VERSION ""

NS_ :

BS_:

BU_: VMCU TECU TACHO RECU_Virt IC3 HPCU EMS EBS DACU CIOM BBM ACM

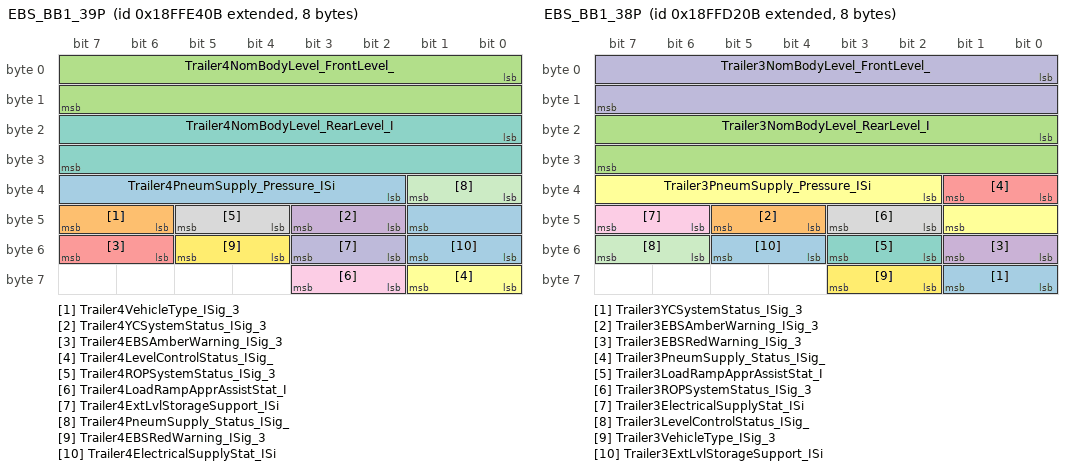
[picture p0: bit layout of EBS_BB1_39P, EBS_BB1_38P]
BO_ 2566906891 EBS_BB1_39P: 8 EBS
 SG_ Trailer4PneumSupply_Pressure_ISi : 34|8@1+ (5,0) [0|1275] "kPa"  IC3
 SG_ Trailer4VehicleType_ISig_3 : 46|2@1+ (1,0) [0|0] ""  IC3
 SG_ Trailer4NomBodyLevel_FrontLevel_ : 0|16@1+ (1,0) [0|65535] "mm"  IC3
 SG_ Trailer4YCSystemStatus_ISig_3 : 42|2@1+ (1,0) [0|0] ""  IC3
 SG_ Trailer4EBSAmberWarning_ISig_3 : 54|2@1+ (1,0) [0|0] ""  IC3
 SG_ Trailer4LevelControlStatus_ISig_ : 56|2@1+ (1,0) [0|0] ""  IC3
 SG_ Trailer4NomBodyLevel_RearLevel_I : 16|16@1+ (1,0) [0|65535] "mm"  IC3
 SG_ Trailer4ROPSystemStatus_ISig_3 : 44|2@1+ (1,0) [0|0] ""  IC3
 SG_ Trailer4LoadRampApprAssistStat_I : 58|2@1+ (1,0) [0|0] ""  IC3
 SG_ Trailer4ExtLvlStorageSupport_ISi : 50|2@1+ (1,0) [0|0] ""  IC3
 SG_ Trailer4PneumSupply_Status_ISig_ : 32|2@1+ (1,0) [0|0] ""  IC3
 SG_ Trailer4EBSRedWarning_ISig_3 : 52|2@1+ (1,0) [0|0] ""  IC3
 SG_ Trailer4ElectricalSupplyStat_ISi : 48|2@1+ (1,0) [0|0] ""  IC3

BO_ 2566902283 EBS_BB1_38P: 8 EBS
 SG_ Trailer3YCSystemStatus_ISig_3 : 56|2@1+ (1,0) [0|0] ""  IC3
 SG_ Trailer3EBSAmberWarning_ISig_3 : 44|2@1+ (1,0) [0|0] ""  IC3
 SG_ Trailer3NomBodyLevel_RearLevel_I : 16|16@1+ (1,0) [0|65535] "mm"  IC3
 SG_ Trailer3EBSRedWarning_ISig_3 : 48|2@1+ (1,0) [0|0] ""  IC3
 SG_ Trailer3PneumSupply_Status_ISig_ : 32|2@1+ (1,0) [0|0] ""  IC3
 SG_ Trailer3PneumSupply_Pressure_ISi : 34|8@1+ (5,0) [0|1275] "kPa"  IC3
 SG_ Trailer3LoadRampApprAssistStat_I : 50|2@1+ (1,0) [0|0] ""  IC3
 SG_ Trailer3ROPSystemStatus_ISig_3 : 42|2@1+ (1,0) [0|0] ""  IC3
 SG_ Trailer3ElectricalSupplyStat_ISi : 46|2@1+ (1,0) [0|0] ""  IC3
 SG_ Trailer3NomBodyLevel_FrontLevel_ : 0|16@1+ (1,0) [0|65535] "mm"  IC3
 SG_ Trailer3LevelControlStatus_ISig_ : 54|2@1+ (1,0) [0|0] ""  IC3
 SG_ Trailer3VehicleType_ISig_3 : 58|2@1+ (1,0) [0|0] ""  IC3
 SG_ Trailer3ExtLvlStorageSupport_ISi : 52|2@1+ (1,0) [0|0] ""  IC3

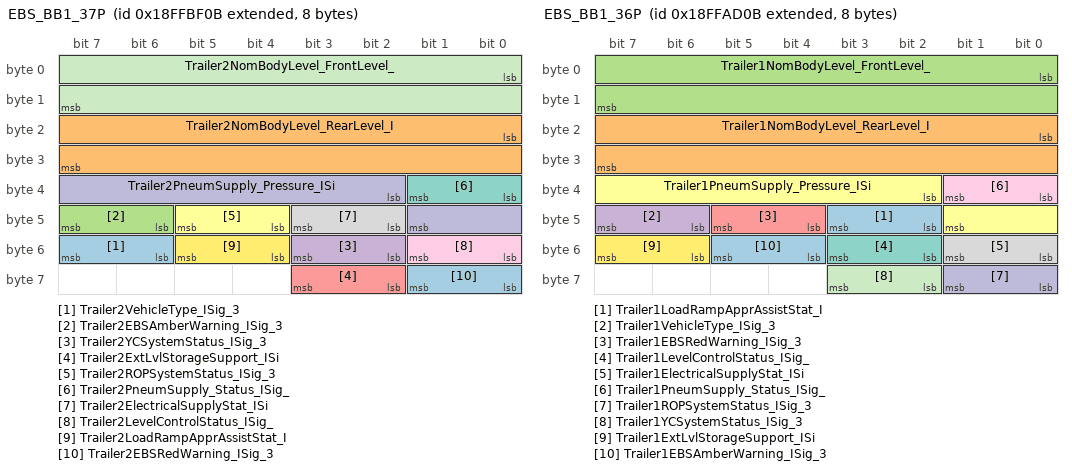
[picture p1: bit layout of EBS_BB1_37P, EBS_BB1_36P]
BO_ 2566897419 EBS_BB1_37P: 8 EBS
 SG_ Trailer2VehicleType_ISig_3 : 54|2@1+ (1,0) [0|0] ""  IC3
 SG_ Trailer2NomBodyLevel_RearLevel_I : 16|16@1+ (1,0) [0|65535] "mm"  IC3
 SG_ Trailer2EBSAmberWarning_ISig_3 : 46|2@1+ (1,0) [0|0] ""  IC3
 SG_ Trailer2YCSystemStatus_ISig_3 : 50|2@1+ (1,0) [0|0] ""  IC3
 SG_ Trailer2ExtLvlStorageSupport_ISi : 58|2@1+ (1,0) [0|0] ""  IC3
 SG_ Trailer2ROPSystemStatus_ISig_3 : 44|2@1+ (1,0) [0|0] ""  IC3
 SG_ Trailer2PneumSupply_Status_ISig_ : 32|2@1+ (1,0) [0|0] ""  IC3
 SG_ Trailer2ElectricalSupplyStat_ISi : 42|2@1+ (1,0) [0|0] ""  IC3
 SG_ Trailer2LevelControlStatus_ISig_ : 48|2@1+ (1,0) [0|0] ""  IC3
 SG_ Trailer2PneumSupply_Pressure_ISi : 34|8@1+ (5,0) [0|1275] "kPa"  IC3
 SG_ Trailer2NomBodyLevel_FrontLevel_ : 0|16@1+ (1,0) [0|65535] "mm"  IC3
 SG_ Trailer2LoadRampApprAssistStat_I : 52|2@1+ (1,0) [0|0] ""  IC3
 SG_ Trailer2EBSRedWarning_ISig_3 : 56|2@1+ (1,0) [0|0] ""  IC3

BO_ 2566892811 EBS_BB1_36P: 8 EBS
 SG_ Trailer1LoadRampApprAssistStat_I : 42|2@1+ (1,0) [0|0] ""  IC3
 SG_ Trailer1NomBodyLevel_RearLevel_I : 16|16@1+ (1,0) [0|65535] "mm"  IC3
 SG_ Trailer1NomBodyLevel_FrontLevel_ : 0|16@1+ (1,0) [0|65535] "mm"  IC3
 SG_ Trailer1VehicleType_ISig_3 : 46|2@1+ (1,0) [0|0] ""  IC3
 SG_ Trailer1EBSRedWarning_ISig_3 : 44|2@1+ (1,0) [0|0] ""  IC3
 SG_ Trailer1PneumSupply_Pressure_ISi : 34|8@1+ (5,0) [0|1275] "kPa"  IC3
 SG_ Trailer1LevelControlStatus_ISig_ : 50|2@1+ (1,0) [0|0] ""  IC3
 SG_ Trailer1ElectricalSupplyStat_ISi : 48|2@1+ (1,0) [0|0] ""  IC3
 SG_ Trailer1PneumSupply_Status_ISig_ : 32|2@1+ (1,0) [0|0] ""  IC3
 SG_ Trailer1ROPSystemStatus_ISig_3 : 56|2@1+ (1,0) [0|0] ""  IC3
 SG_ Trailer1YCSystemStatus_ISig_3 : 58|2@1+ (1,0) [0|0] ""  IC3
 SG_ Trailer1ExtLvlStorageSupport_ISi : 54|2@1+ (1,0) [0|0] ""  IC3
 SG_ Trailer1EBSAmberWarning_ISig_3 : 52|2@1+ (1,0) [0|0] ""  IC3

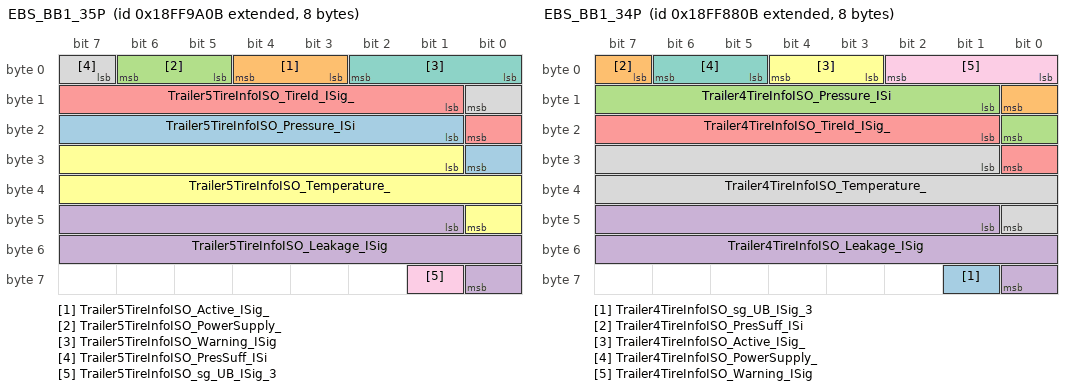
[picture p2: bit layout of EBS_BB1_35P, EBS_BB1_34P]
BO_ 2566887947 EBS_BB1_35P: 8 EBS
 SG_ Trailer5TireInfoISO_Pressure_ISi : 17|8@1+ (10,0) [0|2550] "kPa"  IC3
 SG_ Trailer5TireInfoISO_Active_ISig_ : 3|2@1+ (1,0) [0|0] ""  IC3
 SG_ Trailer5TireInfoISO_PowerSupply_ : 5|2@1+ (1,0) [0|0] ""  IC3
 SG_ Trailer5TireInfoISO_Leakage_ISig : 41|16@1+ (0.1,0) [0|6553.5] "Pa_per_s"  IC3
 SG_ Trailer5TireInfoISO_TireId_ISig_ : 9|8@1+ (1,0) [0|255] "NotApplicable"  IC3
 SG_ Trailer5TireInfoISO_Temperature_ : 25|16@1+ (0.03125,-273) [-273|1774.96875] "DegreeC"  IC3
 SG_ Trailer5TireInfoISO_Warning_ISig : 0|3@1+ (1,0) [0|0] ""  IC3
 SG_ Trailer5TireInfoISO_PresSuff_ISi : 7|2@1+ (1,0) [0|0] ""  IC3
 SG_ Trailer5TireInfoISO_sg_UB_ISig_3 : 57|1@1+ (1,0) [0|0] ""  IC3

BO_ 2566883339 EBS_BB1_34P: 8 EBS
 SG_ Trailer4TireInfoISO_sg_UB_ISig_3 : 57|1@1+ (1,0) [0|0] ""  IC3
 SG_ Trailer4TireInfoISO_PresSuff_ISi : 7|2@1+ (1,0) [0|0] ""  IC3
 SG_ Trailer4TireInfoISO_Pressure_ISi : 9|8@1+ (10,0) [0|2550] "kPa"  IC3
 SG_ Trailer4TireInfoISO_Leakage_ISig : 41|16@1+ (0.1,0) [0|6553.5] "Pa_per_s"  IC3
 SG_ Trailer4TireInfoISO_TireId_ISig_ : 17|8@1+ (1,0) [0|255] "NotApplicable"  IC3
 SG_ Trailer4TireInfoISO_Active_ISig_ : 3|2@1+ (1,0) [0|0] ""  IC3
 SG_ Trailer4TireInfoISO_PowerSupply_ : 5|2@1+ (1,0) [0|0] ""  IC3
 SG_ Trailer4TireInfoISO_Temperature_ : 25|16@1+ (0.03125,-273) [-273|1774.96875] "DegreeC"  IC3
 SG_ Trailer4TireInfoISO_Warning_ISig : 0|3@1+ (1,0) [0|0] ""  IC3

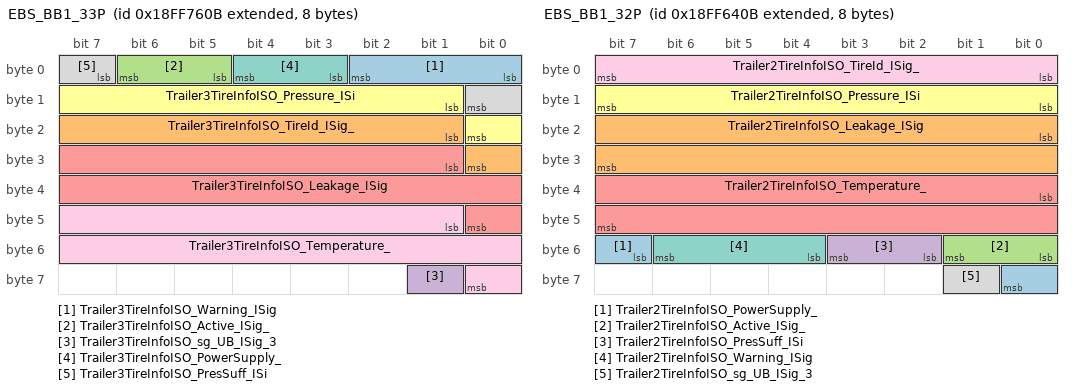
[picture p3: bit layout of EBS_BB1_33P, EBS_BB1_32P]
BO_ 2566878731 EBS_BB1_33P: 8 EBS
 SG_ Trailer3TireInfoISO_Warning_ISig : 0|3@1+ (1,0) [0|0] ""  IC3
 SG_ Trailer3TireInfoISO_TireId_ISig_ : 17|8@1+ (1,0) [0|255] "NotApplicable"  IC3
 SG_ Trailer3TireInfoISO_Active_ISig_ : 5|2@1+ (1,0) [0|0] ""  IC3
 SG_ Trailer3TireInfoISO_sg_UB_ISig_3 : 57|1@1+ (1,0) [0|0] ""  IC3
 SG_ Trailer3TireInfoISO_Leakage_ISig : 25|16@1+ (0.1,0) [0|6553.5] "Pa_per_s"  IC3
 SG_ Trailer3TireInfoISO_Pressure_ISi : 9|8@1+ (10,0) [0|2550] "kPa"  IC3
 SG_ Trailer3TireInfoISO_PowerSupply_ : 3|2@1+ (1,0) [0|0] ""  IC3
 SG_ Trailer3TireInfoISO_PresSuff_ISi : 7|2@1+ (1,0) [0|0] ""  IC3
 SG_ Trailer3TireInfoISO_Temperature_ : 41|16@1+ (0.03125,-273) [-273|1774.96875] "DegreeC"  IC3

BO_ 2566874123 EBS_BB1_32P: 8 EBS
 SG_ Trailer2TireInfoISO_PowerSupply_ : 55|2@1+ (1,0) [0|0] ""  IC3
 SG_ Trailer2TireInfoISO_Leakage_ISig : 16|16@1+ (0.1,0) [0|6553.5] "Pa_per_s"  IC3
 SG_ Trailer2TireInfoISO_Active_ISig_ : 48|2@1+ (1,0) [0|0] ""  IC3
 SG_ Trailer2TireInfoISO_PresSuff_ISi : 50|2@1+ (1,0) [0|0] ""  IC3
 SG_ Trailer2TireInfoISO_Temperature_ : 32|16@1+ (0.03125,-273) [-273|1774.96875] "DegreeC"  IC3
 SG_ Trailer2TireInfoISO_Pressure_ISi : 8|8@1+ (10,0) [0|2550] "kPa"  IC3
 SG_ Trailer2TireInfoISO_Warning_ISig : 52|3@1+ (1,0) [0|0] ""  IC3
 SG_ Trailer2TireInfoISO_sg_UB_ISig_3 : 57|1@1+ (1,0) [0|0] ""  IC3
 SG_ Trailer2TireInfoISO_TireId_ISig_ : 0|8@1+ (1,0) [0|255] "NotApplicable"  IC3

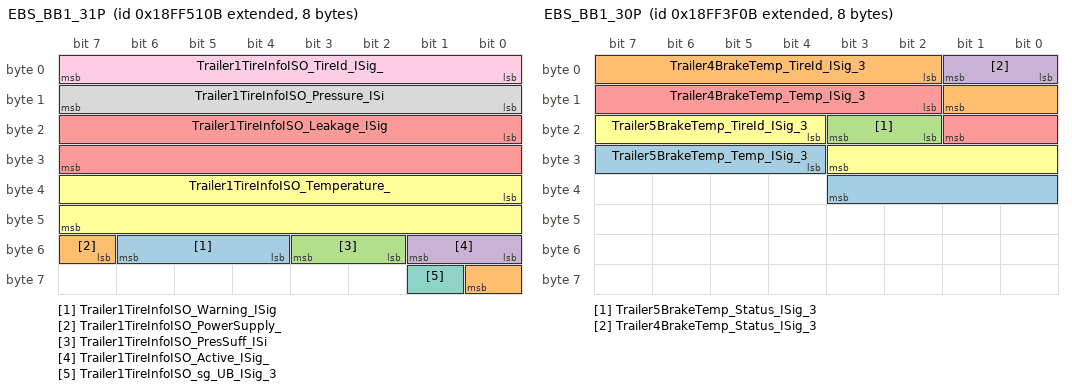
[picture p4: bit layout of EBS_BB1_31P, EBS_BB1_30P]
BO_ 2566869259 EBS_BB1_31P: 8 EBS
 SG_ Trailer1TireInfoISO_Warning_ISig : 52|3@1+ (1,0) [0|0] ""  IC3
 SG_ Trailer1TireInfoISO_PowerSupply_ : 55|2@1+ (1,0) [0|0] ""  IC3
 SG_ Trailer1TireInfoISO_PresSuff_ISi : 50|2@1+ (1,0) [0|0] ""  IC3
 SG_ Trailer1TireInfoISO_Active_ISig_ : 48|2@1+ (1,0) [0|0] ""  IC3
 SG_ Trailer1TireInfoISO_Leakage_ISig : 16|16@1+ (0.1,0) [0|6553.5] "Pa_per_s"  IC3
 SG_ Trailer1TireInfoISO_Temperature_ : 32|16@1+ (0.03125,-273) [-273|1774.96875] "DegreeC"  IC3
 SG_ Trailer1TireInfoISO_sg_UB_ISig_3 : 57|1@1+ (1,0) [0|0] ""  IC3
 SG_ Trailer1TireInfoISO_Pressure_ISi : 8|8@1+ (10,0) [0|2550] "kPa"  IC3
 SG_ Trailer1TireInfoISO_TireId_ISig_ : 0|8@1+ (1,0) [0|255] "NotApplicable"  IC3

BO_ 2566864651 EBS_BB1_30P: 8 EBS
 SG_ Trailer5BrakeTemp_Temp_ISig_3 : 28|8@1+ (10,0) [0|2550] "DegreeC"  IC3
 SG_ Trailer4BrakeTemp_TireId_ISig_3 : 2|8@1+ (1,0) [0|255] "NotApplicable"  IC3
 SG_ Trailer5BrakeTemp_Status_ISig_3 : 18|2@1+ (1,0) [0|0] ""  IC3
 SG_ Trailer4BrakeTemp_Status_ISig_3 : 0|2@1+ (1,0) [0|0] ""  IC3
 SG_ Trailer4BrakeTemp_Temp_ISig_3 : 10|8@1+ (10,0) [0|2550] "DegreeC"  IC3
 SG_ Trailer5BrakeTemp_TireId_ISig_3 : 20|8@1+ (1,0) [0|255] "NotApplicable"  IC3

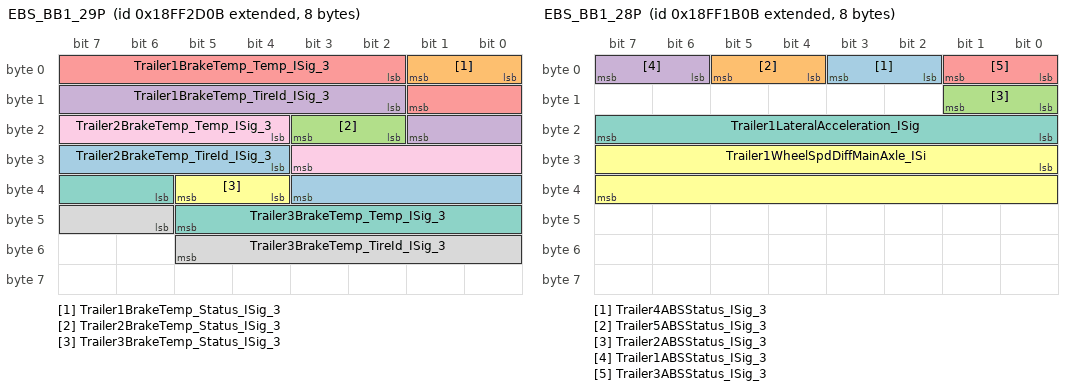
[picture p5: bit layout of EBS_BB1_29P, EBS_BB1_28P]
BO_ 2566860043 EBS_BB1_29P: 8 EBS
 SG_ Trailer2BrakeTemp_TireId_ISig_3 : 28|8@1+ (1,0) [0|255] "NotApplicable"  IC3
 SG_ Trailer1BrakeTemp_Status_ISig_3 : 0|2@1+ (1,0) [0|0] ""  IC3
 SG_ Trailer2BrakeTemp_Status_ISig_3 : 18|2@1+ (1,0) [0|0] ""  IC3
 SG_ Trailer1BrakeTemp_TireId_ISig_3 : 10|8@1+ (1,0) [0|255] "NotApplicable"  IC3
 SG_ Trailer1BrakeTemp_Temp_ISig_3 : 2|8@1+ (10,0) [0|2550] "DegreeC"  IC3
 SG_ Trailer3BrakeTemp_Status_ISig_3 : 36|2@1+ (1,0) [0|0] ""  IC3
 SG_ Trailer3BrakeTemp_Temp_ISig_3 : 38|8@1+ (10,0) [0|2550] "DegreeC"  IC3
 SG_ Trailer3BrakeTemp_TireId_ISig_3 : 46|8@1+ (1,0) [0|255] "NotApplicable"  IC3
 SG_ Trailer2BrakeTemp_Temp_ISig_3 : 20|8@1+ (10,0) [0|2550] "DegreeC"  IC3

BO_ 2566855435 EBS_BB1_28P: 8 EBS
 SG_ Trailer4ABSStatus_ISig_3 : 2|2@1+ (1,0) [0|0] ""  IC3
 SG_ Trailer5ABSStatus_ISig_3 : 4|2@1+ (1,0) [0|0] ""  IC3
 SG_ Trailer2ABSStatus_ISig_3 : 8|2@1+ (1,0) [0|0] ""  IC3
 SG_ Trailer1ABSStatus_ISig_3 : 6|2@1+ (1,0) [0|0] ""  IC3
 SG_ Trailer3ABSStatus_ISig_3 : 0|2@1+ (1,0) [0|0] ""  IC3
 SG_ Trailer1WheelSpdDiffMainAxle_ISi : 24|16@1+ (0.00390625,-125) [-125|130.99609375] "Km_per_h"  IC3
 SG_ Trailer1LateralAcceleration_ISig : 16|8@1+ (0.1,-12.5) [-12.5|13] "m_per_s_squared"  IC3

BO_ 2566850827 EBS_BB1_27P: 8 EBS
 SG_ Trailer5NormalLevelStorStat_ISig : 6|2@1+ (1,0) [0|0] ""  IC3
 SG_ Trailer4TractionHelp_ISig_3 : 42|2@1+ (1,0) [0|0] ""  IC3
 SG_ Trailer2TractionHelp_ISig_3 : 4|2@1+ (1,0) [0|0] ""  IC3
 SG_ Trailer3StopLevelChangeAck_ISig_ : 44|2@1+ (1,0) [0|0] ""  IC3
 SG_ Trailer4LevelChangeFrontAxle_ISi : 40|2@1+ (1,0) [0|0] ""  IC3
 SG_ Trailer1NormalLevelStorStat_ISig : 10|2@1+ (1,0) [0|0] ""  IC3
 SG_ Trailer1StopLevelChangeAck_ISig_ : 50|2@1+ (1,0) [0|0] ""  IC3
 SG_ Trailer3LevelChangeFrontAxle_ISi : 38|2@1+ (1,0) [0|0] ""  IC3
 SG_ Trailer5RampLevelStorStat_ISig_3 : 8|2@1+ (1,0) [0|0] ""  IC3
 SG_ Trailer4LevelChangeRearAxle_ISig : 36|2@1+ (1,0) [0|0] ""  IC3
 SG_ Trailer2LevelChangeFrontAxle_ISi : 34|2@1+ (1,0) [0|0] ""  IC3
 SG_ Trailer2RampLevelStorStat_ISig_3 : 14|2@1+ (1,0) [0|0] ""  IC3
 SG_ Trailer4StopLevelChangeAck_ISig_ : 18|2@1+ (1,0) [0|0] ""  IC3
 SG_ Trailer3NormalLevelStorStat_ISig : 56|2@1+ (1,0) [0|0] ""  IC3
 SG_ Trailer1TractionHelp_ISig_3 : 20|2@1+ (1,0) [0|0] ""  IC3
 SG_ Trailer1LevelChangeRearAxle_ISig : 54|2@1+ (1,0) [0|0] ""  IC3
 SG_ Trailer5LevelChangeFrontAxle_ISi : 26|2@1+ (1,0) [0|0] ""  IC3
 SG_ Trailer5StopLevelChangeAck_ISig_ : 24|2@1+ (1,0) [0|0] ""  IC3
 SG_ Trailer5TractionHelp_ISig_3 : 58|2@1+ (1,0) [0|0] ""  IC3
 SG_ Trailer3RampLevelStorStat_ISig_3 : 12|2@1+ (1,0) [0|0] ""  IC3
 SG_ Trailer2LevelChangeRearAxle_ISig : 30|2@1+ (1,0) [0|0] ""  IC3
 SG_ Trailer2StopLevelChangeAck_ISig_ : 22|2@1+ (1,0) [0|0] ""  IC3
 SG_ Trailer3TractionHelp_ISig_3 : 32|2@1+ (1,0) [0|0] ""  IC3
 SG_ Trailer4RampLevelStorStat_ISig_3 : 28|2@1+ (1,0) [0|0] ""  IC3
 SG_ Trailer1RampLevelStorStat_ISig_3 : 52|2@1+ (1,0) [0|0] ""  IC3
 SG_ Trailer1LevelChangeFrontAxle_ISi : 16|2@1+ (1,0) [0|0] ""  IC3
 SG_ Trailer3LevelChangeRearAxle_ISig : 0|2@1+ (1,0) [0|0] ""  IC3
 SG_ Trailer5LevelChangeRearAxle_ISig : 48|2@1+ (1,0) [0|0] ""  IC3
 SG_ Trailer2NormalLevelStorStat_ISig : 46|2@1+ (1,0) [0|0] ""  IC3
 SG_ Trailer4NormalLevelStorStat_ISig : 2|2@1+ (1,0) [0|0] ""  IC3

BO_ 2566899211 EBS_BB1_26P: 8 EBS
 SG_ Trailer4TowedVehStat_DetectStat : 24|2@1+ (1,0) [0|0] ""  VMCU
 SG_ Trailer5TowedVehStat_BrakeSystem : 36|2@1+ (1,0) [0|0] ""  VMCU
 SG_ Trailer2TowedVehStat_DetectSupp : 14|2@1+ (1,0) [0|0] ""  VMCU
 SG_ Trailer1TowedVehStat_CANAvail : 2|2@1+ (1,0) [0|0] ""  VMCU
 SG_ Trailer2TowedVehStat_DetectStat : 8|2@1+ (1,0) [0|0] ""  VMCU
 SG_ Trailer2TowedVehStat_BrakeSystem : 12|2@1+ (1,0) [0|0] ""  VMCU
 SG_ Trailer2TowedVehStat_CANAvail : 10|2@1+ (1,0) [0|0] ""  VMCU
 SG_ Trailer3TowedVehStat_BrakeSystem : 20|2@1+ (1,0) [0|0] ""  VMCU
 SG_ Trailer3TowedVehStat_DetectStat : 16|2@1+ (1,0) [0|0] ""  VMCU
 SG_ Trailer5TowedVehStat_DetectSupp : 38|2@1+ (1,0) [0|0] ""  VMCU
 SG_ Trailer4TowedVehStat_DetectSupp : 30|2@1+ (1,0) [0|0] ""  VMCU
 SG_ Trailer5TowedVehStat_DetectStat : 32|2@1+ (1,0) [0|0] ""  VMCU
 SG_ Trailer3TowedVehStat_DetectSupp : 22|2@1+ (1,0) [0|0] ""  VMCU
 SG_ Trailer1TowedVehStat_DetectSupp : 6|2@1+ (1,0) [0|0] ""  VMCU
 SG_ Trailer4TowedVehStat_CANAvail : 26|2@1+ (1,0) [0|0] ""  VMCU
 SG_ Trailer1TowedVehStat_BrakeSystem : 4|2@1+ (1,0) [0|0] ""  VMCU
 SG_ Trailer5TowedVehStat_CANAvail : 34|2@1+ (1,0) [0|0] ""  VMCU
 SG_ Trailer4TowedVehStat_BrakeSystem : 28|2@1+ (1,0) [0|0] ""  VMCU
 SG_ Trailer1TowedVehStat_DetectStat : 0|2@1+ (1,0) [0|0] ""  VMCU
 SG_ Trailer3TowedVehStat_CANAvail : 18|2@1+ (1,0) [0|0] ""  VMCU

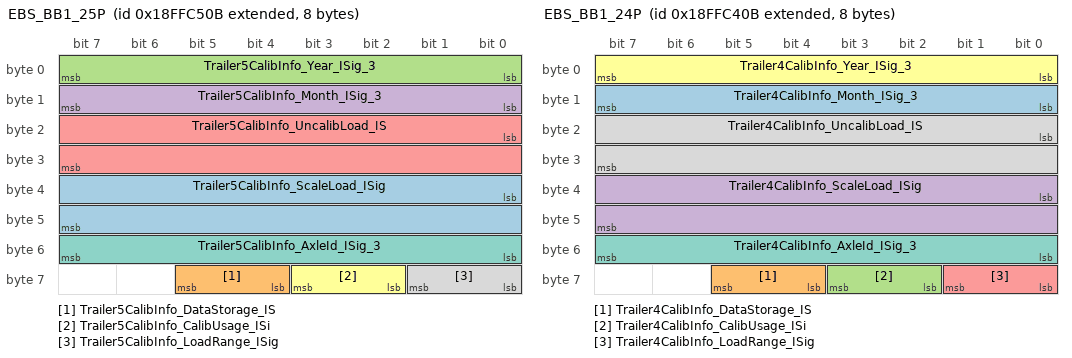
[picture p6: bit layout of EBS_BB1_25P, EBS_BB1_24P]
BO_ 2566898955 EBS_BB1_25P: 8 EBS
 SG_ Trailer5CalibInfo_ScaleLoad_ISig : 32|16@1+ (1,0) [0|65535] "kg"  IC3,VMCU
 SG_ Trailer5CalibInfo_DataStorage_IS : 60|2@1+ (1,0) [0|0] ""  VMCU,IC3
 SG_ Trailer5CalibInfo_Year_ISig_3 : 0|8@1+ (1,1985) [1985|2240] "Years"  IC3,VMCU
 SG_ Trailer5CalibInfo_Month_ISig_3 : 8|8@1+ (1,0) [0|255] "Months"  VMCU,IC3
 SG_ Trailer5CalibInfo_UncalibLoad_IS : 16|16@1+ (1,0) [0|65535] "kg"  IC3,VMCU
 SG_ Trailer5CalibInfo_CalibUsage_ISi : 58|2@1+ (1,0) [0|0] ""  VMCU,IC3
 SG_ Trailer5CalibInfo_AxleId_ISig_3 : 48|8@1+ (1,0) [0|255] "NotApplicable"  VMCU,IC3
 SG_ Trailer5CalibInfo_LoadRange_ISig : 56|2@1+ (1,0) [0|0] ""  IC3,VMCU

BO_ 2566898699 EBS_BB1_24P: 8 EBS
 SG_ Trailer4CalibInfo_Month_ISig_3 : 8|8@1+ (1,0) [0|255] "Months"  IC3,VMCU
 SG_ Trailer4CalibInfo_DataStorage_IS : 60|2@1+ (1,0) [0|0] ""  IC3,VMCU
 SG_ Trailer4CalibInfo_CalibUsage_ISi : 58|2@1+ (1,0) [0|0] ""  IC3,VMCU
 SG_ Trailer4CalibInfo_ScaleLoad_ISig : 32|16@1+ (1,0) [0|65535] "kg"  VMCU,IC3
 SG_ Trailer4CalibInfo_LoadRange_ISig : 56|2@1+ (1,0) [0|0] ""  VMCU,IC3
 SG_ Trailer4CalibInfo_Year_ISig_3 : 0|8@1+ (1,1985) [1985|2240] "Years"  IC3,VMCU
 SG_ Trailer4CalibInfo_AxleId_ISig_3 : 48|8@1+ (1,0) [0|255] "NotApplicable"  VMCU,IC3
 SG_ Trailer4CalibInfo_UncalibLoad_IS : 16|16@1+ (1,0) [0|65535] "kg"  IC3,VMCU

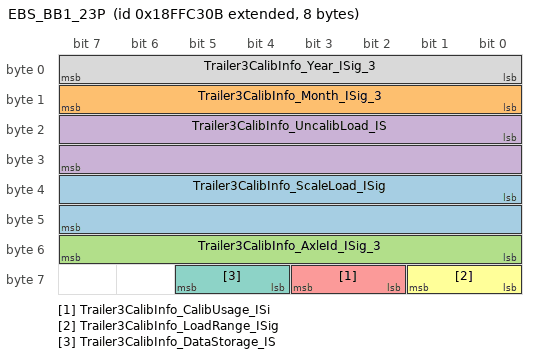
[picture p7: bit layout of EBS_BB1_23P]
BO_ 2566898443 EBS_BB1_23P: 8 EBS
 SG_ Trailer3CalibInfo_ScaleLoad_ISig : 32|16@1+ (1,0) [0|65535] "kg"  IC3,VMCU
 SG_ Trailer3CalibInfo_Month_ISig_3 : 8|8@1+ (1,0) [0|255] "Months"  VMCU,IC3
 SG_ Trailer3CalibInfo_AxleId_ISig_3 : 48|8@1+ (1,0) [0|255] "NotApplicable"  VMCU,IC3
 SG_ Trailer3CalibInfo_UncalibLoad_IS : 16|16@1+ (1,0) [0|65535] "kg"  IC3,VMCU
 SG_ Trailer3CalibInfo_CalibUsage_ISi : 58|2@1+ (1,0) [0|0] ""  IC3,VMCU
 SG_ Trailer3CalibInfo_LoadRange_ISig : 56|2@1+ (1,0) [0|0] ""  IC3,VMCU
 SG_ Trailer3CalibInfo_DataStorage_IS : 60|2@1+ (1,0) [0|0] ""  IC3,VMCU
 SG_ Trailer3CalibInfo_Year_ISig_3 : 0|8@1+ (1,1985) [1985|2240] "Years"  VMCU,IC3

CM_ SG_ 2566906891 Trailer4PneumSupply_Pressure_ISi "254 Error ; 255 Not available";
CM_ SG_ 2566902283 Trailer3PneumSupply_Pressure_ISi "254 Error ; 255 Not available";
CM_ SG_ 2566897419 Trailer2PneumSupply_Pressure_ISi "254 Error ; 255 Not available";
CM_ SG_ 2566892811 Trailer1PneumSupply_Pressure_ISi "254 Error ; 255 Not available";
CM_ SG_ 2566887947 Trailer5TireInfoISO_Pressure_ISi "251-253 Spare; 254 Error; 255 NotAvailable;";
CM_ SG_ 2566887947 Trailer5TireInfoISO_Leakage_ISig "64256-65023 Spare; 65024-65279 Error; 65280-65535 NotAvailable;";
CM_ SG_ 2566887947 Trailer5TireInfoISO_Temperature_ "64256-65023 Spare; 65024-65279 Error; 65280-65535 NotAvailable;";
CM_ SG_ 2566883339 Trailer4TireInfoISO_Pressure_ISi "251-253 Spare; 254 Error; 255 NotAvailable;";
CM_ SG_ 2566883339 Trailer4TireInfoISO_Leakage_ISig "64256-65023 Spare; 65024-65279 Error; 65280-65535 NotAvailable;";
CM_ SG_ 2566883339 Trailer4TireInfoISO_Temperature_ "64256-65023 Spare; 65024-65279 Error; 65280-65535 NotAvailable;";
CM_ SG_ 2566878731 Trailer3TireInfoISO_Leakage_ISig "64256-65023 Spare; 65024-65279 Error; 65280-65535 NotAvailable;";
CM_ SG_ 2566878731 Trailer3TireInfoISO_Pressure_ISi "251-253 Spare; 254 Error; 255 NotAvailable;";
CM_ SG_ 2566878731 Trailer3TireInfoISO_Temperature_ "64256-65023 Spare; 65024-65279 Error; 65280-65535 NotAvailable;";
CM_ SG_ 2566874123 Trailer2TireInfoISO_Leakage_ISig "64256-65023 Spare; 65024-65279 Error; 65280-65535 NotAvailable;";
CM_ SG_ 2566874123 Trailer2TireInfoISO_Temperature_ "64256-65023 Spare; 65024-65279 Error; 65280-65535 NotAvailable;";
CM_ SG_ 2566874123 Trailer2TireInfoISO_Pressure_ISi "251-253 Spare; 254 Error; 255 NotAvailable;";
CM_ SG_ 2566869259 Trailer1TireInfoISO_Leakage_ISig "64256-65023 Spare; 65024-65279 Error; 65280-65535 NotAvailable;";
CM_ SG_ 2566869259 Trailer1TireInfoISO_Temperature_ "64256-65023 Spare; 65024-65279 Error; 65280-65535 NotAvailable;";
CM_ SG_ 2566869259 Trailer1TireInfoISO_Pressure_ISi "251-253 Spare; 254 Error; 255 NotAvailable;";
CM_ SG_ 2566864651 Trailer5BrakeTemp_Temp_ISig_3 "254 Error; 255 Not Available";
CM_ SG_ 2566864651 Trailer4BrakeTemp_Temp_ISig_3 "254 Error; 255 Not Available";
CM_ SG_ 2566860043 Trailer1BrakeTemp_Temp_ISig_3 "254 Error; 255 Not Available";
CM_ SG_ 2566860043 Trailer3BrakeTemp_Temp_ISig_3 "254 Error; 255 Not Available";
CM_ SG_ 2566860043 Trailer2BrakeTemp_Temp_ISig_3 "254 Error; 255 Not Available";
CM_ SG_ 2566855435 Trailer1LateralAcceleration_ISig "254 Error; 255 Not available";
CM_ SG_ 2566898955 Trailer5CalibInfo_ScaleLoad_ISig "10000-65023: Spare, 65024-65279: Error, 65280-65535: NotAvailable";
CM_ SG_ 2566898955 Trailer5CalibInfo_Year_ISig_3 "254 Error ; 255 Not available";
CM_ SG_ 2566898955 Trailer5CalibInfo_Month_ISig_3 "254 Error ; 255 Not available";
CM_ SG_ 2566898955 Trailer5CalibInfo_UncalibLoad_IS "10000-65023: Spare, 65024-65279: Error, 65280-65535: NotAvailable";
CM_ SG_ 2566898699 Trailer4CalibInfo_Month_ISig_3 "254 Error ; 255 Not available";
CM_ SG_ 2566898699 Trailer4CalibInfo_ScaleLoad_ISig "10000-65023: Spare, 65024-65279: Error, 65280-65535: NotAvailable";
CM_ SG_ 2566898699 Trailer4CalibInfo_Year_ISig_3 "254 Error ; 255 Not available";
CM_ SG_ 2566898699 Trailer4CalibInfo_UncalibLoad_IS "10000-65023: Spare, 65024-65279: Error, 65280-65535: NotAvailable";
CM_ SG_ 2566898443 Trailer3CalibInfo_ScaleLoad_ISig "10000-65023: Spare, 65024-65279: Error, 65280-65535: NotAvailable";
CM_ SG_ 2566898443 Trailer3CalibInfo_Month_ISig_3 "254 Error ; 255 Not available";
CM_ SG_ 2566898443 Trailer3CalibInfo_UncalibLoad_IS "10000-65023: Spare, 65024-65279: Error, 65280-65535: NotAvailable";
CM_ SG_ 2566898443 Trailer3CalibInfo_Year_ISig_3 "254 Error ; 255 Not available";
BA_DEF_ BO_  "GenMsgStartDelayTime" INT 0 0;
BA_DEF_ BO_  "GenMsgDelayTime" INT 0 0;
BA_DEF_ BO_  "GenMsgNrOfRepetition" INT 0 0;
BA_DEF_ BO_  "GenMsgCycleTimeFast" INT 0 0;
BA_DEF_ BO_  "GenMsgCycleTime" INT 0 0;
BA_DEF_ BO_  "GenMsgSendType" ENUM  "Cyclic","NotUsed","NotUsed","NotUsed","NotUsed","NotUsed","NotUsed","IfActive","NoMsgSendType","NotUsed";
BA_DEF_ SG_  "GenSigStartValue" INT 0 0;
BA_DEF_ SG_  "GenSigCycleTimeActive" INT 0 0;
BA_DEF_ SG_  "GenSigCycleTime" INT 0 0;
BA_DEF_ SG_  "GenSigSendType" ENUM  "Cyclic","OnWrite","OnWriteWithRepetition","OnChange","OnChangeWithRepetition","IfActive","IfActiveWithRepetition","NoSigSendType","NotUsed","NotUsed","NotUsed","NotUsed","NotUsed";
BA_DEF_ BO_  "VFrameFormat" ENUM  "StandardCAN","ExtendedCAN","reserved","J1939PG","reserved","reserved","reserved","reserved","reserved","reserved","reserved","reserved","reserved","reserved","StandardCAN_FD","ExtendedCAN_FD";
BA_DEF_ BO_  "TpJ1939VarDlc" ENUM  "No","Yes";
BA_DEF_ SG_  "SigType" ENUM  "Default","Range","RangeSigned","ASCII","Discrete","Control","ReferencePGN","DTC","StringDelimiter","StringLength","StringLengthControl";
BA_DEF_ SG_  "SeToolVersion_SIGNAL" STRING ;
BA_DEF_ SG_  "SeToolUniqueID_SIGNAL" STRING ;
BA_DEF_ SG_  "SeToolOwnerSigGroup_SIGNAL" STRING ;
BA_DEF_ SG_  "SeToolOwnerSigGroupID_SIGNAL" STRING ;
BA_DEF_ SG_  "SeToolName_SIGNAL" STRING ;
BA_DEF_ SG_  "SeToolItemID_SIGNAL" STRING ;
BA_DEF_ SG_  "SeToolAncestorID_SIGNAL" STRING ;
BA_DEF_ SG_  "SPN" INT 0 524287;
BA_DEF_ SG_  "Platform_VMCU1_Sig" ENUM  "No","Yes";
BA_DEF_ SG_  "Platform_FactoryIf_Sig" ENUM  "No","Yes";
BA_DEF_ SG_  "NeedsUpdateBit" ENUM  "No","Yes";
BA_DEF_ SG_  "GenSigMaxLatency" INT 0 65535;
BA_DEF_ SG_  "GenSigILSupport" ENUM  "Yes","No";
BA_DEF_ BO_  "GenMsgILSupport" ENUM  "No","Yes";
BA_DEF_ BO_  "DiagUUDTResponse" ENUM  "No","Yes";
BA_DEF_ BO_  "DiagState" ENUM  "No","Yes";
BA_DEF_ BO_  "DiagResponse" ENUM  "No","Yes";
BA_DEF_ BO_  "DiagRequest" ENUM  "No","Yes";
BA_DEF_ BO_  "DiagConnection" HEX 0 65535;
BA_DEF_ BO_  "CanTpFcFrameId" HEX 0 2147483647;
BA_DEF_ BO_  "CanTpBs" INT 0 255;
BA_DEF_ SG_  "SystemSignalLongSymbol" STRING ;
BA_DEF_REL_ BU_SG_REL_  "GenSigTimeoutTime" INT 0 65535;
BA_DEF_REL_ BU_SG_REL_  "GenSigFirstTimeoutTime" INT 0 65535;
BA_DEF_DEF_  "GenMsgStartDelayTime" 0;
BA_DEF_DEF_  "GenMsgDelayTime" 0;
BA_DEF_DEF_  "GenMsgNrOfRepetition" 0;
BA_DEF_DEF_  "GenMsgCycleTimeFast" 0;
BA_DEF_DEF_  "GenMsgCycleTime" 0;
BA_DEF_DEF_  "GenMsgSendType" "Cyclic";
BA_DEF_DEF_  "GenSigStartValue" 0;
BA_DEF_DEF_  "GenSigCycleTimeActive" 0;
BA_DEF_DEF_  "GenSigCycleTime" 0;
BA_DEF_DEF_  "GenSigSendType" "Cyclic";
BA_DEF_DEF_  "VFrameFormat" "ExtendedCAN";
BA_DEF_DEF_  "TpJ1939VarDlc" "No";
BA_DEF_DEF_  "SigType" "Default";
BA_DEF_DEF_  "SeToolVersion_SIGNAL" "";
BA_DEF_DEF_  "SeToolUniqueID_SIGNAL" "";
BA_DEF_DEF_  "SeToolOwnerSigGroup_SIGNAL" "";
BA_DEF_DEF_  "SeToolOwnerSigGroupID_SIGNAL" "";
BA_DEF_DEF_  "SeToolName_SIGNAL" "";
BA_DEF_DEF_  "SeToolItemID_SIGNAL" "";
BA_DEF_DEF_  "SeToolAncestorID_SIGNAL" "";
BA_DEF_DEF_  "SPN" 0;
BA_DEF_DEF_  "Platform_VMCU1_Sig" "No";
BA_DEF_DEF_  "Platform_FactoryIf_Sig" "No";
BA_DEF_DEF_  "NeedsUpdateBit" "No";
BA_DEF_DEF_  "GenSigMaxLatency" 0;
BA_DEF_DEF_  "GenSigILSupport" "Yes";
BA_DEF_DEF_  "GenMsgILSupport" "Yes";
BA_DEF_DEF_  "DiagUUDTResponse" "No";
BA_DEF_DEF_  "DiagState" "No";
BA_DEF_DEF_  "DiagResponse" "No";
BA_DEF_DEF_  "DiagRequest" "No";
BA_DEF_DEF_  "DiagConnection" 0;
BA_DEF_DEF_  "CanTpFcFrameId" 2147483647;
BA_DEF_DEF_  "CanTpBs" 255;
BA_DEF_DEF_REL_ "GenSigTimeoutTime" 0;
BA_DEF_DEF_REL_ "GenSigFirstTimeoutTime" 0;
BA_DEF_DEF_  "SystemSignalLongSymbol" "";
BA_ "GenMsgCycleTime" BO_ 2566906891 1000;
BA_ "GenMsgStartDelayTime" BO_ 2566906891 390;
BA_ "VFrameFormat" BO_ 2566906891 3;
BA_ "GenMsgCycleTime" BO_ 2566902283 1000;
BA_ "GenMsgStartDelayTime" BO_ 2566902283 380;
BA_ "VFrameFormat" BO_ 2566902283 3;
BA_ "GenMsgCycleTime" BO_ 2566897419 1000;
BA_ "GenMsgStartDelayTime" BO_ 2566897419 340;
BA_ "VFrameFormat" BO_ 2566897419 3;
BA_ "GenMsgCycleTime" BO_ 2566892811 1000;
BA_ "GenMsgStartDelayTime" BO_ 2566892811 270;
BA_ "VFrameFormat" BO_ 2566892811 3;
BA_ "GenMsgCycleTime" BO_ 2566887947 1000;
BA_ "GenMsgStartDelayTime" BO_ 2566887947 220;
BA_ "VFrameFormat" BO_ 2566887947 3;
BA_ "GenMsgCycleTime" BO_ 2566883339 1000;
BA_ "GenMsgStartDelayTime" BO_ 2566883339 180;
BA_ "VFrameFormat" BO_ 2566883339 3;
BA_ "GenMsgCycleTime" BO_ 2566878731 1000;
BA_ "GenMsgStartDelayTime" BO_ 2566878731 120;
BA_ "VFrameFormat" BO_ 2566878731 3;
BA_ "GenMsgCycleTime" BO_ 2566874123 1000;
BA_ "GenMsgStartDelayTime" BO_ 2566874123 70;
BA_ "VFrameFormat" BO_ 2566874123 3;
BA_ "GenMsgCycleTime" BO_ 2566869259 1000;
BA_ "GenMsgStartDelayTime" BO_ 2566869259 30;
BA_ "VFrameFormat" BO_ 2566869259 3;
BA_ "GenMsgCycleTime" BO_ 2566864651 100;
BA_ "GenMsgStartDelayTime" BO_ 2566864651 60;
BA_ "VFrameFormat" BO_ 2566864651 3;
BA_ "GenMsgCycleTime" BO_ 2566860043 100;
BA_ "GenMsgStartDelayTime" BO_ 2566860043 40;
BA_ "VFrameFormat" BO_ 2566860043 3;
BA_ "GenMsgCycleTime" BO_ 2566855435 100;
BA_ "GenMsgStartDelayTime" BO_ 2566855435 20;
BA_ "VFrameFormat" BO_ 2566855435 3;
BA_ "GenMsgCycleTime" BO_ 2566850827 100;
BA_ "GenMsgStartDelayTime" BO_ 2566850827 10;
BA_ "VFrameFormat" BO_ 2566850827 3;
BA_ "GenMsgCycleTime" BO_ 2566899211 1000;
BA_ "GenMsgStartDelayTime" BO_ 2566899211 530;
BA_ "VFrameFormat" BO_ 2566899211 3;
BA_ "GenMsgCycleTime" BO_ 2566898955 1000;
BA_ "GenMsgStartDelayTime" BO_ 2566898955 485;
BA_ "VFrameFormat" BO_ 2566898955 3;
BA_ "GenMsgCycleTime" BO_ 2566898699 1000;
BA_ "GenMsgStartDelayTime" BO_ 2566898699 380;
BA_ "VFrameFormat" BO_ 2566898699 3;
BA_ "GenMsgCycleTime" BO_ 2566898443 1000;
BA_ "GenMsgStartDelayTime" BO_ 2566898443 275;
BA_ "VFrameFormat" BO_ 2566898443 3;
BA_ "GenSigCycleTime" SG_ 2566906891 Trailer4PneumSupply_Pressure_ISi 100;
BA_ "GenSigCycleTimeActive" SG_ 2566906891 Trailer4PneumSupply_Pressure_ISi 100;
BA_ "GenSigStartValue" SG_ 2566906891 Trailer4PneumSupply_Pressure_ISi 255;
BA_ "GenSigMaxLatency" SG_ 2566906891 Trailer4PneumSupply_Pressure_ISi 1140;
BA_ "SystemSignalLongSymbol" SG_ 2566906891 Trailer4PneumSupply_Pressure_ISi "Trailer4PneumSupply_Pressure_ISig_3";
BA_ "GenSigCycleTime" SG_ 2566906891 Trailer4VehicleType_ISig_3 100;
BA_ "GenSigCycleTimeActive" SG_ 2566906891 Trailer4VehicleType_ISig_3 100;
BA_ "GenSigStartValue" SG_ 2566906891 Trailer4VehicleType_ISig_3 3;
BA_ "GenSigMaxLatency" SG_ 2566906891 Trailer4VehicleType_ISig_3 1140;
BA_ "GenSigCycleTime" SG_ 2566906891 Trailer4NomBodyLevel_FrontLevel_ 100;
BA_ "GenSigCycleTimeActive" SG_ 2566906891 Trailer4NomBodyLevel_FrontLevel_ 100;
BA_ "GenSigStartValue" SG_ 2566906891 Trailer4NomBodyLevel_FrontLevel_ 65535;
BA_ "GenSigMaxLatency" SG_ 2566906891 Trailer4NomBodyLevel_FrontLevel_ 1140;
BA_ "SystemSignalLongSymbol" SG_ 2566906891 Trailer4NomBodyLevel_FrontLevel_ "Trailer4NomBodyLevel_FrontLevel_ISig_3";
BA_ "GenSigCycleTime" SG_ 2566906891 Trailer4YCSystemStatus_ISig_3 100;
BA_ "GenSigCycleTimeActive" SG_ 2566906891 Trailer4YCSystemStatus_ISig_3 100;
BA_ "GenSigStartValue" SG_ 2566906891 Trailer4YCSystemStatus_ISig_3 3;
BA_ "GenSigMaxLatency" SG_ 2566906891 Trailer4YCSystemStatus_ISig_3 1140;
BA_ "GenSigCycleTime" SG_ 2566906891 Trailer4EBSAmberWarning_ISig_3 100;
BA_ "GenSigCycleTimeActive" SG_ 2566906891 Trailer4EBSAmberWarning_ISig_3 100;
BA_ "GenSigStartValue" SG_ 2566906891 Trailer4EBSAmberWarning_ISig_3 3;
BA_ "GenSigMaxLatency" SG_ 2566906891 Trailer4EBSAmberWarning_ISig_3 1140;
BA_ "GenSigCycleTime" SG_ 2566906891 Trailer4LevelControlStatus_ISig_ 100;
BA_ "GenSigCycleTimeActive" SG_ 2566906891 Trailer4LevelControlStatus_ISig_ 100;
BA_ "GenSigStartValue" SG_ 2566906891 Trailer4LevelControlStatus_ISig_ 3;
BA_ "GenSigMaxLatency" SG_ 2566906891 Trailer4LevelControlStatus_ISig_ 1140;
BA_ "SystemSignalLongSymbol" SG_ 2566906891 Trailer4LevelControlStatus_ISig_ "Trailer4LevelControlStatus_ISig_3";
BA_ "GenSigCycleTime" SG_ 2566906891 Trailer4NomBodyLevel_RearLevel_I 100;
BA_ "GenSigCycleTimeActive" SG_ 2566906891 Trailer4NomBodyLevel_RearLevel_I 100;
BA_ "GenSigStartValue" SG_ 2566906891 Trailer4NomBodyLevel_RearLevel_I 65535;
BA_ "GenSigMaxLatency" SG_ 2566906891 Trailer4NomBodyLevel_RearLevel_I 1140;
BA_ "SystemSignalLongSymbol" SG_ 2566906891 Trailer4NomBodyLevel_RearLevel_I "Trailer4NomBodyLevel_RearLevel_ISig_3";
BA_ "GenSigCycleTime" SG_ 2566906891 Trailer4ROPSystemStatus_ISig_3 100;
BA_ "GenSigCycleTimeActive" SG_ 2566906891 Trailer4ROPSystemStatus_ISig_3 100;
BA_ "GenSigStartValue" SG_ 2566906891 Trailer4ROPSystemStatus_ISig_3 3;
BA_ "GenSigMaxLatency" SG_ 2566906891 Trailer4ROPSystemStatus_ISig_3 1140;
BA_ "GenSigCycleTime" SG_ 2566906891 Trailer4LoadRampApprAssistStat_I 100;
BA_ "GenSigCycleTimeActive" SG_ 2566906891 Trailer4LoadRampApprAssistStat_I 100;
BA_ "GenSigStartValue" SG_ 2566906891 Trailer4LoadRampApprAssistStat_I 3;
BA_ "GenSigMaxLatency" SG_ 2566906891 Trailer4LoadRampApprAssistStat_I 1140;
BA_ "SystemSignalLongSymbol" SG_ 2566906891 Trailer4LoadRampApprAssistStat_I "Trailer4LoadRampApprAssistStat_ISig_3";
BA_ "GenSigCycleTime" SG_ 2566906891 Trailer4ExtLvlStorageSupport_ISi 100;
BA_ "GenSigCycleTimeActive" SG_ 2566906891 Trailer4ExtLvlStorageSupport_ISi 100;
BA_ "GenSigStartValue" SG_ 2566906891 Trailer4ExtLvlStorageSupport_ISi 3;
BA_ "GenSigMaxLatency" SG_ 2566906891 Trailer4ExtLvlStorageSupport_ISi 1140;
BA_ "SystemSignalLongSymbol" SG_ 2566906891 Trailer4ExtLvlStorageSupport_ISi "Trailer4ExtLvlStorageSupport_ISig_3";
BA_ "GenSigCycleTime" SG_ 2566906891 Trailer4PneumSupply_Status_ISig_ 100;
BA_ "GenSigCycleTimeActive" SG_ 2566906891 Trailer4PneumSupply_Status_ISig_ 100;
BA_ "GenSigStartValue" SG_ 2566906891 Trailer4PneumSupply_Status_ISig_ 3;
BA_ "GenSigMaxLatency" SG_ 2566906891 Trailer4PneumSupply_Status_ISig_ 1140;
BA_ "SystemSignalLongSymbol" SG_ 2566906891 Trailer4PneumSupply_Status_ISig_ "Trailer4PneumSupply_Status_ISig_3";
BA_ "GenSigCycleTime" SG_ 2566906891 Trailer4EBSRedWarning_ISig_3 100;
BA_ "GenSigCycleTimeActive" SG_ 2566906891 Trailer4EBSRedWarning_ISig_3 100;
BA_ "GenSigMaxLatency" SG_ 2566906891 Trailer4EBSRedWarning_ISig_3 1140;
BA_ "GenSigCycleTime" SG_ 2566906891 Trailer4ElectricalSupplyStat_ISi 100;
BA_ "GenSigCycleTimeActive" SG_ 2566906891 Trailer4ElectricalSupplyStat_ISi 100;
BA_ "GenSigStartValue" SG_ 2566906891 Trailer4ElectricalSupplyStat_ISi 3;
BA_ "GenSigMaxLatency" SG_ 2566906891 Trailer4ElectricalSupplyStat_ISi 1140;
BA_ "SystemSignalLongSymbol" SG_ 2566906891 Trailer4ElectricalSupplyStat_ISi "Trailer4ElectricalSupplyStat_ISig_3";
BA_ "GenSigCycleTime" SG_ 2566902283 Trailer3YCSystemStatus_ISig_3 100;
BA_ "GenSigCycleTimeActive" SG_ 2566902283 Trailer3YCSystemStatus_ISig_3 100;
BA_ "GenSigStartValue" SG_ 2566902283 Trailer3YCSystemStatus_ISig_3 3;
BA_ "GenSigMaxLatency" SG_ 2566902283 Trailer3YCSystemStatus_ISig_3 1130;
BA_ "GenSigCycleTime" SG_ 2566902283 Trailer3EBSAmberWarning_ISig_3 100;
BA_ "GenSigCycleTimeActive" SG_ 2566902283 Trailer3EBSAmberWarning_ISig_3 100;
BA_ "GenSigStartValue" SG_ 2566902283 Trailer3EBSAmberWarning_ISig_3 3;
BA_ "GenSigMaxLatency" SG_ 2566902283 Trailer3EBSAmberWarning_ISig_3 1130;
BA_ "GenSigCycleTime" SG_ 2566902283 Trailer3NomBodyLevel_RearLevel_I 100;
BA_ "GenSigCycleTimeActive" SG_ 2566902283 Trailer3NomBodyLevel_RearLevel_I 100;
BA_ "GenSigStartValue" SG_ 2566902283 Trailer3NomBodyLevel_RearLevel_I 65535;
BA_ "GenSigMaxLatency" SG_ 2566902283 Trailer3NomBodyLevel_RearLevel_I 1130;
BA_ "SystemSignalLongSymbol" SG_ 2566902283 Trailer3NomBodyLevel_RearLevel_I "Trailer3NomBodyLevel_RearLevel_ISig_3";
BA_ "GenSigCycleTime" SG_ 2566902283 Trailer3EBSRedWarning_ISig_3 100;
BA_ "GenSigCycleTimeActive" SG_ 2566902283 Trailer3EBSRedWarning_ISig_3 100;
BA_ "GenSigStartValue" SG_ 2566902283 Trailer3EBSRedWarning_ISig_3 3;
BA_ "GenSigMaxLatency" SG_ 2566902283 Trailer3EBSRedWarning_ISig_3 1130;
BA_ "GenSigCycleTime" SG_ 2566902283 Trailer3PneumSupply_Status_ISig_ 100;
BA_ "GenSigCycleTimeActive" SG_ 2566902283 Trailer3PneumSupply_Status_ISig_ 100;
BA_ "GenSigStartValue" SG_ 2566902283 Trailer3PneumSupply_Status_ISig_ 3;
BA_ "GenSigMaxLatency" SG_ 2566902283 Trailer3PneumSupply_Status_ISig_ 1130;
BA_ "SystemSignalLongSymbol" SG_ 2566902283 Trailer3PneumSupply_Status_ISig_ "Trailer3PneumSupply_Status_ISig_3";
BA_ "GenSigCycleTime" SG_ 2566902283 Trailer3PneumSupply_Pressure_ISi 100;
BA_ "GenSigCycleTimeActive" SG_ 2566902283 Trailer3PneumSupply_Pressure_ISi 100;
BA_ "GenSigStartValue" SG_ 2566902283 Trailer3PneumSupply_Pressure_ISi 255;
BA_ "GenSigMaxLatency" SG_ 2566902283 Trailer3PneumSupply_Pressure_ISi 1130;
BA_ "SystemSignalLongSymbol" SG_ 2566902283 Trailer3PneumSupply_Pressure_ISi "Trailer3PneumSupply_Pressure_ISig_3";
BA_ "GenSigCycleTime" SG_ 2566902283 Trailer3LoadRampApprAssistStat_I 100;
BA_ "GenSigCycleTimeActive" SG_ 2566902283 Trailer3LoadRampApprAssistStat_I 100;
BA_ "GenSigStartValue" SG_ 2566902283 Trailer3LoadRampApprAssistStat_I 3;
BA_ "GenSigMaxLatency" SG_ 2566902283 Trailer3LoadRampApprAssistStat_I 1130;
BA_ "SystemSignalLongSymbol" SG_ 2566902283 Trailer3LoadRampApprAssistStat_I "Trailer3LoadRampApprAssistStat_ISig_3";
BA_ "GenSigCycleTime" SG_ 2566902283 Trailer3ROPSystemStatus_ISig_3 100;
BA_ "GenSigCycleTimeActive" SG_ 2566902283 Trailer3ROPSystemStatus_ISig_3 100;
BA_ "GenSigStartValue" SG_ 2566902283 Trailer3ROPSystemStatus_ISig_3 3;
BA_ "GenSigMaxLatency" SG_ 2566902283 Trailer3ROPSystemStatus_ISig_3 1130;
BA_ "GenSigCycleTime" SG_ 2566902283 Trailer3ElectricalSupplyStat_ISi 100;
BA_ "GenSigCycleTimeActive" SG_ 2566902283 Trailer3ElectricalSupplyStat_ISi 100;
BA_ "GenSigStartValue" SG_ 2566902283 Trailer3ElectricalSupplyStat_ISi 3;
BA_ "GenSigMaxLatency" SG_ 2566902283 Trailer3ElectricalSupplyStat_ISi 1130;
BA_ "SystemSignalLongSymbol" SG_ 2566902283 Trailer3ElectricalSupplyStat_ISi "Trailer3ElectricalSupplyStat_ISig_3";
BA_ "GenSigCycleTime" SG_ 2566902283 Trailer3NomBodyLevel_FrontLevel_ 100;
BA_ "GenSigCycleTimeActive" SG_ 2566902283 Trailer3NomBodyLevel_FrontLevel_ 100;
BA_ "GenSigStartValue" SG_ 2566902283 Trailer3NomBodyLevel_FrontLevel_ 65535;
BA_ "GenSigMaxLatency" SG_ 2566902283 Trailer3NomBodyLevel_FrontLevel_ 1130;
BA_ "SystemSignalLongSymbol" SG_ 2566902283 Trailer3NomBodyLevel_FrontLevel_ "Trailer3NomBodyLevel_FrontLevel_ISig_3";
BA_ "GenSigCycleTime" SG_ 2566902283 Trailer3LevelControlStatus_ISig_ 100;
BA_ "GenSigCycleTimeActive" SG_ 2566902283 Trailer3LevelControlStatus_ISig_ 100;
BA_ "GenSigStartValue" SG_ 2566902283 Trailer3LevelControlStatus_ISig_ 3;
BA_ "GenSigMaxLatency" SG_ 2566902283 Trailer3LevelControlStatus_ISig_ 1130;
BA_ "SystemSignalLongSymbol" SG_ 2566902283 Trailer3LevelControlStatus_ISig_ "Trailer3LevelControlStatus_ISig_3";
BA_ "GenSigCycleTime" SG_ 2566902283 Trailer3VehicleType_ISig_3 100;
BA_ "GenSigCycleTimeActive" SG_ 2566902283 Trailer3VehicleType_ISig_3 100;
BA_ "GenSigStartValue" SG_ 2566902283 Trailer3VehicleType_ISig_3 3;
BA_ "GenSigMaxLatency" SG_ 2566902283 Trailer3VehicleType_ISig_3 1130;
BA_ "GenSigCycleTime" SG_ 2566902283 Trailer3ExtLvlStorageSupport_ISi 100;
BA_ "GenSigCycleTimeActive" SG_ 2566902283 Trailer3ExtLvlStorageSupport_ISi 100;
BA_ "GenSigStartValue" SG_ 2566902283 Trailer3ExtLvlStorageSupport_ISi 3;
BA_ "GenSigMaxLatency" SG_ 2566902283 Trailer3ExtLvlStorageSupport_ISi 1130;
BA_ "SystemSignalLongSymbol" SG_ 2566902283 Trailer3ExtLvlStorageSupport_ISi "Trailer3ExtLvlStorageSupport_ISig_3";
BA_ "GenSigCycleTime" SG_ 2566897419 Trailer2VehicleType_ISig_3 100;
BA_ "GenSigCycleTimeActive" SG_ 2566897419 Trailer2VehicleType_ISig_3 100;
BA_ "GenSigStartValue" SG_ 2566897419 Trailer2VehicleType_ISig_3 3;
BA_ "GenSigMaxLatency" SG_ 2566897419 Trailer2VehicleType_ISig_3 1120;
BA_ "GenSigCycleTime" SG_ 2566897419 Trailer2NomBodyLevel_RearLevel_I 100;
BA_ "GenSigCycleTimeActive" SG_ 2566897419 Trailer2NomBodyLevel_RearLevel_I 100;
BA_ "GenSigStartValue" SG_ 2566897419 Trailer2NomBodyLevel_RearLevel_I 65535;
BA_ "GenSigMaxLatency" SG_ 2566897419 Trailer2NomBodyLevel_RearLevel_I 1120;
BA_ "SystemSignalLongSymbol" SG_ 2566897419 Trailer2NomBodyLevel_RearLevel_I "Trailer2NomBodyLevel_RearLevel_ISig_3";
BA_ "GenSigCycleTime" SG_ 2566897419 Trailer2EBSAmberWarning_ISig_3 100;
BA_ "GenSigCycleTimeActive" SG_ 2566897419 Trailer2EBSAmberWarning_ISig_3 100;
BA_ "GenSigStartValue" SG_ 2566897419 Trailer2EBSAmberWarning_ISig_3 3;
BA_ "GenSigMaxLatency" SG_ 2566897419 Trailer2EBSAmberWarning_ISig_3 1120;
BA_ "GenSigCycleTime" SG_ 2566897419 Trailer2YCSystemStatus_ISig_3 100;
BA_ "GenSigCycleTimeActive" SG_ 2566897419 Trailer2YCSystemStatus_ISig_3 100;
BA_ "GenSigStartValue" SG_ 2566897419 Trailer2YCSystemStatus_ISig_3 3;
BA_ "GenSigMaxLatency" SG_ 2566897419 Trailer2YCSystemStatus_ISig_3 1120;
BA_ "GenSigCycleTime" SG_ 2566897419 Trailer2ExtLvlStorageSupport_ISi 100;
BA_ "GenSigCycleTimeActive" SG_ 2566897419 Trailer2ExtLvlStorageSupport_ISi 100;
BA_ "GenSigStartValue" SG_ 2566897419 Trailer2ExtLvlStorageSupport_ISi 3;
BA_ "GenSigMaxLatency" SG_ 2566897419 Trailer2ExtLvlStorageSupport_ISi 1120;
BA_ "SystemSignalLongSymbol" SG_ 2566897419 Trailer2ExtLvlStorageSupport_ISi "Trailer2ExtLvlStorageSupport_ISig_3";
BA_ "GenSigCycleTime" SG_ 2566897419 Trailer2ROPSystemStatus_ISig_3 100;
BA_ "GenSigCycleTimeActive" SG_ 2566897419 Trailer2ROPSystemStatus_ISig_3 100;
BA_ "GenSigStartValue" SG_ 2566897419 Trailer2ROPSystemStatus_ISig_3 3;
BA_ "GenSigMaxLatency" SG_ 2566897419 Trailer2ROPSystemStatus_ISig_3 1120;
BA_ "GenSigCycleTime" SG_ 2566897419 Trailer2PneumSupply_Status_ISig_ 100;
BA_ "GenSigCycleTimeActive" SG_ 2566897419 Trailer2PneumSupply_Status_ISig_ 100;
BA_ "GenSigStartValue" SG_ 2566897419 Trailer2PneumSupply_Status_ISig_ 3;
BA_ "GenSigMaxLatency" SG_ 2566897419 Trailer2PneumSupply_Status_ISig_ 1120;
BA_ "SystemSignalLongSymbol" SG_ 2566897419 Trailer2PneumSupply_Status_ISig_ "Trailer2PneumSupply_Status_ISig_3";
BA_ "GenSigCycleTime" SG_ 2566897419 Trailer2ElectricalSupplyStat_ISi 100;
BA_ "GenSigCycleTimeActive" SG_ 2566897419 Trailer2ElectricalSupplyStat_ISi 100;
BA_ "GenSigStartValue" SG_ 2566897419 Trailer2ElectricalSupplyStat_ISi 3;
BA_ "GenSigMaxLatency" SG_ 2566897419 Trailer2ElectricalSupplyStat_ISi 1120;
BA_ "SystemSignalLongSymbol" SG_ 2566897419 Trailer2ElectricalSupplyStat_ISi "Trailer2ElectricalSupplyStat_ISig_3";
BA_ "GenSigCycleTime" SG_ 2566897419 Trailer2LevelControlStatus_ISig_ 100;
BA_ "GenSigCycleTimeActive" SG_ 2566897419 Trailer2LevelControlStatus_ISig_ 100;
BA_ "GenSigStartValue" SG_ 2566897419 Trailer2LevelControlStatus_ISig_ 3;
BA_ "GenSigMaxLatency" SG_ 2566897419 Trailer2LevelControlStatus_ISig_ 1120;
BA_ "SystemSignalLongSymbol" SG_ 2566897419 Trailer2LevelControlStatus_ISig_ "Trailer2LevelControlStatus_ISig_3";
BA_ "GenSigCycleTime" SG_ 2566897419 Trailer2PneumSupply_Pressure_ISi 100;
BA_ "GenSigCycleTimeActive" SG_ 2566897419 Trailer2PneumSupply_Pressure_ISi 100;
BA_ "GenSigStartValue" SG_ 2566897419 Trailer2PneumSupply_Pressure_ISi 255;
BA_ "GenSigMaxLatency" SG_ 2566897419 Trailer2PneumSupply_Pressure_ISi 1120;
BA_ "SystemSignalLongSymbol" SG_ 2566897419 Trailer2PneumSupply_Pressure_ISi "Trailer2PneumSupply_Pressure_ISig_3";
BA_ "GenSigCycleTime" SG_ 2566897419 Trailer2NomBodyLevel_FrontLevel_ 100;
BA_ "GenSigCycleTimeActive" SG_ 2566897419 Trailer2NomBodyLevel_FrontLevel_ 100;
BA_ "GenSigStartValue" SG_ 2566897419 Trailer2NomBodyLevel_FrontLevel_ 65535;
BA_ "GenSigMaxLatency" SG_ 2566897419 Trailer2NomBodyLevel_FrontLevel_ 1120;
BA_ "SystemSignalLongSymbol" SG_ 2566897419 Trailer2NomBodyLevel_FrontLevel_ "Trailer2NomBodyLevel_FrontLevel_ISig_3";
BA_ "GenSigCycleTime" SG_ 2566897419 Trailer2LoadRampApprAssistStat_I 100;
BA_ "GenSigCycleTimeActive" SG_ 2566897419 Trailer2LoadRampApprAssistStat_I 100;
BA_ "GenSigStartValue" SG_ 2566897419 Trailer2LoadRampApprAssistStat_I 3;
BA_ "GenSigMaxLatency" SG_ 2566897419 Trailer2LoadRampApprAssistStat_I 1120;
BA_ "SystemSignalLongSymbol" SG_ 2566897419 Trailer2LoadRampApprAssistStat_I "Trailer2LoadRampApprAssistStat_ISig_3";
BA_ "GenSigCycleTime" SG_ 2566897419 Trailer2EBSRedWarning_ISig_3 100;
BA_ "GenSigCycleTimeActive" SG_ 2566897419 Trailer2EBSRedWarning_ISig_3 100;
BA_ "GenSigStartValue" SG_ 2566897419 Trailer2EBSRedWarning_ISig_3 3;
BA_ "GenSigMaxLatency" SG_ 2566897419 Trailer2EBSRedWarning_ISig_3 1120;
BA_ "GenSigCycleTime" SG_ 2566892811 Trailer1LoadRampApprAssistStat_I 100;
BA_ "GenSigCycleTimeActive" SG_ 2566892811 Trailer1LoadRampApprAssistStat_I 100;
BA_ "GenSigStartValue" SG_ 2566892811 Trailer1LoadRampApprAssistStat_I 3;
BA_ "GenSigMaxLatency" SG_ 2566892811 Trailer1LoadRampApprAssistStat_I 1110;
BA_ "SystemSignalLongSymbol" SG_ 2566892811 Trailer1LoadRampApprAssistStat_I "Trailer1LoadRampApprAssistStat_ISig_3";
BA_ "GenSigCycleTime" SG_ 2566892811 Trailer1NomBodyLevel_RearLevel_I 100;
BA_ "GenSigCycleTimeActive" SG_ 2566892811 Trailer1NomBodyLevel_RearLevel_I 100;
BA_ "GenSigStartValue" SG_ 2566892811 Trailer1NomBodyLevel_RearLevel_I 65535;
BA_ "GenSigMaxLatency" SG_ 2566892811 Trailer1NomBodyLevel_RearLevel_I 1110;
BA_ "SystemSignalLongSymbol" SG_ 2566892811 Trailer1NomBodyLevel_RearLevel_I "Trailer1NomBodyLevel_RearLevel_ISig_3";
BA_ "GenSigCycleTime" SG_ 2566892811 Trailer1NomBodyLevel_FrontLevel_ 100;
BA_ "GenSigCycleTimeActive" SG_ 2566892811 Trailer1NomBodyLevel_FrontLevel_ 100;
BA_ "GenSigStartValue" SG_ 2566892811 Trailer1NomBodyLevel_FrontLevel_ 65535;
BA_ "GenSigMaxLatency" SG_ 2566892811 Trailer1NomBodyLevel_FrontLevel_ 1110;
BA_ "SystemSignalLongSymbol" SG_ 2566892811 Trailer1NomBodyLevel_FrontLevel_ "Trailer1NomBodyLevel_FrontLevel_ISig_3";
BA_ "GenSigCycleTime" SG_ 2566892811 Trailer1VehicleType_ISig_3 100;
BA_ "GenSigCycleTimeActive" SG_ 2566892811 Trailer1VehicleType_ISig_3 100;
BA_ "GenSigStartValue" SG_ 2566892811 Trailer1VehicleType_ISig_3 3;
BA_ "GenSigMaxLatency" SG_ 2566892811 Trailer1VehicleType_ISig_3 1110;
BA_ "GenSigCycleTime" SG_ 2566892811 Trailer1EBSRedWarning_ISig_3 100;
BA_ "GenSigCycleTimeActive" SG_ 2566892811 Trailer1EBSRedWarning_ISig_3 100;
BA_ "GenSigStartValue" SG_ 2566892811 Trailer1EBSRedWarning_ISig_3 3;
BA_ "GenSigMaxLatency" SG_ 2566892811 Trailer1EBSRedWarning_ISig_3 1110;
BA_ "GenSigCycleTime" SG_ 2566892811 Trailer1PneumSupply_Pressure_ISi 100;
BA_ "GenSigCycleTimeActive" SG_ 2566892811 Trailer1PneumSupply_Pressure_ISi 100;
BA_ "GenSigStartValue" SG_ 2566892811 Trailer1PneumSupply_Pressure_ISi 255;
BA_ "GenSigMaxLatency" SG_ 2566892811 Trailer1PneumSupply_Pressure_ISi 1110;
BA_ "SystemSignalLongSymbol" SG_ 2566892811 Trailer1PneumSupply_Pressure_ISi "Trailer1PneumSupply_Pressure_ISig_3";
BA_ "GenSigCycleTime" SG_ 2566892811 Trailer1LevelControlStatus_ISig_ 100;
BA_ "GenSigCycleTimeActive" SG_ 2566892811 Trailer1LevelControlStatus_ISig_ 100;
BA_ "GenSigStartValue" SG_ 2566892811 Trailer1LevelControlStatus_ISig_ 3;
BA_ "GenSigMaxLatency" SG_ 2566892811 Trailer1LevelControlStatus_ISig_ 1110;
BA_ "SystemSignalLongSymbol" SG_ 2566892811 Trailer1LevelControlStatus_ISig_ "Trailer1LevelControlStatus_ISig_3";
BA_ "GenSigCycleTime" SG_ 2566892811 Trailer1ElectricalSupplyStat_ISi 100;
BA_ "GenSigCycleTimeActive" SG_ 2566892811 Trailer1ElectricalSupplyStat_ISi 100;
BA_ "GenSigStartValue" SG_ 2566892811 Trailer1ElectricalSupplyStat_ISi 3;
BA_ "GenSigMaxLatency" SG_ 2566892811 Trailer1ElectricalSupplyStat_ISi 1110;
BA_ "SystemSignalLongSymbol" SG_ 2566892811 Trailer1ElectricalSupplyStat_ISi "Trailer1ElectricalSupplyStat_ISig_3";
BA_ "GenSigCycleTime" SG_ 2566892811 Trailer1PneumSupply_Status_ISig_ 100;
BA_ "GenSigCycleTimeActive" SG_ 2566892811 Trailer1PneumSupply_Status_ISig_ 100;
BA_ "GenSigStartValue" SG_ 2566892811 Trailer1PneumSupply_Status_ISig_ 3;
BA_ "GenSigMaxLatency" SG_ 2566892811 Trailer1PneumSupply_Status_ISig_ 1110;
BA_ "SystemSignalLongSymbol" SG_ 2566892811 Trailer1PneumSupply_Status_ISig_ "Trailer1PneumSupply_Status_ISig_3";
BA_ "GenSigCycleTime" SG_ 2566892811 Trailer1ROPSystemStatus_ISig_3 100;
BA_ "GenSigCycleTimeActive" SG_ 2566892811 Trailer1ROPSystemStatus_ISig_3 100;
BA_ "GenSigStartValue" SG_ 2566892811 Trailer1ROPSystemStatus_ISig_3 3;
BA_ "GenSigMaxLatency" SG_ 2566892811 Trailer1ROPSystemStatus_ISig_3 1110;
BA_ "GenSigCycleTime" SG_ 2566892811 Trailer1YCSystemStatus_ISig_3 100;
BA_ "GenSigCycleTimeActive" SG_ 2566892811 Trailer1YCSystemStatus_ISig_3 100;
BA_ "GenSigStartValue" SG_ 2566892811 Trailer1YCSystemStatus_ISig_3 3;
BA_ "GenSigMaxLatency" SG_ 2566892811 Trailer1YCSystemStatus_ISig_3 1110;
BA_ "GenSigCycleTime" SG_ 2566892811 Trailer1ExtLvlStorageSupport_ISi 100;
BA_ "GenSigCycleTimeActive" SG_ 2566892811 Trailer1ExtLvlStorageSupport_ISi 100;
BA_ "GenSigStartValue" SG_ 2566892811 Trailer1ExtLvlStorageSupport_ISi 3;
BA_ "GenSigMaxLatency" SG_ 2566892811 Trailer1ExtLvlStorageSupport_ISi 1110;
BA_ "SystemSignalLongSymbol" SG_ 2566892811 Trailer1ExtLvlStorageSupport_ISi "Trailer1ExtLvlStorageSupport_ISig_3";
BA_ "GenSigCycleTime" SG_ 2566892811 Trailer1EBSAmberWarning_ISig_3 100;
BA_ "GenSigCycleTimeActive" SG_ 2566892811 Trailer1EBSAmberWarning_ISig_3 100;
BA_ "GenSigStartValue" SG_ 2566892811 Trailer1EBSAmberWarning_ISig_3 3;
BA_ "GenSigMaxLatency" SG_ 2566892811 Trailer1EBSAmberWarning_ISig_3 1110;
BA_ "GenSigCycleTime" SG_ 2566887947 Trailer5TireInfoISO_Pressure_ISi 100;
BA_ "GenSigCycleTimeActive" SG_ 2566887947 Trailer5TireInfoISO_Pressure_ISi 100;
BA_ "GenSigStartValue" SG_ 2566887947 Trailer5TireInfoISO_Pressure_ISi 255;
BA_ "GenSigMaxLatency" SG_ 2566887947 Trailer5TireInfoISO_Pressure_ISi 1050;
BA_ "NeedsUpdateBit" SG_ 2566887947 Trailer5TireInfoISO_Pressure_ISi 1;
BA_ "SystemSignalLongSymbol" SG_ 2566887947 Trailer5TireInfoISO_Pressure_ISi "Trailer5TireInfoISO_Pressure_ISig_3";
BA_ "GenSigCycleTime" SG_ 2566887947 Trailer5TireInfoISO_Active_ISig_ 100;
BA_ "GenSigCycleTimeActive" SG_ 2566887947 Trailer5TireInfoISO_Active_ISig_ 100;
BA_ "GenSigStartValue" SG_ 2566887947 Trailer5TireInfoISO_Active_ISig_ 3;
BA_ "GenSigMaxLatency" SG_ 2566887947 Trailer5TireInfoISO_Active_ISig_ 1050;
BA_ "NeedsUpdateBit" SG_ 2566887947 Trailer5TireInfoISO_Active_ISig_ 1;
BA_ "SystemSignalLongSymbol" SG_ 2566887947 Trailer5TireInfoISO_Active_ISig_ "Trailer5TireInfoISO_Active_ISig_3";
BA_ "GenSigCycleTime" SG_ 2566887947 Trailer5TireInfoISO_PowerSupply_ 100;
BA_ "GenSigCycleTimeActive" SG_ 2566887947 Trailer5TireInfoISO_PowerSupply_ 100;
BA_ "GenSigStartValue" SG_ 2566887947 Trailer5TireInfoISO_PowerSupply_ 3;
BA_ "GenSigMaxLatency" SG_ 2566887947 Trailer5TireInfoISO_PowerSupply_ 1050;
BA_ "NeedsUpdateBit" SG_ 2566887947 Trailer5TireInfoISO_PowerSupply_ 1;
BA_ "SystemSignalLongSymbol" SG_ 2566887947 Trailer5TireInfoISO_PowerSupply_ "Trailer5TireInfoISO_PowerSupply_ISig_3";
BA_ "GenSigCycleTime" SG_ 2566887947 Trailer5TireInfoISO_Leakage_ISig 100;
BA_ "GenSigCycleTimeActive" SG_ 2566887947 Trailer5TireInfoISO_Leakage_ISig 100;
BA_ "GenSigStartValue" SG_ 2566887947 Trailer5TireInfoISO_Leakage_ISig 65535;
BA_ "GenSigMaxLatency" SG_ 2566887947 Trailer5TireInfoISO_Leakage_ISig 1050;
BA_ "NeedsUpdateBit" SG_ 2566887947 Trailer5TireInfoISO_Leakage_ISig 1;
BA_ "SystemSignalLongSymbol" SG_ 2566887947 Trailer5TireInfoISO_Leakage_ISig "Trailer5TireInfoISO_Leakage_ISig_3";
BA_ "GenSigCycleTime" SG_ 2566887947 Trailer5TireInfoISO_TireId_ISig_ 100;
BA_ "GenSigCycleTimeActive" SG_ 2566887947 Trailer5TireInfoISO_TireId_ISig_ 100;
BA_ "GenSigMaxLatency" SG_ 2566887947 Trailer5TireInfoISO_TireId_ISig_ 1050;
BA_ "NeedsUpdateBit" SG_ 2566887947 Trailer5TireInfoISO_TireId_ISig_ 1;
BA_ "SystemSignalLongSymbol" SG_ 2566887947 Trailer5TireInfoISO_TireId_ISig_ "Trailer5TireInfoISO_TireId_ISig_3";
BA_ "GenSigCycleTime" SG_ 2566887947 Trailer5TireInfoISO_Temperature_ 100;
BA_ "GenSigCycleTimeActive" SG_ 2566887947 Trailer5TireInfoISO_Temperature_ 100;
BA_ "GenSigStartValue" SG_ 2566887947 Trailer5TireInfoISO_Temperature_ 65535;
BA_ "GenSigMaxLatency" SG_ 2566887947 Trailer5TireInfoISO_Temperature_ 1050;
BA_ "NeedsUpdateBit" SG_ 2566887947 Trailer5TireInfoISO_Temperature_ 1;
BA_ "SystemSignalLongSymbol" SG_ 2566887947 Trailer5TireInfoISO_Temperature_ "Trailer5TireInfoISO_Temperature_ISig_3";
BA_ "GenSigCycleTime" SG_ 2566887947 Trailer5TireInfoISO_Warning_ISig 100;
BA_ "GenSigCycleTimeActive" SG_ 2566887947 Trailer5TireInfoISO_Warning_ISig 100;
BA_ "GenSigStartValue" SG_ 2566887947 Trailer5TireInfoISO_Warning_ISig 7;
BA_ "GenSigMaxLatency" SG_ 2566887947 Trailer5TireInfoISO_Warning_ISig 1050;
BA_ "NeedsUpdateBit" SG_ 2566887947 Trailer5TireInfoISO_Warning_ISig 1;
BA_ "SystemSignalLongSymbol" SG_ 2566887947 Trailer5TireInfoISO_Warning_ISig "Trailer5TireInfoISO_Warning_ISig_3";
BA_ "GenSigCycleTime" SG_ 2566887947 Trailer5TireInfoISO_PresSuff_ISi 100;
BA_ "GenSigCycleTimeActive" SG_ 2566887947 Trailer5TireInfoISO_PresSuff_ISi 100;
BA_ "GenSigStartValue" SG_ 2566887947 Trailer5TireInfoISO_PresSuff_ISi 3;
BA_ "GenSigMaxLatency" SG_ 2566887947 Trailer5TireInfoISO_PresSuff_ISi 1050;
BA_ "NeedsUpdateBit" SG_ 2566887947 Trailer5TireInfoISO_PresSuff_ISi 1;
BA_ "SystemSignalLongSymbol" SG_ 2566887947 Trailer5TireInfoISO_PresSuff_ISi "Trailer5TireInfoISO_PresSuff_ISig_3";
BA_ "GenSigSendType" SG_ 2566887947 Trailer5TireInfoISO_sg_UB_ISig_3 7;
BA_ "GenSigCycleTime" SG_ 2566883339 Trailer4TireInfoISO_sg_UB_ISig_3 100;
BA_ "GenSigCycleTimeActive" SG_ 2566883339 Trailer4TireInfoISO_sg_UB_ISig_3 100;
BA_ "GenSigCycleTime" SG_ 2566883339 Trailer4TireInfoISO_PresSuff_ISi 100;
BA_ "GenSigCycleTimeActive" SG_ 2566883339 Trailer4TireInfoISO_PresSuff_ISi 100;
BA_ "GenSigStartValue" SG_ 2566883339 Trailer4TireInfoISO_PresSuff_ISi 3;
BA_ "GenSigMaxLatency" SG_ 2566883339 Trailer4TireInfoISO_PresSuff_ISi 1040;
BA_ "NeedsUpdateBit" SG_ 2566883339 Trailer4TireInfoISO_PresSuff_ISi 1;
BA_ "SystemSignalLongSymbol" SG_ 2566883339 Trailer4TireInfoISO_PresSuff_ISi "Trailer4TireInfoISO_PresSuff_ISig_3";
BA_ "GenSigCycleTime" SG_ 2566883339 Trailer4TireInfoISO_Pressure_ISi 100;
BA_ "GenSigCycleTimeActive" SG_ 2566883339 Trailer4TireInfoISO_Pressure_ISi 100;
BA_ "GenSigStartValue" SG_ 2566883339 Trailer4TireInfoISO_Pressure_ISi 255;
BA_ "GenSigMaxLatency" SG_ 2566883339 Trailer4TireInfoISO_Pressure_ISi 1040;
BA_ "NeedsUpdateBit" SG_ 2566883339 Trailer4TireInfoISO_Pressure_ISi 1;
BA_ "SystemSignalLongSymbol" SG_ 2566883339 Trailer4TireInfoISO_Pressure_ISi "Trailer4TireInfoISO_Pressure_ISig_3";
BA_ "GenSigCycleTime" SG_ 2566883339 Trailer4TireInfoISO_Leakage_ISig 100;
BA_ "GenSigCycleTimeActive" SG_ 2566883339 Trailer4TireInfoISO_Leakage_ISig 100;
BA_ "GenSigStartValue" SG_ 2566883339 Trailer4TireInfoISO_Leakage_ISig 65535;
BA_ "GenSigMaxLatency" SG_ 2566883339 Trailer4TireInfoISO_Leakage_ISig 1040;
BA_ "NeedsUpdateBit" SG_ 2566883339 Trailer4TireInfoISO_Leakage_ISig 1;
BA_ "SystemSignalLongSymbol" SG_ 2566883339 Trailer4TireInfoISO_Leakage_ISig "Trailer4TireInfoISO_Leakage_ISig_3";
BA_ "GenSigCycleTime" SG_ 2566883339 Trailer4TireInfoISO_TireId_ISig_ 100;
BA_ "GenSigCycleTimeActive" SG_ 2566883339 Trailer4TireInfoISO_TireId_ISig_ 100;
BA_ "GenSigMaxLatency" SG_ 2566883339 Trailer4TireInfoISO_TireId_ISig_ 1040;
BA_ "NeedsUpdateBit" SG_ 2566883339 Trailer4TireInfoISO_TireId_ISig_ 1;
BA_ "SystemSignalLongSymbol" SG_ 2566883339 Trailer4TireInfoISO_TireId_ISig_ "Trailer4TireInfoISO_TireId_ISig_3";
BA_ "GenSigCycleTime" SG_ 2566883339 Trailer4TireInfoISO_Active_ISig_ 100;
BA_ "GenSigCycleTimeActive" SG_ 2566883339 Trailer4TireInfoISO_Active_ISig_ 100;
BA_ "GenSigStartValue" SG_ 2566883339 Trailer4TireInfoISO_Active_ISig_ 3;
BA_ "GenSigMaxLatency" SG_ 2566883339 Trailer4TireInfoISO_Active_ISig_ 1040;
BA_ "NeedsUpdateBit" SG_ 2566883339 Trailer4TireInfoISO_Active_ISig_ 1;
BA_ "SystemSignalLongSymbol" SG_ 2566883339 Trailer4TireInfoISO_Active_ISig_ "Trailer4TireInfoISO_Active_ISig_3";
BA_ "GenSigCycleTime" SG_ 2566883339 Trailer4TireInfoISO_PowerSupply_ 100;
BA_ "GenSigCycleTimeActive" SG_ 2566883339 Trailer4TireInfoISO_PowerSupply_ 100;
BA_ "GenSigStartValue" SG_ 2566883339 Trailer4TireInfoISO_PowerSupply_ 3;
BA_ "GenSigMaxLatency" SG_ 2566883339 Trailer4TireInfoISO_PowerSupply_ 1040;
BA_ "NeedsUpdateBit" SG_ 2566883339 Trailer4TireInfoISO_PowerSupply_ 1;
BA_ "SystemSignalLongSymbol" SG_ 2566883339 Trailer4TireInfoISO_PowerSupply_ "Trailer4TireInfoISO_PowerSupply_ISig_3";
BA_ "GenSigCycleTime" SG_ 2566883339 Trailer4TireInfoISO_Temperature_ 100;
BA_ "GenSigCycleTimeActive" SG_ 2566883339 Trailer4TireInfoISO_Temperature_ 100;
BA_ "GenSigStartValue" SG_ 2566883339 Trailer4TireInfoISO_Temperature_ 65535;
BA_ "GenSigMaxLatency" SG_ 2566883339 Trailer4TireInfoISO_Temperature_ 1040;
BA_ "NeedsUpdateBit" SG_ 2566883339 Trailer4TireInfoISO_Temperature_ 1;
BA_ "SystemSignalLongSymbol" SG_ 2566883339 Trailer4TireInfoISO_Temperature_ "Trailer4TireInfoISO_Temperature_ISig_3";
BA_ "GenSigCycleTime" SG_ 2566883339 Trailer4TireInfoISO_Warning_ISig 100;
BA_ "GenSigCycleTimeActive" SG_ 2566883339 Trailer4TireInfoISO_Warning_ISig 100;
BA_ "GenSigStartValue" SG_ 2566883339 Trailer4TireInfoISO_Warning_ISig 7;
BA_ "GenSigMaxLatency" SG_ 2566883339 Trailer4TireInfoISO_Warning_ISig 1040;
BA_ "NeedsUpdateBit" SG_ 2566883339 Trailer4TireInfoISO_Warning_ISig 1;
BA_ "SystemSignalLongSymbol" SG_ 2566883339 Trailer4TireInfoISO_Warning_ISig "Trailer4TireInfoISO_Warning_ISig_3";
BA_ "GenSigCycleTime" SG_ 2566878731 Trailer3TireInfoISO_Warning_ISig 100;
BA_ "GenSigCycleTimeActive" SG_ 2566878731 Trailer3TireInfoISO_Warning_ISig 100;
BA_ "GenSigStartValue" SG_ 2566878731 Trailer3TireInfoISO_Warning_ISig 7;
BA_ "GenSigMaxLatency" SG_ 2566878731 Trailer3TireInfoISO_Warning_ISig 1030;
BA_ "NeedsUpdateBit" SG_ 2566878731 Trailer3TireInfoISO_Warning_ISig 1;
BA_ "SystemSignalLongSymbol" SG_ 2566878731 Trailer3TireInfoISO_Warning_ISig "Trailer3TireInfoISO_Warning_ISig_3";
BA_ "GenSigCycleTime" SG_ 2566878731 Trailer3TireInfoISO_TireId_ISig_ 100;
BA_ "GenSigCycleTimeActive" SG_ 2566878731 Trailer3TireInfoISO_TireId_ISig_ 100;
BA_ "GenSigMaxLatency" SG_ 2566878731 Trailer3TireInfoISO_TireId_ISig_ 1030;
BA_ "NeedsUpdateBit" SG_ 2566878731 Trailer3TireInfoISO_TireId_ISig_ 1;
BA_ "SystemSignalLongSymbol" SG_ 2566878731 Trailer3TireInfoISO_TireId_ISig_ "Trailer3TireInfoISO_TireId_ISig_3";
BA_ "GenSigCycleTime" SG_ 2566878731 Trailer3TireInfoISO_Active_ISig_ 100;
BA_ "GenSigCycleTimeActive" SG_ 2566878731 Trailer3TireInfoISO_Active_ISig_ 100;
BA_ "GenSigStartValue" SG_ 2566878731 Trailer3TireInfoISO_Active_ISig_ 3;
BA_ "GenSigMaxLatency" SG_ 2566878731 Trailer3TireInfoISO_Active_ISig_ 1030;
BA_ "NeedsUpdateBit" SG_ 2566878731 Trailer3TireInfoISO_Active_ISig_ 1;
BA_ "SystemSignalLongSymbol" SG_ 2566878731 Trailer3TireInfoISO_Active_ISig_ "Trailer3TireInfoISO_Active_ISig_3";
BA_ "GenSigSendType" SG_ 2566878731 Trailer3TireInfoISO_sg_UB_ISig_3 7;
BA_ "GenSigCycleTime" SG_ 2566878731 Trailer3TireInfoISO_Leakage_ISig 100;
BA_ "GenSigCycleTimeActive" SG_ 2566878731 Trailer3TireInfoISO_Leakage_ISig 100;
BA_ "GenSigStartValue" SG_ 2566878731 Trailer3TireInfoISO_Leakage_ISig 65535;
BA_ "GenSigMaxLatency" SG_ 2566878731 Trailer3TireInfoISO_Leakage_ISig 1030;
BA_ "NeedsUpdateBit" SG_ 2566878731 Trailer3TireInfoISO_Leakage_ISig 1;
BA_ "SystemSignalLongSymbol" SG_ 2566878731 Trailer3TireInfoISO_Leakage_ISig "Trailer3TireInfoISO_Leakage_ISig_3";
BA_ "GenSigCycleTime" SG_ 2566878731 Trailer3TireInfoISO_Pressure_ISi 100;
BA_ "GenSigCycleTimeActive" SG_ 2566878731 Trailer3TireInfoISO_Pressure_ISi 100;
BA_ "GenSigStartValue" SG_ 2566878731 Trailer3TireInfoISO_Pressure_ISi 255;
BA_ "GenSigMaxLatency" SG_ 2566878731 Trailer3TireInfoISO_Pressure_ISi 1030;
BA_ "NeedsUpdateBit" SG_ 2566878731 Trailer3TireInfoISO_Pressure_ISi 1;
BA_ "SystemSignalLongSymbol" SG_ 2566878731 Trailer3TireInfoISO_Pressure_ISi "Trailer3TireInfoISO_Pressure_ISig_3";
BA_ "GenSigCycleTime" SG_ 2566878731 Trailer3TireInfoISO_PowerSupply_ 100;
BA_ "GenSigCycleTimeActive" SG_ 2566878731 Trailer3TireInfoISO_PowerSupply_ 100;
BA_ "GenSigStartValue" SG_ 2566878731 Trailer3TireInfoISO_PowerSupply_ 3;
BA_ "GenSigMaxLatency" SG_ 2566878731 Trailer3TireInfoISO_PowerSupply_ 1030;
BA_ "NeedsUpdateBit" SG_ 2566878731 Trailer3TireInfoISO_PowerSupply_ 1;
BA_ "SystemSignalLongSymbol" SG_ 2566878731 Trailer3TireInfoISO_PowerSupply_ "Trailer3TireInfoISO_PowerSupply_ISig_3";
BA_ "GenSigCycleTime" SG_ 2566878731 Trailer3TireInfoISO_PresSuff_ISi 100;
BA_ "GenSigCycleTimeActive" SG_ 2566878731 Trailer3TireInfoISO_PresSuff_ISi 100;
BA_ "GenSigStartValue" SG_ 2566878731 Trailer3TireInfoISO_PresSuff_ISi 3;
BA_ "GenSigMaxLatency" SG_ 2566878731 Trailer3TireInfoISO_PresSuff_ISi 1030;
BA_ "NeedsUpdateBit" SG_ 2566878731 Trailer3TireInfoISO_PresSuff_ISi 1;
BA_ "SystemSignalLongSymbol" SG_ 2566878731 Trailer3TireInfoISO_PresSuff_ISi "Trailer3TireInfoISO_PresSuff_ISig_3";
BA_ "GenSigCycleTime" SG_ 2566878731 Trailer3TireInfoISO_Temperature_ 100;
BA_ "GenSigCycleTimeActive" SG_ 2566878731 Trailer3TireInfoISO_Temperature_ 100;
BA_ "GenSigStartValue" SG_ 2566878731 Trailer3TireInfoISO_Temperature_ 65535;
BA_ "GenSigMaxLatency" SG_ 2566878731 Trailer3TireInfoISO_Temperature_ 1030;
BA_ "NeedsUpdateBit" SG_ 2566878731 Trailer3TireInfoISO_Temperature_ 1;
BA_ "SystemSignalLongSymbol" SG_ 2566878731 Trailer3TireInfoISO_Temperature_ "Trailer3TireInfoISO_Temperature_ISig_3";
BA_ "GenSigCycleTime" SG_ 2566874123 Trailer2TireInfoISO_PowerSupply_ 100;
BA_ "GenSigCycleTimeActive" SG_ 2566874123 Trailer2TireInfoISO_PowerSupply_ 100;
BA_ "GenSigStartValue" SG_ 2566874123 Trailer2TireInfoISO_PowerSupply_ 3;
BA_ "GenSigMaxLatency" SG_ 2566874123 Trailer2TireInfoISO_PowerSupply_ 1020;
BA_ "NeedsUpdateBit" SG_ 2566874123 Trailer2TireInfoISO_PowerSupply_ 1;
BA_ "SystemSignalLongSymbol" SG_ 2566874123 Trailer2TireInfoISO_PowerSupply_ "Trailer2TireInfoISO_PowerSupply_ISig_3";
BA_ "GenSigCycleTime" SG_ 2566874123 Trailer2TireInfoISO_Leakage_ISig 100;
BA_ "GenSigCycleTimeActive" SG_ 2566874123 Trailer2TireInfoISO_Leakage_ISig 100;
BA_ "GenSigStartValue" SG_ 2566874123 Trailer2TireInfoISO_Leakage_ISig 65535;
BA_ "GenSigMaxLatency" SG_ 2566874123 Trailer2TireInfoISO_Leakage_ISig 1020;
BA_ "NeedsUpdateBit" SG_ 2566874123 Trailer2TireInfoISO_Leakage_ISig 1;
BA_ "SystemSignalLongSymbol" SG_ 2566874123 Trailer2TireInfoISO_Leakage_ISig "Trailer2TireInfoISO_Leakage_ISig_3";
BA_ "GenSigCycleTime" SG_ 2566874123 Trailer2TireInfoISO_Active_ISig_ 100;
BA_ "GenSigCycleTimeActive" SG_ 2566874123 Trailer2TireInfoISO_Active_ISig_ 100;
BA_ "GenSigStartValue" SG_ 2566874123 Trailer2TireInfoISO_Active_ISig_ 3;
BA_ "GenSigMaxLatency" SG_ 2566874123 Trailer2TireInfoISO_Active_ISig_ 1020;
BA_ "NeedsUpdateBit" SG_ 2566874123 Trailer2TireInfoISO_Active_ISig_ 1;
BA_ "SystemSignalLongSymbol" SG_ 2566874123 Trailer2TireInfoISO_Active_ISig_ "Trailer2TireInfoISO_Active_ISig_3";
BA_ "GenSigCycleTime" SG_ 2566874123 Trailer2TireInfoISO_PresSuff_ISi 100;
BA_ "GenSigCycleTimeActive" SG_ 2566874123 Trailer2TireInfoISO_PresSuff_ISi 100;
BA_ "GenSigStartValue" SG_ 2566874123 Trailer2TireInfoISO_PresSuff_ISi 3;
BA_ "GenSigMaxLatency" SG_ 2566874123 Trailer2TireInfoISO_PresSuff_ISi 1020;
BA_ "NeedsUpdateBit" SG_ 2566874123 Trailer2TireInfoISO_PresSuff_ISi 1;
BA_ "SystemSignalLongSymbol" SG_ 2566874123 Trailer2TireInfoISO_PresSuff_ISi "Trailer2TireInfoISO_PresSuff_ISig_3";
BA_ "GenSigCycleTime" SG_ 2566874123 Trailer2TireInfoISO_Temperature_ 100;
BA_ "GenSigCycleTimeActive" SG_ 2566874123 Trailer2TireInfoISO_Temperature_ 100;
BA_ "GenSigStartValue" SG_ 2566874123 Trailer2TireInfoISO_Temperature_ 65535;
BA_ "GenSigMaxLatency" SG_ 2566874123 Trailer2TireInfoISO_Temperature_ 1020;
BA_ "NeedsUpdateBit" SG_ 2566874123 Trailer2TireInfoISO_Temperature_ 1;
BA_ "SystemSignalLongSymbol" SG_ 2566874123 Trailer2TireInfoISO_Temperature_ "Trailer2TireInfoISO_Temperature_ISig_3";
BA_ "GenSigCycleTime" SG_ 2566874123 Trailer2TireInfoISO_Pressure_ISi 100;
BA_ "GenSigCycleTimeActive" SG_ 2566874123 Trailer2TireInfoISO_Pressure_ISi 100;
BA_ "GenSigStartValue" SG_ 2566874123 Trailer2TireInfoISO_Pressure_ISi 255;
BA_ "GenSigMaxLatency" SG_ 2566874123 Trailer2TireInfoISO_Pressure_ISi 1020;
BA_ "NeedsUpdateBit" SG_ 2566874123 Trailer2TireInfoISO_Pressure_ISi 1;
BA_ "SystemSignalLongSymbol" SG_ 2566874123 Trailer2TireInfoISO_Pressure_ISi "Trailer2TireInfoISO_Pressure_ISig_3";
BA_ "GenSigCycleTime" SG_ 2566874123 Trailer2TireInfoISO_Warning_ISig 100;
BA_ "GenSigCycleTimeActive" SG_ 2566874123 Trailer2TireInfoISO_Warning_ISig 100;
BA_ "GenSigStartValue" SG_ 2566874123 Trailer2TireInfoISO_Warning_ISig 7;
BA_ "GenSigMaxLatency" SG_ 2566874123 Trailer2TireInfoISO_Warning_ISig 1020;
BA_ "NeedsUpdateBit" SG_ 2566874123 Trailer2TireInfoISO_Warning_ISig 1;
BA_ "SystemSignalLongSymbol" SG_ 2566874123 Trailer2TireInfoISO_Warning_ISig "Trailer2TireInfoISO_Warning_ISig_3";
BA_ "GenSigSendType" SG_ 2566874123 Trailer2TireInfoISO_sg_UB_ISig_3 7;
BA_ "GenSigCycleTime" SG_ 2566874123 Trailer2TireInfoISO_TireId_ISig_ 100;
BA_ "GenSigCycleTimeActive" SG_ 2566874123 Trailer2TireInfoISO_TireId_ISig_ 100;
BA_ "GenSigMaxLatency" SG_ 2566874123 Trailer2TireInfoISO_TireId_ISig_ 1020;
BA_ "NeedsUpdateBit" SG_ 2566874123 Trailer2TireInfoISO_TireId_ISig_ 1;
BA_ "SystemSignalLongSymbol" SG_ 2566874123 Trailer2TireInfoISO_TireId_ISig_ "Trailer2TireInfoISO_TireId_ISig_3";
BA_ "GenSigCycleTime" SG_ 2566869259 Trailer1TireInfoISO_Warning_ISig 100;
BA_ "GenSigCycleTimeActive" SG_ 2566869259 Trailer1TireInfoISO_Warning_ISig 100;
BA_ "GenSigStartValue" SG_ 2566869259 Trailer1TireInfoISO_Warning_ISig 7;
BA_ "GenSigMaxLatency" SG_ 2566869259 Trailer1TireInfoISO_Warning_ISig 1010;
BA_ "NeedsUpdateBit" SG_ 2566869259 Trailer1TireInfoISO_Warning_ISig 1;
BA_ "SystemSignalLongSymbol" SG_ 2566869259 Trailer1TireInfoISO_Warning_ISig "Trailer1TireInfoISO_Warning_ISig_3";
BA_ "GenSigCycleTime" SG_ 2566869259 Trailer1TireInfoISO_PowerSupply_ 100;
BA_ "GenSigCycleTimeActive" SG_ 2566869259 Trailer1TireInfoISO_PowerSupply_ 100;
BA_ "GenSigStartValue" SG_ 2566869259 Trailer1TireInfoISO_PowerSupply_ 3;
BA_ "GenSigMaxLatency" SG_ 2566869259 Trailer1TireInfoISO_PowerSupply_ 1010;
BA_ "NeedsUpdateBit" SG_ 2566869259 Trailer1TireInfoISO_PowerSupply_ 1;
BA_ "SystemSignalLongSymbol" SG_ 2566869259 Trailer1TireInfoISO_PowerSupply_ "Trailer1TireInfoISO_PowerSupply_ISig_3";
BA_ "GenSigCycleTime" SG_ 2566869259 Trailer1TireInfoISO_PresSuff_ISi 100;
BA_ "GenSigCycleTimeActive" SG_ 2566869259 Trailer1TireInfoISO_PresSuff_ISi 100;
BA_ "GenSigStartValue" SG_ 2566869259 Trailer1TireInfoISO_PresSuff_ISi 3;
BA_ "GenSigMaxLatency" SG_ 2566869259 Trailer1TireInfoISO_PresSuff_ISi 1010;
BA_ "NeedsUpdateBit" SG_ 2566869259 Trailer1TireInfoISO_PresSuff_ISi 1;
BA_ "SystemSignalLongSymbol" SG_ 2566869259 Trailer1TireInfoISO_PresSuff_ISi "Trailer1TireInfoISO_PresSuff_ISig_3";
BA_ "GenSigCycleTime" SG_ 2566869259 Trailer1TireInfoISO_Active_ISig_ 100;
BA_ "GenSigCycleTimeActive" SG_ 2566869259 Trailer1TireInfoISO_Active_ISig_ 100;
BA_ "GenSigStartValue" SG_ 2566869259 Trailer1TireInfoISO_Active_ISig_ 3;
BA_ "GenSigMaxLatency" SG_ 2566869259 Trailer1TireInfoISO_Active_ISig_ 1010;
BA_ "NeedsUpdateBit" SG_ 2566869259 Trailer1TireInfoISO_Active_ISig_ 1;
BA_ "SystemSignalLongSymbol" SG_ 2566869259 Trailer1TireInfoISO_Active_ISig_ "Trailer1TireInfoISO_Active_ISig_3";
BA_ "GenSigCycleTime" SG_ 2566869259 Trailer1TireInfoISO_Leakage_ISig 100;
BA_ "GenSigCycleTimeActive" SG_ 2566869259 Trailer1TireInfoISO_Leakage_ISig 100;
BA_ "GenSigStartValue" SG_ 2566869259 Trailer1TireInfoISO_Leakage_ISig 65535;
BA_ "GenSigMaxLatency" SG_ 2566869259 Trailer1TireInfoISO_Leakage_ISig 1010;
BA_ "NeedsUpdateBit" SG_ 2566869259 Trailer1TireInfoISO_Leakage_ISig 1;
BA_ "SystemSignalLongSymbol" SG_ 2566869259 Trailer1TireInfoISO_Leakage_ISig "Trailer1TireInfoISO_Leakage_ISig_3";
BA_ "GenSigCycleTime" SG_ 2566869259 Trailer1TireInfoISO_Temperature_ 100;
BA_ "GenSigCycleTimeActive" SG_ 2566869259 Trailer1TireInfoISO_Temperature_ 100;
BA_ "GenSigStartValue" SG_ 2566869259 Trailer1TireInfoISO_Temperature_ 65535;
BA_ "GenSigMaxLatency" SG_ 2566869259 Trailer1TireInfoISO_Temperature_ 1010;
BA_ "NeedsUpdateBit" SG_ 2566869259 Trailer1TireInfoISO_Temperature_ 1;
BA_ "SystemSignalLongSymbol" SG_ 2566869259 Trailer1TireInfoISO_Temperature_ "Trailer1TireInfoISO_Temperature_ISig_3";
BA_ "GenSigSendType" SG_ 2566869259 Trailer1TireInfoISO_sg_UB_ISig_3 7;
BA_ "GenSigCycleTime" SG_ 2566869259 Trailer1TireInfoISO_Pressure_ISi 100;
BA_ "GenSigCycleTimeActive" SG_ 2566869259 Trailer1TireInfoISO_Pressure_ISi 100;
BA_ "GenSigStartValue" SG_ 2566869259 Trailer1TireInfoISO_Pressure_ISi 255;
BA_ "GenSigMaxLatency" SG_ 2566869259 Trailer1TireInfoISO_Pressure_ISi 1010;
BA_ "NeedsUpdateBit" SG_ 2566869259 Trailer1TireInfoISO_Pressure_ISi 1;
BA_ "SystemSignalLongSymbol" SG_ 2566869259 Trailer1TireInfoISO_Pressure_ISi "Trailer1TireInfoISO_Pressure_ISig_3";
BA_ "GenSigCycleTime" SG_ 2566869259 Trailer1TireInfoISO_TireId_ISig_ 100;
BA_ "GenSigCycleTimeActive" SG_ 2566869259 Trailer1TireInfoISO_TireId_ISig_ 100;
BA_ "GenSigMaxLatency" SG_ 2566869259 Trailer1TireInfoISO_TireId_ISig_ 1010;
BA_ "NeedsUpdateBit" SG_ 2566869259 Trailer1TireInfoISO_TireId_ISig_ 1;
BA_ "SystemSignalLongSymbol" SG_ 2566869259 Trailer1TireInfoISO_TireId_ISig_ "Trailer1TireInfoISO_TireId_ISig_3";
BA_ "GenSigCycleTime" SG_ 2566864651 Trailer5BrakeTemp_Temp_ISig_3 100;
BA_ "GenSigCycleTimeActive" SG_ 2566864651 Trailer5BrakeTemp_Temp_ISig_3 100;
BA_ "GenSigStartValue" SG_ 2566864651 Trailer5BrakeTemp_Temp_ISig_3 255;
BA_ "GenSigMaxLatency" SG_ 2566864651 Trailer5BrakeTemp_Temp_ISig_3 125;
BA_ "GenSigCycleTime" SG_ 2566864651 Trailer4BrakeTemp_TireId_ISig_3 100;
BA_ "GenSigCycleTimeActive" SG_ 2566864651 Trailer4BrakeTemp_TireId_ISig_3 100;
BA_ "GenSigStartValue" SG_ 2566864651 Trailer4BrakeTemp_TireId_ISig_3 255;
BA_ "GenSigMaxLatency" SG_ 2566864651 Trailer4BrakeTemp_TireId_ISig_3 125;
BA_ "GenSigCycleTime" SG_ 2566864651 Trailer5BrakeTemp_Status_ISig_3 100;
BA_ "GenSigCycleTimeActive" SG_ 2566864651 Trailer5BrakeTemp_Status_ISig_3 100;
BA_ "GenSigStartValue" SG_ 2566864651 Trailer5BrakeTemp_Status_ISig_3 3;
BA_ "GenSigMaxLatency" SG_ 2566864651 Trailer5BrakeTemp_Status_ISig_3 125;
BA_ "GenSigCycleTime" SG_ 2566864651 Trailer4BrakeTemp_Status_ISig_3 100;
BA_ "GenSigCycleTimeActive" SG_ 2566864651 Trailer4BrakeTemp_Status_ISig_3 100;
BA_ "GenSigStartValue" SG_ 2566864651 Trailer4BrakeTemp_Status_ISig_3 3;
BA_ "GenSigMaxLatency" SG_ 2566864651 Trailer4BrakeTemp_Status_ISig_3 125;
BA_ "GenSigCycleTime" SG_ 2566864651 Trailer4BrakeTemp_Temp_ISig_3 100;
BA_ "GenSigCycleTimeActive" SG_ 2566864651 Trailer4BrakeTemp_Temp_ISig_3 100;
BA_ "GenSigStartValue" SG_ 2566864651 Trailer4BrakeTemp_Temp_ISig_3 255;
BA_ "GenSigMaxLatency" SG_ 2566864651 Trailer4BrakeTemp_Temp_ISig_3 125;
BA_ "GenSigCycleTime" SG_ 2566864651 Trailer5BrakeTemp_TireId_ISig_3 100;
BA_ "GenSigCycleTimeActive" SG_ 2566864651 Trailer5BrakeTemp_TireId_ISig_3 100;
BA_ "GenSigStartValue" SG_ 2566864651 Trailer5BrakeTemp_TireId_ISig_3 255;
BA_ "GenSigMaxLatency" SG_ 2566864651 Trailer5BrakeTemp_TireId_ISig_3 125;
BA_ "GenSigCycleTime" SG_ 2566860043 Trailer2BrakeTemp_TireId_ISig_3 100;
BA_ "GenSigCycleTimeActive" SG_ 2566860043 Trailer2BrakeTemp_TireId_ISig_3 100;
BA_ "GenSigStartValue" SG_ 2566860043 Trailer2BrakeTemp_TireId_ISig_3 255;
BA_ "GenSigMaxLatency" SG_ 2566860043 Trailer2BrakeTemp_TireId_ISig_3 120;
BA_ "GenSigCycleTime" SG_ 2566860043 Trailer1BrakeTemp_Status_ISig_3 100;
BA_ "GenSigCycleTimeActive" SG_ 2566860043 Trailer1BrakeTemp_Status_ISig_3 100;
BA_ "GenSigStartValue" SG_ 2566860043 Trailer1BrakeTemp_Status_ISig_3 3;
BA_ "GenSigMaxLatency" SG_ 2566860043 Trailer1BrakeTemp_Status_ISig_3 120;
BA_ "GenSigCycleTime" SG_ 2566860043 Trailer2BrakeTemp_Status_ISig_3 100;
BA_ "GenSigCycleTimeActive" SG_ 2566860043 Trailer2BrakeTemp_Status_ISig_3 100;
BA_ "GenSigStartValue" SG_ 2566860043 Trailer2BrakeTemp_Status_ISig_3 3;
BA_ "GenSigMaxLatency" SG_ 2566860043 Trailer2BrakeTemp_Status_ISig_3 120;
BA_ "GenSigCycleTime" SG_ 2566860043 Trailer1BrakeTemp_TireId_ISig_3 100;
BA_ "GenSigCycleTimeActive" SG_ 2566860043 Trailer1BrakeTemp_TireId_ISig_3 100;
BA_ "GenSigStartValue" SG_ 2566860043 Trailer1BrakeTemp_TireId_ISig_3 255;
BA_ "GenSigMaxLatency" SG_ 2566860043 Trailer1BrakeTemp_TireId_ISig_3 120;
BA_ "GenSigCycleTime" SG_ 2566860043 Trailer1BrakeTemp_Temp_ISig_3 100;
BA_ "GenSigCycleTimeActive" SG_ 2566860043 Trailer1BrakeTemp_Temp_ISig_3 100;
BA_ "GenSigStartValue" SG_ 2566860043 Trailer1BrakeTemp_Temp_ISig_3 255;
BA_ "GenSigMaxLatency" SG_ 2566860043 Trailer1BrakeTemp_Temp_ISig_3 120;
BA_ "GenSigCycleTime" SG_ 2566860043 Trailer3BrakeTemp_Status_ISig_3 100;
BA_ "GenSigCycleTimeActive" SG_ 2566860043 Trailer3BrakeTemp_Status_ISig_3 100;
BA_ "GenSigStartValue" SG_ 2566860043 Trailer3BrakeTemp_Status_ISig_3 3;
BA_ "GenSigMaxLatency" SG_ 2566860043 Trailer3BrakeTemp_Status_ISig_3 120;
BA_ "GenSigCycleTime" SG_ 2566860043 Trailer3BrakeTemp_Temp_ISig_3 100;
BA_ "GenSigCycleTimeActive" SG_ 2566860043 Trailer3BrakeTemp_Temp_ISig_3 100;
BA_ "GenSigStartValue" SG_ 2566860043 Trailer3BrakeTemp_Temp_ISig_3 255;
BA_ "GenSigMaxLatency" SG_ 2566860043 Trailer3BrakeTemp_Temp_ISig_3 120;
BA_ "GenSigCycleTime" SG_ 2566860043 Trailer3BrakeTemp_TireId_ISig_3 100;
BA_ "GenSigCycleTimeActive" SG_ 2566860043 Trailer3BrakeTemp_TireId_ISig_3 100;
BA_ "GenSigStartValue" SG_ 2566860043 Trailer3BrakeTemp_TireId_ISig_3 255;
BA_ "GenSigMaxLatency" SG_ 2566860043 Trailer3BrakeTemp_TireId_ISig_3 120;
BA_ "GenSigCycleTime" SG_ 2566860043 Trailer2BrakeTemp_Temp_ISig_3 100;
BA_ "GenSigCycleTimeActive" SG_ 2566860043 Trailer2BrakeTemp_Temp_ISig_3 100;
BA_ "GenSigStartValue" SG_ 2566860043 Trailer2BrakeTemp_Temp_ISig_3 255;
BA_ "GenSigMaxLatency" SG_ 2566860043 Trailer2BrakeTemp_Temp_ISig_3 120;
BA_ "GenSigCycleTime" SG_ 2566855435 Trailer4ABSStatus_ISig_3 100;
BA_ "GenSigCycleTimeActive" SG_ 2566855435 Trailer4ABSStatus_ISig_3 100;
BA_ "GenSigStartValue" SG_ 2566855435 Trailer4ABSStatus_ISig_3 3;
BA_ "GenSigMaxLatency" SG_ 2566855435 Trailer4ABSStatus_ISig_3 110;
BA_ "GenSigCycleTime" SG_ 2566855435 Trailer5ABSStatus_ISig_3 100;
BA_ "GenSigCycleTimeActive" SG_ 2566855435 Trailer5ABSStatus_ISig_3 100;
BA_ "GenSigStartValue" SG_ 2566855435 Trailer5ABSStatus_ISig_3 3;
BA_ "GenSigMaxLatency" SG_ 2566855435 Trailer5ABSStatus_ISig_3 110;
BA_ "GenSigCycleTime" SG_ 2566855435 Trailer2ABSStatus_ISig_3 100;
BA_ "GenSigCycleTimeActive" SG_ 2566855435 Trailer2ABSStatus_ISig_3 100;
BA_ "GenSigStartValue" SG_ 2566855435 Trailer2ABSStatus_ISig_3 3;
BA_ "GenSigMaxLatency" SG_ 2566855435 Trailer2ABSStatus_ISig_3 110;
BA_ "GenSigCycleTime" SG_ 2566855435 Trailer1ABSStatus_ISig_3 100;
BA_ "GenSigCycleTimeActive" SG_ 2566855435 Trailer1ABSStatus_ISig_3 100;
BA_ "GenSigStartValue" SG_ 2566855435 Trailer1ABSStatus_ISig_3 3;
BA_ "GenSigMaxLatency" SG_ 2566855435 Trailer1ABSStatus_ISig_3 110;
BA_ "GenSigCycleTime" SG_ 2566855435 Trailer3ABSStatus_ISig_3 100;
BA_ "GenSigCycleTimeActive" SG_ 2566855435 Trailer3ABSStatus_ISig_3 100;
BA_ "GenSigStartValue" SG_ 2566855435 Trailer3ABSStatus_ISig_3 3;
BA_ "GenSigMaxLatency" SG_ 2566855435 Trailer3ABSStatus_ISig_3 110;
BA_ "GenSigCycleTime" SG_ 2566855435 Trailer1WheelSpdDiffMainAxle_ISi 100;
BA_ "GenSigCycleTimeActive" SG_ 2566855435 Trailer1WheelSpdDiffMainAxle_ISi 100;
BA_ "GenSigStartValue" SG_ 2566855435 Trailer1WheelSpdDiffMainAxle_ISi 65535;
BA_ "GenSigMaxLatency" SG_ 2566855435 Trailer1WheelSpdDiffMainAxle_ISi 110;
BA_ "SystemSignalLongSymbol" SG_ 2566855435 Trailer1WheelSpdDiffMainAxle_ISi "Trailer1WheelSpdDiffMainAxle_ISig_3";
BA_ "GenSigCycleTime" SG_ 2566855435 Trailer1LateralAcceleration_ISig 100;
BA_ "GenSigCycleTimeActive" SG_ 2566855435 Trailer1LateralAcceleration_ISig 100;
BA_ "GenSigStartValue" SG_ 2566855435 Trailer1LateralAcceleration_ISig 255;
BA_ "GenSigMaxLatency" SG_ 2566855435 Trailer1LateralAcceleration_ISig 110;
BA_ "SystemSignalLongSymbol" SG_ 2566855435 Trailer1LateralAcceleration_ISig "Trailer1LateralAcceleration_ISig_3";
BA_ "GenSigCycleTime" SG_ 2566850827 Trailer5NormalLevelStorStat_ISig 100;
BA_ "GenSigCycleTimeActive" SG_ 2566850827 Trailer5NormalLevelStorStat_ISig 100;
BA_ "GenSigStartValue" SG_ 2566850827 Trailer5NormalLevelStorStat_ISig 3;
BA_ "GenSigMaxLatency" SG_ 2566850827 Trailer5NormalLevelStorStat_ISig 105;
BA_ "SystemSignalLongSymbol" SG_ 2566850827 Trailer5NormalLevelStorStat_ISig "Trailer5NormalLevelStorStat_ISig_3";
BA_ "GenSigCycleTime" SG_ 2566850827 Trailer4TractionHelp_ISig_3 100;
BA_ "GenSigCycleTimeActive" SG_ 2566850827 Trailer4TractionHelp_ISig_3 100;
BA_ "GenSigStartValue" SG_ 2566850827 Trailer4TractionHelp_ISig_3 3;
BA_ "GenSigMaxLatency" SG_ 2566850827 Trailer4TractionHelp_ISig_3 105;
BA_ "GenSigCycleTime" SG_ 2566850827 Trailer2TractionHelp_ISig_3 100;
BA_ "GenSigCycleTimeActive" SG_ 2566850827 Trailer2TractionHelp_ISig_3 100;
BA_ "GenSigStartValue" SG_ 2566850827 Trailer2TractionHelp_ISig_3 3;
BA_ "GenSigMaxLatency" SG_ 2566850827 Trailer2TractionHelp_ISig_3 105;
BA_ "GenSigCycleTime" SG_ 2566850827 Trailer3StopLevelChangeAck_ISig_ 100;
BA_ "GenSigCycleTimeActive" SG_ 2566850827 Trailer3StopLevelChangeAck_ISig_ 100;
BA_ "GenSigStartValue" SG_ 2566850827 Trailer3StopLevelChangeAck_ISig_ 3;
BA_ "GenSigMaxLatency" SG_ 2566850827 Trailer3StopLevelChangeAck_ISig_ 105;
BA_ "SystemSignalLongSymbol" SG_ 2566850827 Trailer3StopLevelChangeAck_ISig_ "Trailer3StopLevelChangeAck_ISig_3";
BA_ "GenSigCycleTime" SG_ 2566850827 Trailer4LevelChangeFrontAxle_ISi 100;
BA_ "GenSigCycleTimeActive" SG_ 2566850827 Trailer4LevelChangeFrontAxle_ISi 100;
BA_ "GenSigStartValue" SG_ 2566850827 Trailer4LevelChangeFrontAxle_ISi 3;
BA_ "GenSigMaxLatency" SG_ 2566850827 Trailer4LevelChangeFrontAxle_ISi 105;
BA_ "SystemSignalLongSymbol" SG_ 2566850827 Trailer4LevelChangeFrontAxle_ISi "Trailer4LevelChangeFrontAxle_ISig_3";
BA_ "GenSigCycleTime" SG_ 2566850827 Trailer1NormalLevelStorStat_ISig 100;
BA_ "GenSigCycleTimeActive" SG_ 2566850827 Trailer1NormalLevelStorStat_ISig 100;
BA_ "GenSigStartValue" SG_ 2566850827 Trailer1NormalLevelStorStat_ISig 3;
BA_ "GenSigMaxLatency" SG_ 2566850827 Trailer1NormalLevelStorStat_ISig 105;
BA_ "SystemSignalLongSymbol" SG_ 2566850827 Trailer1NormalLevelStorStat_ISig "Trailer1NormalLevelStorStat_ISig_3";
BA_ "GenSigCycleTime" SG_ 2566850827 Trailer1StopLevelChangeAck_ISig_ 100;
BA_ "GenSigCycleTimeActive" SG_ 2566850827 Trailer1StopLevelChangeAck_ISig_ 100;
BA_ "GenSigStartValue" SG_ 2566850827 Trailer1StopLevelChangeAck_ISig_ 3;
BA_ "GenSigMaxLatency" SG_ 2566850827 Trailer1StopLevelChangeAck_ISig_ 105;
BA_ "SystemSignalLongSymbol" SG_ 2566850827 Trailer1StopLevelChangeAck_ISig_ "Trailer1StopLevelChangeAck_ISig_3";
BA_ "GenSigCycleTime" SG_ 2566850827 Trailer3LevelChangeFrontAxle_ISi 100;
BA_ "GenSigCycleTimeActive" SG_ 2566850827 Trailer3LevelChangeFrontAxle_ISi 100;
BA_ "GenSigStartValue" SG_ 2566850827 Trailer3LevelChangeFrontAxle_ISi 3;
BA_ "GenSigMaxLatency" SG_ 2566850827 Trailer3LevelChangeFrontAxle_ISi 105;
BA_ "SystemSignalLongSymbol" SG_ 2566850827 Trailer3LevelChangeFrontAxle_ISi "Trailer3LevelChangeFrontAxle_ISig_3";
BA_ "GenSigCycleTime" SG_ 2566850827 Trailer5RampLevelStorStat_ISig_3 100;
BA_ "GenSigCycleTimeActive" SG_ 2566850827 Trailer5RampLevelStorStat_ISig_3 100;
BA_ "GenSigStartValue" SG_ 2566850827 Trailer5RampLevelStorStat_ISig_3 3;
BA_ "GenSigMaxLatency" SG_ 2566850827 Trailer5RampLevelStorStat_ISig_3 105;
BA_ "GenSigCycleTime" SG_ 2566850827 Trailer4LevelChangeRearAxle_ISig 100;
BA_ "GenSigCycleTimeActive" SG_ 2566850827 Trailer4LevelChangeRearAxle_ISig 100;
BA_ "GenSigStartValue" SG_ 2566850827 Trailer4LevelChangeRearAxle_ISig 3;
BA_ "GenSigMaxLatency" SG_ 2566850827 Trailer4LevelChangeRearAxle_ISig 105;
BA_ "SystemSignalLongSymbol" SG_ 2566850827 Trailer4LevelChangeRearAxle_ISig "Trailer4LevelChangeRearAxle_ISig_3";
BA_ "GenSigCycleTime" SG_ 2566850827 Trailer2LevelChangeFrontAxle_ISi 100;
BA_ "GenSigCycleTimeActive" SG_ 2566850827 Trailer2LevelChangeFrontAxle_ISi 100;
BA_ "GenSigStartValue" SG_ 2566850827 Trailer2LevelChangeFrontAxle_ISi 3;
BA_ "GenSigMaxLatency" SG_ 2566850827 Trailer2LevelChangeFrontAxle_ISi 105;
BA_ "SystemSignalLongSymbol" SG_ 2566850827 Trailer2LevelChangeFrontAxle_ISi "Trailer2LevelChangeFrontAxle_ISig_3";
BA_ "GenSigCycleTime" SG_ 2566850827 Trailer2RampLevelStorStat_ISig_3 100;
BA_ "GenSigCycleTimeActive" SG_ 2566850827 Trailer2RampLevelStorStat_ISig_3 100;
BA_ "GenSigStartValue" SG_ 2566850827 Trailer2RampLevelStorStat_ISig_3 3;
BA_ "GenSigMaxLatency" SG_ 2566850827 Trailer2RampLevelStorStat_ISig_3 105;
BA_ "GenSigCycleTime" SG_ 2566850827 Trailer4StopLevelChangeAck_ISig_ 100;
BA_ "GenSigCycleTimeActive" SG_ 2566850827 Trailer4StopLevelChangeAck_ISig_ 100;
BA_ "GenSigStartValue" SG_ 2566850827 Trailer4StopLevelChangeAck_ISig_ 3;
BA_ "GenSigMaxLatency" SG_ 2566850827 Trailer4StopLevelChangeAck_ISig_ 105;
BA_ "SystemSignalLongSymbol" SG_ 2566850827 Trailer4StopLevelChangeAck_ISig_ "Trailer4StopLevelChangeAck_ISig_3";
BA_ "GenSigCycleTime" SG_ 2566850827 Trailer3NormalLevelStorStat_ISig 100;
BA_ "GenSigCycleTimeActive" SG_ 2566850827 Trailer3NormalLevelStorStat_ISig 100;
BA_ "GenSigStartValue" SG_ 2566850827 Trailer3NormalLevelStorStat_ISig 3;
BA_ "GenSigMaxLatency" SG_ 2566850827 Trailer3NormalLevelStorStat_ISig 105;
BA_ "SystemSignalLongSymbol" SG_ 2566850827 Trailer3NormalLevelStorStat_ISig "Trailer3NormalLevelStorStat_ISig_3";
BA_ "GenSigCycleTime" SG_ 2566850827 Trailer1TractionHelp_ISig_3 100;
BA_ "GenSigCycleTimeActive" SG_ 2566850827 Trailer1TractionHelp_ISig_3 100;
BA_ "GenSigStartValue" SG_ 2566850827 Trailer1TractionHelp_ISig_3 3;
BA_ "GenSigMaxLatency" SG_ 2566850827 Trailer1TractionHelp_ISig_3 105;
BA_ "GenSigCycleTime" SG_ 2566850827 Trailer1LevelChangeRearAxle_ISig 100;
BA_ "GenSigCycleTimeActive" SG_ 2566850827 Trailer1LevelChangeRearAxle_ISig 100;
BA_ "GenSigStartValue" SG_ 2566850827 Trailer1LevelChangeRearAxle_ISig 3;
BA_ "GenSigMaxLatency" SG_ 2566850827 Trailer1LevelChangeRearAxle_ISig 105;
BA_ "SystemSignalLongSymbol" SG_ 2566850827 Trailer1LevelChangeRearAxle_ISig "Trailer1LevelChangeRearAxle_ISig_3";
BA_ "GenSigCycleTime" SG_ 2566850827 Trailer5LevelChangeFrontAxle_ISi 100;
BA_ "GenSigCycleTimeActive" SG_ 2566850827 Trailer5LevelChangeFrontAxle_ISi 100;
BA_ "GenSigStartValue" SG_ 2566850827 Trailer5LevelChangeFrontAxle_ISi 3;
BA_ "GenSigMaxLatency" SG_ 2566850827 Trailer5LevelChangeFrontAxle_ISi 105;
BA_ "SystemSignalLongSymbol" SG_ 2566850827 Trailer5LevelChangeFrontAxle_ISi "Trailer5LevelChangeFrontAxle_ISig_3";
BA_ "GenSigCycleTime" SG_ 2566850827 Trailer5StopLevelChangeAck_ISig_ 100;
BA_ "GenSigCycleTimeActive" SG_ 2566850827 Trailer5StopLevelChangeAck_ISig_ 100;
BA_ "GenSigStartValue" SG_ 2566850827 Trailer5StopLevelChangeAck_ISig_ 3;
BA_ "GenSigMaxLatency" SG_ 2566850827 Trailer5StopLevelChangeAck_ISig_ 105;
BA_ "SystemSignalLongSymbol" SG_ 2566850827 Trailer5StopLevelChangeAck_ISig_ "Trailer5StopLevelChangeAck_ISig_3";
BA_ "GenSigCycleTime" SG_ 2566850827 Trailer5TractionHelp_ISig_3 100;
BA_ "GenSigCycleTimeActive" SG_ 2566850827 Trailer5TractionHelp_ISig_3 100;
BA_ "GenSigStartValue" SG_ 2566850827 Trailer5TractionHelp_ISig_3 3;
BA_ "GenSigMaxLatency" SG_ 2566850827 Trailer5TractionHelp_ISig_3 105;
BA_ "GenSigCycleTime" SG_ 2566850827 Trailer3RampLevelStorStat_ISig_3 100;
BA_ "GenSigCycleTimeActive" SG_ 2566850827 Trailer3RampLevelStorStat_ISig_3 100;
BA_ "GenSigStartValue" SG_ 2566850827 Trailer3RampLevelStorStat_ISig_3 3;
BA_ "GenSigMaxLatency" SG_ 2566850827 Trailer3RampLevelStorStat_ISig_3 105;
BA_ "GenSigCycleTime" SG_ 2566850827 Trailer2LevelChangeRearAxle_ISig 100;
BA_ "GenSigCycleTimeActive" SG_ 2566850827 Trailer2LevelChangeRearAxle_ISig 100;
BA_ "GenSigStartValue" SG_ 2566850827 Trailer2LevelChangeRearAxle_ISig 3;
BA_ "GenSigMaxLatency" SG_ 2566850827 Trailer2LevelChangeRearAxle_ISig 105;
BA_ "SystemSignalLongSymbol" SG_ 2566850827 Trailer2LevelChangeRearAxle_ISig "Trailer2LevelChangeRearAxle_ISig_3";
BA_ "GenSigCycleTime" SG_ 2566850827 Trailer2StopLevelChangeAck_ISig_ 100;
BA_ "GenSigCycleTimeActive" SG_ 2566850827 Trailer2StopLevelChangeAck_ISig_ 100;
BA_ "GenSigStartValue" SG_ 2566850827 Trailer2StopLevelChangeAck_ISig_ 3;
BA_ "GenSigMaxLatency" SG_ 2566850827 Trailer2StopLevelChangeAck_ISig_ 105;
BA_ "SystemSignalLongSymbol" SG_ 2566850827 Trailer2StopLevelChangeAck_ISig_ "Trailer2StopLevelChangeAck_ISig_3";
BA_ "GenSigCycleTime" SG_ 2566850827 Trailer3TractionHelp_ISig_3 100;
BA_ "GenSigCycleTimeActive" SG_ 2566850827 Trailer3TractionHelp_ISig_3 100;
BA_ "GenSigStartValue" SG_ 2566850827 Trailer3TractionHelp_ISig_3 3;
BA_ "GenSigMaxLatency" SG_ 2566850827 Trailer3TractionHelp_ISig_3 105;
BA_ "GenSigCycleTime" SG_ 2566850827 Trailer4RampLevelStorStat_ISig_3 100;
BA_ "GenSigCycleTimeActive" SG_ 2566850827 Trailer4RampLevelStorStat_ISig_3 100;
BA_ "GenSigStartValue" SG_ 2566850827 Trailer4RampLevelStorStat_ISig_3 3;
BA_ "GenSigMaxLatency" SG_ 2566850827 Trailer4RampLevelStorStat_ISig_3 105;
BA_ "GenSigCycleTime" SG_ 2566850827 Trailer1RampLevelStorStat_ISig_3 100;
BA_ "GenSigCycleTimeActive" SG_ 2566850827 Trailer1RampLevelStorStat_ISig_3 100;
BA_ "GenSigStartValue" SG_ 2566850827 Trailer1RampLevelStorStat_ISig_3 3;
BA_ "GenSigMaxLatency" SG_ 2566850827 Trailer1RampLevelStorStat_ISig_3 105;
BA_ "GenSigCycleTime" SG_ 2566850827 Trailer1LevelChangeFrontAxle_ISi 100;
BA_ "GenSigCycleTimeActive" SG_ 2566850827 Trailer1LevelChangeFrontAxle_ISi 100;
BA_ "GenSigStartValue" SG_ 2566850827 Trailer1LevelChangeFrontAxle_ISi 3;
BA_ "GenSigMaxLatency" SG_ 2566850827 Trailer1LevelChangeFrontAxle_ISi 105;
BA_ "SystemSignalLongSymbol" SG_ 2566850827 Trailer1LevelChangeFrontAxle_ISi "Trailer1LevelChangeFrontAxle_ISig_3";
BA_ "GenSigCycleTime" SG_ 2566850827 Trailer3LevelChangeRearAxle_ISig 100;
BA_ "GenSigCycleTimeActive" SG_ 2566850827 Trailer3LevelChangeRearAxle_ISig 100;
BA_ "GenSigStartValue" SG_ 2566850827 Trailer3LevelChangeRearAxle_ISig 3;
BA_ "GenSigMaxLatency" SG_ 2566850827 Trailer3LevelChangeRearAxle_ISig 105;
BA_ "SystemSignalLongSymbol" SG_ 2566850827 Trailer3LevelChangeRearAxle_ISig "Trailer3LevelChangeRearAxle_ISig_3";
BA_ "GenSigCycleTime" SG_ 2566850827 Trailer5LevelChangeRearAxle_ISig 100;
BA_ "GenSigCycleTimeActive" SG_ 2566850827 Trailer5LevelChangeRearAxle_ISig 100;
BA_ "GenSigStartValue" SG_ 2566850827 Trailer5LevelChangeRearAxle_ISig 3;
BA_ "GenSigMaxLatency" SG_ 2566850827 Trailer5LevelChangeRearAxle_ISig 105;
BA_ "SystemSignalLongSymbol" SG_ 2566850827 Trailer5LevelChangeRearAxle_ISig "Trailer5LevelChangeRearAxle_ISig_3";
BA_ "GenSigCycleTime" SG_ 2566850827 Trailer2NormalLevelStorStat_ISig 100;
BA_ "GenSigCycleTimeActive" SG_ 2566850827 Trailer2NormalLevelStorStat_ISig 100;
BA_ "GenSigStartValue" SG_ 2566850827 Trailer2NormalLevelStorStat_ISig 3;
BA_ "GenSigMaxLatency" SG_ 2566850827 Trailer2NormalLevelStorStat_ISig 105;
BA_ "SystemSignalLongSymbol" SG_ 2566850827 Trailer2NormalLevelStorStat_ISig "Trailer2NormalLevelStorStat_ISig_3";
BA_ "GenSigCycleTime" SG_ 2566850827 Trailer4NormalLevelStorStat_ISig 100;
BA_ "GenSigCycleTimeActive" SG_ 2566850827 Trailer4NormalLevelStorStat_ISig 100;
BA_ "GenSigStartValue" SG_ 2566850827 Trailer4NormalLevelStorStat_ISig 3;
BA_ "GenSigMaxLatency" SG_ 2566850827 Trailer4NormalLevelStorStat_ISig 105;
BA_ "SystemSignalLongSymbol" SG_ 2566850827 Trailer4NormalLevelStorStat_ISig "Trailer4NormalLevelStorStat_ISig_3";
BA_ "GenSigCycleTime" SG_ 2566899211 Trailer4TowedVehStat_DetectStat 100;
BA_ "GenSigCycleTimeActive" SG_ 2566899211 Trailer4TowedVehStat_DetectStat 100;
BA_ "GenSigStartValue" SG_ 2566899211 Trailer4TowedVehStat_DetectStat 3;
BA_ "GenSigMaxLatency" SG_ 2566899211 Trailer4TowedVehStat_DetectStat 1240;
BA_ "GenSigCycleTime" SG_ 2566899211 Trailer5TowedVehStat_BrakeSystem 100;
BA_ "GenSigCycleTimeActive" SG_ 2566899211 Trailer5TowedVehStat_BrakeSystem 100;
BA_ "GenSigStartValue" SG_ 2566899211 Trailer5TowedVehStat_BrakeSystem 3;
BA_ "GenSigMaxLatency" SG_ 2566899211 Trailer5TowedVehStat_BrakeSystem 1250;
BA_ "GenSigCycleTime" SG_ 2566899211 Trailer2TowedVehStat_DetectSupp 100;
BA_ "GenSigCycleTimeActive" SG_ 2566899211 Trailer2TowedVehStat_DetectSupp 100;
BA_ "GenSigStartValue" SG_ 2566899211 Trailer2TowedVehStat_DetectSupp 3;
BA_ "GenSigMaxLatency" SG_ 2566899211 Trailer2TowedVehStat_DetectSupp 1220;
BA_ "GenSigCycleTime" SG_ 2566899211 Trailer1TowedVehStat_CANAvail 100;
BA_ "GenSigCycleTimeActive" SG_ 2566899211 Trailer1TowedVehStat_CANAvail 100;
BA_ "GenSigStartValue" SG_ 2566899211 Trailer1TowedVehStat_CANAvail 3;
BA_ "GenSigMaxLatency" SG_ 2566899211 Trailer1TowedVehStat_CANAvail 1210;
BA_ "GenSigCycleTime" SG_ 2566899211 Trailer2TowedVehStat_DetectStat 100;
BA_ "GenSigCycleTimeActive" SG_ 2566899211 Trailer2TowedVehStat_DetectStat 100;
BA_ "GenSigStartValue" SG_ 2566899211 Trailer2TowedVehStat_DetectStat 3;
BA_ "GenSigMaxLatency" SG_ 2566899211 Trailer2TowedVehStat_DetectStat 1220;
BA_ "GenSigCycleTime" SG_ 2566899211 Trailer2TowedVehStat_BrakeSystem 100;
BA_ "GenSigCycleTimeActive" SG_ 2566899211 Trailer2TowedVehStat_BrakeSystem 100;
BA_ "GenSigStartValue" SG_ 2566899211 Trailer2TowedVehStat_BrakeSystem 3;
BA_ "GenSigMaxLatency" SG_ 2566899211 Trailer2TowedVehStat_BrakeSystem 1220;
BA_ "GenSigCycleTime" SG_ 2566899211 Trailer2TowedVehStat_CANAvail 100;
BA_ "GenSigCycleTimeActive" SG_ 2566899211 Trailer2TowedVehStat_CANAvail 100;
BA_ "GenSigStartValue" SG_ 2566899211 Trailer2TowedVehStat_CANAvail 3;
BA_ "GenSigMaxLatency" SG_ 2566899211 Trailer2TowedVehStat_CANAvail 1220;
BA_ "GenSigCycleTime" SG_ 2566899211 Trailer3TowedVehStat_BrakeSystem 100;
BA_ "GenSigCycleTimeActive" SG_ 2566899211 Trailer3TowedVehStat_BrakeSystem 100;
BA_ "GenSigStartValue" SG_ 2566899211 Trailer3TowedVehStat_BrakeSystem 3;
BA_ "GenSigMaxLatency" SG_ 2566899211 Trailer3TowedVehStat_BrakeSystem 1230;
BA_ "GenSigCycleTime" SG_ 2566899211 Trailer3TowedVehStat_DetectStat 100;
BA_ "GenSigCycleTimeActive" SG_ 2566899211 Trailer3TowedVehStat_DetectStat 100;
BA_ "GenSigStartValue" SG_ 2566899211 Trailer3TowedVehStat_DetectStat 3;
BA_ "GenSigMaxLatency" SG_ 2566899211 Trailer3TowedVehStat_DetectStat 1230;
BA_ "GenSigCycleTime" SG_ 2566899211 Trailer5TowedVehStat_DetectSupp 100;
BA_ "GenSigCycleTimeActive" SG_ 2566899211 Trailer5TowedVehStat_DetectSupp 100;
BA_ "GenSigStartValue" SG_ 2566899211 Trailer5TowedVehStat_DetectSupp 3;
BA_ "GenSigMaxLatency" SG_ 2566899211 Trailer5TowedVehStat_DetectSupp 1250;
BA_ "GenSigCycleTime" SG_ 2566899211 Trailer4TowedVehStat_DetectSupp 100;
BA_ "GenSigCycleTimeActive" SG_ 2566899211 Trailer4TowedVehStat_DetectSupp 100;
BA_ "GenSigStartValue" SG_ 2566899211 Trailer4TowedVehStat_DetectSupp 3;
BA_ "GenSigMaxLatency" SG_ 2566899211 Trailer4TowedVehStat_DetectSupp 1240;
BA_ "GenSigCycleTime" SG_ 2566899211 Trailer5TowedVehStat_DetectStat 100;
BA_ "GenSigCycleTimeActive" SG_ 2566899211 Trailer5TowedVehStat_DetectStat 100;
BA_ "GenSigStartValue" SG_ 2566899211 Trailer5TowedVehStat_DetectStat 3;
BA_ "GenSigMaxLatency" SG_ 2566899211 Trailer5TowedVehStat_DetectStat 1250;
BA_ "GenSigCycleTime" SG_ 2566899211 Trailer3TowedVehStat_DetectSupp 100;
BA_ "GenSigCycleTimeActive" SG_ 2566899211 Trailer3TowedVehStat_DetectSupp 100;
BA_ "GenSigStartValue" SG_ 2566899211 Trailer3TowedVehStat_DetectSupp 3;
BA_ "GenSigMaxLatency" SG_ 2566899211 Trailer3TowedVehStat_DetectSupp 1230;
BA_ "GenSigCycleTime" SG_ 2566899211 Trailer1TowedVehStat_DetectSupp 100;
BA_ "GenSigCycleTimeActive" SG_ 2566899211 Trailer1TowedVehStat_DetectSupp 100;
BA_ "GenSigStartValue" SG_ 2566899211 Trailer1TowedVehStat_DetectSupp 3;
BA_ "GenSigMaxLatency" SG_ 2566899211 Trailer1TowedVehStat_DetectSupp 1210;
BA_ "GenSigCycleTime" SG_ 2566899211 Trailer4TowedVehStat_CANAvail 100;
BA_ "GenSigCycleTimeActive" SG_ 2566899211 Trailer4TowedVehStat_CANAvail 100;
BA_ "GenSigStartValue" SG_ 2566899211 Trailer4TowedVehStat_CANAvail 3;
BA_ "GenSigMaxLatency" SG_ 2566899211 Trailer4TowedVehStat_CANAvail 1240;
BA_ "GenSigCycleTime" SG_ 2566899211 Trailer1TowedVehStat_BrakeSystem 100;
BA_ "GenSigCycleTimeActive" SG_ 2566899211 Trailer1TowedVehStat_BrakeSystem 100;
BA_ "GenSigStartValue" SG_ 2566899211 Trailer1TowedVehStat_BrakeSystem 3;
BA_ "GenSigMaxLatency" SG_ 2566899211 Trailer1TowedVehStat_BrakeSystem 1210;
BA_ "GenSigCycleTime" SG_ 2566899211 Trailer5TowedVehStat_CANAvail 100;
BA_ "GenSigCycleTimeActive" SG_ 2566899211 Trailer5TowedVehStat_CANAvail 100;
BA_ "GenSigStartValue" SG_ 2566899211 Trailer5TowedVehStat_CANAvail 3;
BA_ "GenSigMaxLatency" SG_ 2566899211 Trailer5TowedVehStat_CANAvail 1250;
BA_ "GenSigCycleTime" SG_ 2566899211 Trailer4TowedVehStat_BrakeSystem 100;
BA_ "GenSigCycleTimeActive" SG_ 2566899211 Trailer4TowedVehStat_BrakeSystem 100;
BA_ "GenSigStartValue" SG_ 2566899211 Trailer4TowedVehStat_BrakeSystem 3;
BA_ "GenSigMaxLatency" SG_ 2566899211 Trailer4TowedVehStat_BrakeSystem 1240;
BA_ "GenSigCycleTime" SG_ 2566899211 Trailer1TowedVehStat_DetectStat 100;
BA_ "GenSigCycleTimeActive" SG_ 2566899211 Trailer1TowedVehStat_DetectStat 100;
BA_ "GenSigStartValue" SG_ 2566899211 Trailer1TowedVehStat_DetectStat 3;
BA_ "GenSigMaxLatency" SG_ 2566899211 Trailer1TowedVehStat_DetectStat 1210;
BA_ "GenSigCycleTime" SG_ 2566899211 Trailer3TowedVehStat_CANAvail 100;
BA_ "GenSigCycleTimeActive" SG_ 2566899211 Trailer3TowedVehStat_CANAvail 100;
BA_ "GenSigStartValue" SG_ 2566899211 Trailer3TowedVehStat_CANAvail 3;
BA_ "GenSigMaxLatency" SG_ 2566899211 Trailer3TowedVehStat_CANAvail 1230;
BA_ "GenSigCycleTime" SG_ 2566898955 Trailer5CalibInfo_ScaleLoad_ISig 100;
BA_ "GenSigCycleTimeActive" SG_ 2566898955 Trailer5CalibInfo_ScaleLoad_ISig 100;
BA_ "GenSigStartValue" SG_ 2566898955 Trailer5CalibInfo_ScaleLoad_ISig 65535;
BA_ "GenSigMaxLatency" SG_ 2566898955 Trailer5CalibInfo_ScaleLoad_ISig 1250;
BA_ "SystemSignalLongSymbol" SG_ 2566898955 Trailer5CalibInfo_ScaleLoad_ISig "Trailer5CalibInfo_ScaleLoad_ISig_3";
BA_ "GenSigCycleTime" SG_ 2566898955 Trailer5CalibInfo_DataStorage_IS 100;
BA_ "GenSigCycleTimeActive" SG_ 2566898955 Trailer5CalibInfo_DataStorage_IS 100;
BA_ "GenSigStartValue" SG_ 2566898955 Trailer5CalibInfo_DataStorage_IS 3;
BA_ "SystemSignalLongSymbol" SG_ 2566898955 Trailer5CalibInfo_DataStorage_IS "Trailer5CalibInfo_DataStorage_ISig_3";
BA_ "GenSigCycleTime" SG_ 2566898955 Trailer5CalibInfo_Year_ISig_3 100;
BA_ "GenSigCycleTimeActive" SG_ 2566898955 Trailer5CalibInfo_Year_ISig_3 100;
BA_ "GenSigStartValue" SG_ 2566898955 Trailer5CalibInfo_Year_ISig_3 255;
BA_ "GenSigMaxLatency" SG_ 2566898955 Trailer5CalibInfo_Year_ISig_3 1250;
BA_ "GenSigCycleTime" SG_ 2566898955 Trailer5CalibInfo_Month_ISig_3 100;
BA_ "GenSigCycleTimeActive" SG_ 2566898955 Trailer5CalibInfo_Month_ISig_3 100;
BA_ "GenSigStartValue" SG_ 2566898955 Trailer5CalibInfo_Month_ISig_3 255;
BA_ "GenSigMaxLatency" SG_ 2566898955 Trailer5CalibInfo_Month_ISig_3 1250;
BA_ "GenSigCycleTime" SG_ 2566898955 Trailer5CalibInfo_UncalibLoad_IS 100;
BA_ "GenSigCycleTimeActive" SG_ 2566898955 Trailer5CalibInfo_UncalibLoad_IS 100;
BA_ "GenSigStartValue" SG_ 2566898955 Trailer5CalibInfo_UncalibLoad_IS 65535;
BA_ "GenSigMaxLatency" SG_ 2566898955 Trailer5CalibInfo_UncalibLoad_IS 1250;
BA_ "SystemSignalLongSymbol" SG_ 2566898955 Trailer5CalibInfo_UncalibLoad_IS "Trailer5CalibInfo_UncalibLoad_ISig_3";
BA_ "GenSigCycleTime" SG_ 2566898955 Trailer5CalibInfo_CalibUsage_ISi 100;
BA_ "GenSigCycleTimeActive" SG_ 2566898955 Trailer5CalibInfo_CalibUsage_ISi 100;
BA_ "SystemSignalLongSymbol" SG_ 2566898955 Trailer5CalibInfo_CalibUsage_ISi "Trailer5CalibInfo_CalibUsage_ISig_3";
BA_ "GenSigCycleTime" SG_ 2566898955 Trailer5CalibInfo_AxleId_ISig_3 100;
BA_ "GenSigCycleTimeActive" SG_ 2566898955 Trailer5CalibInfo_AxleId_ISig_3 100;
BA_ "GenSigMaxLatency" SG_ 2566898955 Trailer5CalibInfo_AxleId_ISig_3 1250;
BA_ "GenSigCycleTime" SG_ 2566898955 Trailer5CalibInfo_LoadRange_ISig 100;
BA_ "GenSigCycleTimeActive" SG_ 2566898955 Trailer5CalibInfo_LoadRange_ISig 100;
BA_ "GenSigMaxLatency" SG_ 2566898955 Trailer5CalibInfo_LoadRange_ISig 1250;
BA_ "SystemSignalLongSymbol" SG_ 2566898955 Trailer5CalibInfo_LoadRange_ISig "Trailer5CalibInfo_LoadRange_ISig_3";
BA_ "GenSigCycleTime" SG_ 2566898699 Trailer4CalibInfo_Month_ISig_3 100;
BA_ "GenSigCycleTimeActive" SG_ 2566898699 Trailer4CalibInfo_Month_ISig_3 100;
BA_ "GenSigStartValue" SG_ 2566898699 Trailer4CalibInfo_Month_ISig_3 255;
BA_ "GenSigMaxLatency" SG_ 2566898699 Trailer4CalibInfo_Month_ISig_3 1240;
BA_ "GenSigCycleTime" SG_ 2566898699 Trailer4CalibInfo_DataStorage_IS 100;
BA_ "GenSigCycleTimeActive" SG_ 2566898699 Trailer4CalibInfo_DataStorage_IS 100;
BA_ "GenSigStartValue" SG_ 2566898699 Trailer4CalibInfo_DataStorage_IS 3;
BA_ "SystemSignalLongSymbol" SG_ 2566898699 Trailer4CalibInfo_DataStorage_IS "Trailer4CalibInfo_DataStorage_ISig_3";
BA_ "GenSigCycleTime" SG_ 2566898699 Trailer4CalibInfo_CalibUsage_ISi 100;
BA_ "GenSigCycleTimeActive" SG_ 2566898699 Trailer4CalibInfo_CalibUsage_ISi 100;
BA_ "SystemSignalLongSymbol" SG_ 2566898699 Trailer4CalibInfo_CalibUsage_ISi "Trailer4CalibInfo_CalibUsage_ISig_3";
BA_ "GenSigCycleTime" SG_ 2566898699 Trailer4CalibInfo_ScaleLoad_ISig 100;
BA_ "GenSigCycleTimeActive" SG_ 2566898699 Trailer4CalibInfo_ScaleLoad_ISig 100;
BA_ "GenSigStartValue" SG_ 2566898699 Trailer4CalibInfo_ScaleLoad_ISig 65535;
BA_ "GenSigMaxLatency" SG_ 2566898699 Trailer4CalibInfo_ScaleLoad_ISig 1240;
BA_ "SystemSignalLongSymbol" SG_ 2566898699 Trailer4CalibInfo_ScaleLoad_ISig "Trailer4CalibInfo_ScaleLoad_ISig_3";
BA_ "GenSigCycleTime" SG_ 2566898699 Trailer4CalibInfo_LoadRange_ISig 100;
BA_ "GenSigCycleTimeActive" SG_ 2566898699 Trailer4CalibInfo_LoadRange_ISig 100;
BA_ "GenSigMaxLatency" SG_ 2566898699 Trailer4CalibInfo_LoadRange_ISig 1240;
BA_ "SystemSignalLongSymbol" SG_ 2566898699 Trailer4CalibInfo_LoadRange_ISig "Trailer4CalibInfo_LoadRange_ISig_3";
BA_ "GenSigCycleTime" SG_ 2566898699 Trailer4CalibInfo_Year_ISig_3 100;
BA_ "GenSigCycleTimeActive" SG_ 2566898699 Trailer4CalibInfo_Year_ISig_3 100;
BA_ "GenSigStartValue" SG_ 2566898699 Trailer4CalibInfo_Year_ISig_3 255;
BA_ "GenSigMaxLatency" SG_ 2566898699 Trailer4CalibInfo_Year_ISig_3 1240;
BA_ "GenSigCycleTime" SG_ 2566898699 Trailer4CalibInfo_AxleId_ISig_3 100;
BA_ "GenSigCycleTimeActive" SG_ 2566898699 Trailer4CalibInfo_AxleId_ISig_3 100;
BA_ "GenSigMaxLatency" SG_ 2566898699 Trailer4CalibInfo_AxleId_ISig_3 1240;
BA_ "GenSigCycleTime" SG_ 2566898699 Trailer4CalibInfo_UncalibLoad_IS 100;
BA_ "GenSigCycleTimeActive" SG_ 2566898699 Trailer4CalibInfo_UncalibLoad_IS 100;
BA_ "GenSigStartValue" SG_ 2566898699 Trailer4CalibInfo_UncalibLoad_IS 65535;
BA_ "GenSigMaxLatency" SG_ 2566898699 Trailer4CalibInfo_UncalibLoad_IS 1240;
BA_ "SystemSignalLongSymbol" SG_ 2566898699 Trailer4CalibInfo_UncalibLoad_IS "Trailer4CalibInfo_UncalibLoad_ISig_3";
BA_ "GenSigCycleTime" SG_ 2566898443 Trailer3CalibInfo_ScaleLoad_ISig 100;
BA_ "GenSigCycleTimeActive" SG_ 2566898443 Trailer3CalibInfo_ScaleLoad_ISig 100;
BA_ "GenSigStartValue" SG_ 2566898443 Trailer3CalibInfo_ScaleLoad_ISig 65535;
BA_ "GenSigMaxLatency" SG_ 2566898443 Trailer3CalibInfo_ScaleLoad_ISig 1230;
BA_ "SystemSignalLongSymbol" SG_ 2566898443 Trailer3CalibInfo_ScaleLoad_ISig "Trailer3CalibInfo_ScaleLoad_ISig_3";
BA_ "GenSigCycleTime" SG_ 2566898443 Trailer3CalibInfo_Month_ISig_3 100;
BA_ "GenSigCycleTimeActive" SG_ 2566898443 Trailer3CalibInfo_Month_ISig_3 100;
BA_ "GenSigStartValue" SG_ 2566898443 Trailer3CalibInfo_Month_ISig_3 255;
BA_ "GenSigMaxLatency" SG_ 2566898443 Trailer3CalibInfo_Month_ISig_3 1230;
BA_ "GenSigCycleTime" SG_ 2566898443 Trailer3CalibInfo_AxleId_ISig_3 100;
BA_ "GenSigCycleTimeActive" SG_ 2566898443 Trailer3CalibInfo_AxleId_ISig_3 100;
BA_ "GenSigMaxLatency" SG_ 2566898443 Trailer3CalibInfo_AxleId_ISig_3 1230;
BA_ "GenSigCycleTime" SG_ 2566898443 Trailer3CalibInfo_UncalibLoad_IS 100;
BA_ "GenSigCycleTimeActive" SG_ 2566898443 Trailer3CalibInfo_UncalibLoad_IS 100;
BA_ "GenSigStartValue" SG_ 2566898443 Trailer3CalibInfo_UncalibLoad_IS 65535;
BA_ "GenSigMaxLatency" SG_ 2566898443 Trailer3CalibInfo_UncalibLoad_IS 1230;
BA_ "SystemSignalLongSymbol" SG_ 2566898443 Trailer3CalibInfo_UncalibLoad_IS "Trailer3CalibInfo_UncalibLoad_ISig_3";
BA_ "GenSigCycleTime" SG_ 2566898443 Trailer3CalibInfo_CalibUsage_ISi 100;
BA_ "GenSigCycleTimeActive" SG_ 2566898443 Trailer3CalibInfo_CalibUsage_ISi 100;
BA_ "SystemSignalLongSymbol" SG_ 2566898443 Trailer3CalibInfo_CalibUsage_ISi "Trailer3CalibInfo_CalibUsage_ISig_3";
BA_ "GenSigCycleTime" SG_ 2566898443 Trailer3CalibInfo_LoadRange_ISig 100;
BA_ "GenSigCycleTimeActive" SG_ 2566898443 Trailer3CalibInfo_LoadRange_ISig 100;
BA_ "GenSigMaxLatency" SG_ 2566898443 Trailer3CalibInfo_LoadRange_ISig 1230;
BA_ "SystemSignalLongSymbol" SG_ 2566898443 Trailer3CalibInfo_LoadRange_ISig "Trailer3CalibInfo_LoadRange_ISig_3";
BA_ "GenSigCycleTime" SG_ 2566898443 Trailer3CalibInfo_DataStorage_IS 100;
BA_ "GenSigCycleTimeActive" SG_ 2566898443 Trailer3CalibInfo_DataStorage_IS 100;
BA_ "GenSigStartValue" SG_ 2566898443 Trailer3CalibInfo_DataStorage_IS 3;
BA_ "SystemSignalLongSymbol" SG_ 2566898443 Trailer3CalibInfo_DataStorage_IS "Trailer3CalibInfo_DataStorage_ISig_3";
BA_ "GenSigCycleTime" SG_ 2566898443 Trailer3CalibInfo_Year_ISig_3 100;
BA_ "GenSigCycleTimeActive" SG_ 2566898443 Trailer3CalibInfo_Year_ISig_3 100;
BA_ "GenSigStartValue" SG_ 2566898443 Trailer3CalibInfo_Year_ISig_3 255;
BA_ "GenSigMaxLatency" SG_ 2566898443 Trailer3CalibInfo_Year_ISig_3 1230;
BA_REL_ "GenSigFirstTimeoutTime" BU_SG_REL_ IC3 SG_ 2566906891 Trailer4PneumSupply_Pressure_ISi 24000;
BA_REL_ "GenSigTimeoutTime" BU_SG_REL_ IC3 SG_ 2566906891 Trailer4PneumSupply_Pressure_ISi 6000;
BA_REL_ "GenSigFirstTimeoutTime" BU_SG_REL_ IC3 SG_ 2566906891 Trailer4VehicleType_ISig_3 24000;
BA_REL_ "GenSigTimeoutTime" BU_SG_REL_ IC3 SG_ 2566906891 Trailer4VehicleType_ISig_3 6000;
BA_REL_ "GenSigFirstTimeoutTime" BU_SG_REL_ IC3 SG_ 2566906891 Trailer4NomBodyLevel_FrontLevel_ 24000;
BA_REL_ "GenSigTimeoutTime" BU_SG_REL_ IC3 SG_ 2566906891 Trailer4NomBodyLevel_FrontLevel_ 6000;
BA_REL_ "GenSigFirstTimeoutTime" BU_SG_REL_ IC3 SG_ 2566906891 Trailer4YCSystemStatus_ISig_3 24000;
BA_REL_ "GenSigTimeoutTime" BU_SG_REL_ IC3 SG_ 2566906891 Trailer4YCSystemStatus_ISig_3 6000;
BA_REL_ "GenSigFirstTimeoutTime" BU_SG_REL_ IC3 SG_ 2566906891 Trailer4EBSAmberWarning_ISig_3 24000;
BA_REL_ "GenSigTimeoutTime" BU_SG_REL_ IC3 SG_ 2566906891 Trailer4EBSAmberWarning_ISig_3 6000;
BA_REL_ "GenSigFirstTimeoutTime" BU_SG_REL_ IC3 SG_ 2566906891 Trailer4LevelControlStatus_ISig_ 24000;
BA_REL_ "GenSigTimeoutTime" BU_SG_REL_ IC3 SG_ 2566906891 Trailer4LevelControlStatus_ISig_ 6000;
BA_REL_ "GenSigFirstTimeoutTime" BU_SG_REL_ IC3 SG_ 2566906891 Trailer4NomBodyLevel_RearLevel_I 24000;
BA_REL_ "GenSigTimeoutTime" BU_SG_REL_ IC3 SG_ 2566906891 Trailer4NomBodyLevel_RearLevel_I 6000;
BA_REL_ "GenSigFirstTimeoutTime" BU_SG_REL_ IC3 SG_ 2566906891 Trailer4ROPSystemStatus_ISig_3 24000;
BA_REL_ "GenSigTimeoutTime" BU_SG_REL_ IC3 SG_ 2566906891 Trailer4ROPSystemStatus_ISig_3 6000;
BA_REL_ "GenSigFirstTimeoutTime" BU_SG_REL_ IC3 SG_ 2566906891 Trailer4LoadRampApprAssistStat_I 24000;
BA_REL_ "GenSigTimeoutTime" BU_SG_REL_ IC3 SG_ 2566906891 Trailer4LoadRampApprAssistStat_I 6000;
BA_REL_ "GenSigFirstTimeoutTime" BU_SG_REL_ IC3 SG_ 2566906891 Trailer4ExtLvlStorageSupport_ISi 24000;
BA_REL_ "GenSigTimeoutTime" BU_SG_REL_ IC3 SG_ 2566906891 Trailer4ExtLvlStorageSupport_ISi 6000;
BA_REL_ "GenSigFirstTimeoutTime" BU_SG_REL_ IC3 SG_ 2566906891 Trailer4PneumSupply_Status_ISig_ 24000;
BA_REL_ "GenSigTimeoutTime" BU_SG_REL_ IC3 SG_ 2566906891 Trailer4PneumSupply_Status_ISig_ 6000;
BA_REL_ "GenSigFirstTimeoutTime" BU_SG_REL_ IC3 SG_ 2566906891 Trailer4EBSRedWarning_ISig_3 24000;
BA_REL_ "GenSigTimeoutTime" BU_SG_REL_ IC3 SG_ 2566906891 Trailer4EBSRedWarning_ISig_3 6000;
BA_REL_ "GenSigFirstTimeoutTime" BU_SG_REL_ IC3 SG_ 2566906891 Trailer4ElectricalSupplyStat_ISi 24000;
BA_REL_ "GenSigTimeoutTime" BU_SG_REL_ IC3 SG_ 2566906891 Trailer4ElectricalSupplyStat_ISi 6000;
BA_REL_ "GenSigFirstTimeoutTime" BU_SG_REL_ IC3 SG_ 2566902283 Trailer3YCSystemStatus_ISig_3 24000;
BA_REL_ "GenSigTimeoutTime" BU_SG_REL_ IC3 SG_ 2566902283 Trailer3YCSystemStatus_ISig_3 6000;
BA_REL_ "GenSigFirstTimeoutTime" BU_SG_REL_ IC3 SG_ 2566902283 Trailer3EBSAmberWarning_ISig_3 24000;
BA_REL_ "GenSigTimeoutTime" BU_SG_REL_ IC3 SG_ 2566902283 Trailer3EBSAmberWarning_ISig_3 6000;
BA_REL_ "GenSigFirstTimeoutTime" BU_SG_REL_ IC3 SG_ 2566902283 Trailer3NomBodyLevel_RearLevel_I 24000;
BA_REL_ "GenSigTimeoutTime" BU_SG_REL_ IC3 SG_ 2566902283 Trailer3NomBodyLevel_RearLevel_I 6000;
BA_REL_ "GenSigFirstTimeoutTime" BU_SG_REL_ IC3 SG_ 2566902283 Trailer3EBSRedWarning_ISig_3 24000;
BA_REL_ "GenSigTimeoutTime" BU_SG_REL_ IC3 SG_ 2566902283 Trailer3EBSRedWarning_ISig_3 6000;
BA_REL_ "GenSigFirstTimeoutTime" BU_SG_REL_ IC3 SG_ 2566902283 Trailer3PneumSupply_Status_ISig_ 24000;
BA_REL_ "GenSigTimeoutTime" BU_SG_REL_ IC3 SG_ 2566902283 Trailer3PneumSupply_Status_ISig_ 6000;
BA_REL_ "GenSigFirstTimeoutTime" BU_SG_REL_ IC3 SG_ 2566902283 Trailer3PneumSupply_Pressure_ISi 24000;
BA_REL_ "GenSigTimeoutTime" BU_SG_REL_ IC3 SG_ 2566902283 Trailer3PneumSupply_Pressure_ISi 6000;
BA_REL_ "GenSigFirstTimeoutTime" BU_SG_REL_ IC3 SG_ 2566902283 Trailer3LoadRampApprAssistStat_I 24000;
BA_REL_ "GenSigTimeoutTime" BU_SG_REL_ IC3 SG_ 2566902283 Trailer3LoadRampApprAssistStat_I 6000;
BA_REL_ "GenSigFirstTimeoutTime" BU_SG_REL_ IC3 SG_ 2566902283 Trailer3ROPSystemStatus_ISig_3 24000;
BA_REL_ "GenSigTimeoutTime" BU_SG_REL_ IC3 SG_ 2566902283 Trailer3ROPSystemStatus_ISig_3 6000;
BA_REL_ "GenSigFirstTimeoutTime" BU_SG_REL_ IC3 SG_ 2566902283 Trailer3ElectricalSupplyStat_ISi 24000;
BA_REL_ "GenSigTimeoutTime" BU_SG_REL_ IC3 SG_ 2566902283 Trailer3ElectricalSupplyStat_ISi 6000;
BA_REL_ "GenSigFirstTimeoutTime" BU_SG_REL_ IC3 SG_ 2566902283 Trailer3NomBodyLevel_FrontLevel_ 24000;
BA_REL_ "GenSigTimeoutTime" BU_SG_REL_ IC3 SG_ 2566902283 Trailer3NomBodyLevel_FrontLevel_ 6000;
BA_REL_ "GenSigFirstTimeoutTime" BU_SG_REL_ IC3 SG_ 2566902283 Trailer3LevelControlStatus_ISig_ 24000;
BA_REL_ "GenSigTimeoutTime" BU_SG_REL_ IC3 SG_ 2566902283 Trailer3LevelControlStatus_ISig_ 6000;
BA_REL_ "GenSigFirstTimeoutTime" BU_SG_REL_ IC3 SG_ 2566902283 Trailer3VehicleType_ISig_3 24000;
BA_REL_ "GenSigTimeoutTime" BU_SG_REL_ IC3 SG_ 2566902283 Trailer3VehicleType_ISig_3 6000;
BA_REL_ "GenSigFirstTimeoutTime" BU_SG_REL_ IC3 SG_ 2566902283 Trailer3ExtLvlStorageSupport_ISi 24000;
BA_REL_ "GenSigTimeoutTime" BU_SG_REL_ IC3 SG_ 2566902283 Trailer3ExtLvlStorageSupport_ISi 6000;
BA_REL_ "GenSigFirstTimeoutTime" BU_SG_REL_ IC3 SG_ 2566897419 Trailer2VehicleType_ISig_3 24000;
BA_REL_ "GenSigTimeoutTime" BU_SG_REL_ IC3 SG_ 2566897419 Trailer2VehicleType_ISig_3 6000;
BA_REL_ "GenSigFirstTimeoutTime" BU_SG_REL_ IC3 SG_ 2566897419 Trailer2NomBodyLevel_RearLevel_I 24000;
BA_REL_ "GenSigTimeoutTime" BU_SG_REL_ IC3 SG_ 2566897419 Trailer2NomBodyLevel_RearLevel_I 6000;
BA_REL_ "GenSigFirstTimeoutTime" BU_SG_REL_ IC3 SG_ 2566897419 Trailer2EBSAmberWarning_ISig_3 24000;
BA_REL_ "GenSigTimeoutTime" BU_SG_REL_ IC3 SG_ 2566897419 Trailer2EBSAmberWarning_ISig_3 6000;
BA_REL_ "GenSigFirstTimeoutTime" BU_SG_REL_ IC3 SG_ 2566897419 Trailer2YCSystemStatus_ISig_3 24000;
BA_REL_ "GenSigTimeoutTime" BU_SG_REL_ IC3 SG_ 2566897419 Trailer2YCSystemStatus_ISig_3 6000;
BA_REL_ "GenSigFirstTimeoutTime" BU_SG_REL_ IC3 SG_ 2566897419 Trailer2ExtLvlStorageSupport_ISi 24000;
BA_REL_ "GenSigTimeoutTime" BU_SG_REL_ IC3 SG_ 2566897419 Trailer2ExtLvlStorageSupport_ISi 6000;
BA_REL_ "GenSigFirstTimeoutTime" BU_SG_REL_ IC3 SG_ 2566897419 Trailer2ROPSystemStatus_ISig_3 24000;
BA_REL_ "GenSigTimeoutTime" BU_SG_REL_ IC3 SG_ 2566897419 Trailer2ROPSystemStatus_ISig_3 6000;
BA_REL_ "GenSigFirstTimeoutTime" BU_SG_REL_ IC3 SG_ 2566897419 Trailer2PneumSupply_Status_ISig_ 24000;
BA_REL_ "GenSigTimeoutTime" BU_SG_REL_ IC3 SG_ 2566897419 Trailer2PneumSupply_Status_ISig_ 6000;
BA_REL_ "GenSigFirstTimeoutTime" BU_SG_REL_ IC3 SG_ 2566897419 Trailer2ElectricalSupplyStat_ISi 24000;
BA_REL_ "GenSigTimeoutTime" BU_SG_REL_ IC3 SG_ 2566897419 Trailer2ElectricalSupplyStat_ISi 6000;
BA_REL_ "GenSigFirstTimeoutTime" BU_SG_REL_ IC3 SG_ 2566897419 Trailer2LevelControlStatus_ISig_ 24000;
BA_REL_ "GenSigTimeoutTime" BU_SG_REL_ IC3 SG_ 2566897419 Trailer2LevelControlStatus_ISig_ 6000;
BA_REL_ "GenSigFirstTimeoutTime" BU_SG_REL_ IC3 SG_ 2566897419 Trailer2PneumSupply_Pressure_ISi 24000;
BA_REL_ "GenSigTimeoutTime" BU_SG_REL_ IC3 SG_ 2566897419 Trailer2PneumSupply_Pressure_ISi 6000;
BA_REL_ "GenSigFirstTimeoutTime" BU_SG_REL_ IC3 SG_ 2566897419 Trailer2NomBodyLevel_FrontLevel_ 24000;
BA_REL_ "GenSigTimeoutTime" BU_SG_REL_ IC3 SG_ 2566897419 Trailer2NomBodyLevel_FrontLevel_ 6000;
BA_REL_ "GenSigFirstTimeoutTime" BU_SG_REL_ IC3 SG_ 2566897419 Trailer2LoadRampApprAssistStat_I 24000;
BA_REL_ "GenSigTimeoutTime" BU_SG_REL_ IC3 SG_ 2566897419 Trailer2LoadRampApprAssistStat_I 6000;
BA_REL_ "GenSigFirstTimeoutTime" BU_SG_REL_ IC3 SG_ 2566897419 Trailer2EBSRedWarning_ISig_3 24000;
BA_REL_ "GenSigTimeoutTime" BU_SG_REL_ IC3 SG_ 2566897419 Trailer2EBSRedWarning_ISig_3 6000;
BA_REL_ "GenSigFirstTimeoutTime" BU_SG_REL_ IC3 SG_ 2566892811 Trailer1LoadRampApprAssistStat_I 24000;
BA_REL_ "GenSigTimeoutTime" BU_SG_REL_ IC3 SG_ 2566892811 Trailer1LoadRampApprAssistStat_I 6000;
BA_REL_ "GenSigFirstTimeoutTime" BU_SG_REL_ IC3 SG_ 2566892811 Trailer1NomBodyLevel_RearLevel_I 24000;
BA_REL_ "GenSigTimeoutTime" BU_SG_REL_ IC3 SG_ 2566892811 Trailer1NomBodyLevel_RearLevel_I 6000;
BA_REL_ "GenSigFirstTimeoutTime" BU_SG_REL_ IC3 SG_ 2566892811 Trailer1NomBodyLevel_FrontLevel_ 24000;
BA_REL_ "GenSigTimeoutTime" BU_SG_REL_ IC3 SG_ 2566892811 Trailer1NomBodyLevel_FrontLevel_ 6000;
BA_REL_ "GenSigFirstTimeoutTime" BU_SG_REL_ IC3 SG_ 2566892811 Trailer1VehicleType_ISig_3 24000;
BA_REL_ "GenSigTimeoutTime" BU_SG_REL_ IC3 SG_ 2566892811 Trailer1VehicleType_ISig_3 6000;
BA_REL_ "GenSigFirstTimeoutTime" BU_SG_REL_ IC3 SG_ 2566892811 Trailer1EBSRedWarning_ISig_3 24000;
BA_REL_ "GenSigTimeoutTime" BU_SG_REL_ IC3 SG_ 2566892811 Trailer1EBSRedWarning_ISig_3 6000;
BA_REL_ "GenSigFirstTimeoutTime" BU_SG_REL_ IC3 SG_ 2566892811 Trailer1PneumSupply_Pressure_ISi 24000;
BA_REL_ "GenSigTimeoutTime" BU_SG_REL_ IC3 SG_ 2566892811 Trailer1PneumSupply_Pressure_ISi 6000;
BA_REL_ "GenSigFirstTimeoutTime" BU_SG_REL_ IC3 SG_ 2566892811 Trailer1LevelControlStatus_ISig_ 24000;
BA_REL_ "GenSigTimeoutTime" BU_SG_REL_ IC3 SG_ 2566892811 Trailer1LevelControlStatus_ISig_ 6000;
BA_REL_ "GenSigFirstTimeoutTime" BU_SG_REL_ IC3 SG_ 2566892811 Trailer1ElectricalSupplyStat_ISi 24000;
BA_REL_ "GenSigTimeoutTime" BU_SG_REL_ IC3 SG_ 2566892811 Trailer1ElectricalSupplyStat_ISi 6000;
BA_REL_ "GenSigFirstTimeoutTime" BU_SG_REL_ IC3 SG_ 2566892811 Trailer1PneumSupply_Status_ISig_ 24000;
BA_REL_ "GenSigTimeoutTime" BU_SG_REL_ IC3 SG_ 2566892811 Trailer1PneumSupply_Status_ISig_ 6000;
BA_REL_ "GenSigFirstTimeoutTime" BU_SG_REL_ IC3 SG_ 2566892811 Trailer1ROPSystemStatus_ISig_3 24000;
BA_REL_ "GenSigTimeoutTime" BU_SG_REL_ IC3 SG_ 2566892811 Trailer1ROPSystemStatus_ISig_3 6000;
BA_REL_ "GenSigFirstTimeoutTime" BU_SG_REL_ IC3 SG_ 2566892811 Trailer1YCSystemStatus_ISig_3 24000;
BA_REL_ "GenSigTimeoutTime" BU_SG_REL_ IC3 SG_ 2566892811 Trailer1YCSystemStatus_ISig_3 6000;
BA_REL_ "GenSigFirstTimeoutTime" BU_SG_REL_ IC3 SG_ 2566892811 Trailer1ExtLvlStorageSupport_ISi 24000;
BA_REL_ "GenSigTimeoutTime" BU_SG_REL_ IC3 SG_ 2566892811 Trailer1ExtLvlStorageSupport_ISi 6000;
BA_REL_ "GenSigFirstTimeoutTime" BU_SG_REL_ IC3 SG_ 2566892811 Trailer1EBSAmberWarning_ISig_3 24000;
BA_REL_ "GenSigTimeoutTime" BU_SG_REL_ IC3 SG_ 2566892811 Trailer1EBSAmberWarning_ISig_3 6000;
BA_REL_ "GenSigFirstTimeoutTime" BU_SG_REL_ IC3 SG_ 2566887947 Trailer5TireInfoISO_Pressure_ISi 24000;
BA_REL_ "GenSigTimeoutTime" BU_SG_REL_ IC3 SG_ 2566887947 Trailer5TireInfoISO_Pressure_ISi 6000;
BA_REL_ "GenSigFirstTimeoutTime" BU_SG_REL_ IC3 SG_ 2566887947 Trailer5TireInfoISO_Active_ISig_ 24000;
BA_REL_ "GenSigTimeoutTime" BU_SG_REL_ IC3 SG_ 2566887947 Trailer5TireInfoISO_Active_ISig_ 6000;
BA_REL_ "GenSigFirstTimeoutTime" BU_SG_REL_ IC3 SG_ 2566887947 Trailer5TireInfoISO_PowerSupply_ 24000;
BA_REL_ "GenSigTimeoutTime" BU_SG_REL_ IC3 SG_ 2566887947 Trailer5TireInfoISO_PowerSupply_ 6000;
BA_REL_ "GenSigFirstTimeoutTime" BU_SG_REL_ IC3 SG_ 2566887947 Trailer5TireInfoISO_Leakage_ISig 24000;
BA_REL_ "GenSigTimeoutTime" BU_SG_REL_ IC3 SG_ 2566887947 Trailer5TireInfoISO_Leakage_ISig 6000;
BA_REL_ "GenSigFirstTimeoutTime" BU_SG_REL_ IC3 SG_ 2566887947 Trailer5TireInfoISO_TireId_ISig_ 24000;
BA_REL_ "GenSigTimeoutTime" BU_SG_REL_ IC3 SG_ 2566887947 Trailer5TireInfoISO_TireId_ISig_ 6000;
BA_REL_ "GenSigFirstTimeoutTime" BU_SG_REL_ IC3 SG_ 2566887947 Trailer5TireInfoISO_Temperature_ 24000;
BA_REL_ "GenSigTimeoutTime" BU_SG_REL_ IC3 SG_ 2566887947 Trailer5TireInfoISO_Temperature_ 6000;
BA_REL_ "GenSigFirstTimeoutTime" BU_SG_REL_ IC3 SG_ 2566887947 Trailer5TireInfoISO_Warning_ISig 24000;
BA_REL_ "GenSigTimeoutTime" BU_SG_REL_ IC3 SG_ 2566887947 Trailer5TireInfoISO_Warning_ISig 6000;
BA_REL_ "GenSigFirstTimeoutTime" BU_SG_REL_ IC3 SG_ 2566887947 Trailer5TireInfoISO_PresSuff_ISi 24000;
BA_REL_ "GenSigTimeoutTime" BU_SG_REL_ IC3 SG_ 2566887947 Trailer5TireInfoISO_PresSuff_ISi 6000;
BA_REL_ "GenSigFirstTimeoutTime" BU_SG_REL_ IC3 SG_ 2566887947 Trailer5TireInfoISO_sg_UB_ISig_3 24000;
BA_REL_ "GenSigTimeoutTime" BU_SG_REL_ IC3 SG_ 2566887947 Trailer5TireInfoISO_sg_UB_ISig_3 6000;
BA_REL_ "GenSigFirstTimeoutTime" BU_SG_REL_ IC3 SG_ 2566883339 Trailer4TireInfoISO_sg_UB_ISig_3 24000;
BA_REL_ "GenSigTimeoutTime" BU_SG_REL_ IC3 SG_ 2566883339 Trailer4TireInfoISO_sg_UB_ISig_3 6000;
BA_REL_ "GenSigFirstTimeoutTime" BU_SG_REL_ IC3 SG_ 2566883339 Trailer4TireInfoISO_PresSuff_ISi 24000;
BA_REL_ "GenSigTimeoutTime" BU_SG_REL_ IC3 SG_ 2566883339 Trailer4TireInfoISO_PresSuff_ISi 6000;
BA_REL_ "GenSigFirstTimeoutTime" BU_SG_REL_ IC3 SG_ 2566883339 Trailer4TireInfoISO_Pressure_ISi 24000;
BA_REL_ "GenSigTimeoutTime" BU_SG_REL_ IC3 SG_ 2566883339 Trailer4TireInfoISO_Pressure_ISi 6000;
BA_REL_ "GenSigFirstTimeoutTime" BU_SG_REL_ IC3 SG_ 2566883339 Trailer4TireInfoISO_Leakage_ISig 24000;
BA_REL_ "GenSigTimeoutTime" BU_SG_REL_ IC3 SG_ 2566883339 Trailer4TireInfoISO_Leakage_ISig 6000;
BA_REL_ "GenSigFirstTimeoutTime" BU_SG_REL_ IC3 SG_ 2566883339 Trailer4TireInfoISO_TireId_ISig_ 24000;
BA_REL_ "GenSigTimeoutTime" BU_SG_REL_ IC3 SG_ 2566883339 Trailer4TireInfoISO_TireId_ISig_ 6000;
BA_REL_ "GenSigFirstTimeoutTime" BU_SG_REL_ IC3 SG_ 2566883339 Trailer4TireInfoISO_Active_ISig_ 24000;
BA_REL_ "GenSigTimeoutTime" BU_SG_REL_ IC3 SG_ 2566883339 Trailer4TireInfoISO_Active_ISig_ 6000;
BA_REL_ "GenSigFirstTimeoutTime" BU_SG_REL_ IC3 SG_ 2566883339 Trailer4TireInfoISO_PowerSupply_ 24000;
BA_REL_ "GenSigTimeoutTime" BU_SG_REL_ IC3 SG_ 2566883339 Trailer4TireInfoISO_PowerSupply_ 6000;
BA_REL_ "GenSigFirstTimeoutTime" BU_SG_REL_ IC3 SG_ 2566883339 Trailer4TireInfoISO_Temperature_ 24000;
BA_REL_ "GenSigTimeoutTime" BU_SG_REL_ IC3 SG_ 2566883339 Trailer4TireInfoISO_Temperature_ 6000;
BA_REL_ "GenSigFirstTimeoutTime" BU_SG_REL_ IC3 SG_ 2566883339 Trailer4TireInfoISO_Warning_ISig 24000;
BA_REL_ "GenSigTimeoutTime" BU_SG_REL_ IC3 SG_ 2566883339 Trailer4TireInfoISO_Warning_ISig 6000;
BA_REL_ "GenSigFirstTimeoutTime" BU_SG_REL_ IC3 SG_ 2566878731 Trailer3TireInfoISO_Warning_ISig 24000;
BA_REL_ "GenSigTimeoutTime" BU_SG_REL_ IC3 SG_ 2566878731 Trailer3TireInfoISO_Warning_ISig 6000;
BA_REL_ "GenSigFirstTimeoutTime" BU_SG_REL_ IC3 SG_ 2566878731 Trailer3TireInfoISO_TireId_ISig_ 24000;
BA_REL_ "GenSigTimeoutTime" BU_SG_REL_ IC3 SG_ 2566878731 Trailer3TireInfoISO_TireId_ISig_ 6000;
BA_REL_ "GenSigFirstTimeoutTime" BU_SG_REL_ IC3 SG_ 2566878731 Trailer3TireInfoISO_Active_ISig_ 24000;
BA_REL_ "GenSigTimeoutTime" BU_SG_REL_ IC3 SG_ 2566878731 Trailer3TireInfoISO_Active_ISig_ 6000;
BA_REL_ "GenSigFirstTimeoutTime" BU_SG_REL_ IC3 SG_ 2566878731 Trailer3TireInfoISO_sg_UB_ISig_3 24000;
BA_REL_ "GenSigTimeoutTime" BU_SG_REL_ IC3 SG_ 2566878731 Trailer3TireInfoISO_sg_UB_ISig_3 6000;
BA_REL_ "GenSigFirstTimeoutTime" BU_SG_REL_ IC3 SG_ 2566878731 Trailer3TireInfoISO_Leakage_ISig 24000;
BA_REL_ "GenSigTimeoutTime" BU_SG_REL_ IC3 SG_ 2566878731 Trailer3TireInfoISO_Leakage_ISig 6000;
BA_REL_ "GenSigFirstTimeoutTime" BU_SG_REL_ IC3 SG_ 2566878731 Trailer3TireInfoISO_Pressure_ISi 24000;
BA_REL_ "GenSigTimeoutTime" BU_SG_REL_ IC3 SG_ 2566878731 Trailer3TireInfoISO_Pressure_ISi 6000;
BA_REL_ "GenSigFirstTimeoutTime" BU_SG_REL_ IC3 SG_ 2566878731 Trailer3TireInfoISO_PowerSupply_ 24000;
BA_REL_ "GenSigTimeoutTime" BU_SG_REL_ IC3 SG_ 2566878731 Trailer3TireInfoISO_PowerSupply_ 6000;
BA_REL_ "GenSigFirstTimeoutTime" BU_SG_REL_ IC3 SG_ 2566878731 Trailer3TireInfoISO_PresSuff_ISi 24000;
BA_REL_ "GenSigTimeoutTime" BU_SG_REL_ IC3 SG_ 2566878731 Trailer3TireInfoISO_PresSuff_ISi 6000;
BA_REL_ "GenSigFirstTimeoutTime" BU_SG_REL_ IC3 SG_ 2566878731 Trailer3TireInfoISO_Temperature_ 24000;
BA_REL_ "GenSigTimeoutTime" BU_SG_REL_ IC3 SG_ 2566878731 Trailer3TireInfoISO_Temperature_ 6000;
BA_REL_ "GenSigFirstTimeoutTime" BU_SG_REL_ IC3 SG_ 2566874123 Trailer2TireInfoISO_PowerSupply_ 24000;
BA_REL_ "GenSigTimeoutTime" BU_SG_REL_ IC3 SG_ 2566874123 Trailer2TireInfoISO_PowerSupply_ 6000;
BA_REL_ "GenSigFirstTimeoutTime" BU_SG_REL_ IC3 SG_ 2566874123 Trailer2TireInfoISO_Leakage_ISig 24000;
BA_REL_ "GenSigTimeoutTime" BU_SG_REL_ IC3 SG_ 2566874123 Trailer2TireInfoISO_Leakage_ISig 6000;
BA_REL_ "GenSigFirstTimeoutTime" BU_SG_REL_ IC3 SG_ 2566874123 Trailer2TireInfoISO_Active_ISig_ 24000;
BA_REL_ "GenSigTimeoutTime" BU_SG_REL_ IC3 SG_ 2566874123 Trailer2TireInfoISO_Active_ISig_ 6000;
BA_REL_ "GenSigFirstTimeoutTime" BU_SG_REL_ IC3 SG_ 2566874123 Trailer2TireInfoISO_PresSuff_ISi 24000;
BA_REL_ "GenSigTimeoutTime" BU_SG_REL_ IC3 SG_ 2566874123 Trailer2TireInfoISO_PresSuff_ISi 6000;
BA_REL_ "GenSigFirstTimeoutTime" BU_SG_REL_ IC3 SG_ 2566874123 Trailer2TireInfoISO_Temperature_ 24000;
BA_REL_ "GenSigTimeoutTime" BU_SG_REL_ IC3 SG_ 2566874123 Trailer2TireInfoISO_Temperature_ 6000;
BA_REL_ "GenSigFirstTimeoutTime" BU_SG_REL_ IC3 SG_ 2566874123 Trailer2TireInfoISO_Pressure_ISi 24000;
BA_REL_ "GenSigTimeoutTime" BU_SG_REL_ IC3 SG_ 2566874123 Trailer2TireInfoISO_Pressure_ISi 6000;
BA_REL_ "GenSigFirstTimeoutTime" BU_SG_REL_ IC3 SG_ 2566874123 Trailer2TireInfoISO_Warning_ISig 24000;
BA_REL_ "GenSigTimeoutTime" BU_SG_REL_ IC3 SG_ 2566874123 Trailer2TireInfoISO_Warning_ISig 6000;
BA_REL_ "GenSigFirstTimeoutTime" BU_SG_REL_ IC3 SG_ 2566874123 Trailer2TireInfoISO_sg_UB_ISig_3 24000;
BA_REL_ "GenSigTimeoutTime" BU_SG_REL_ IC3 SG_ 2566874123 Trailer2TireInfoISO_sg_UB_ISig_3 6000;
BA_REL_ "GenSigFirstTimeoutTime" BU_SG_REL_ IC3 SG_ 2566874123 Trailer2TireInfoISO_TireId_ISig_ 24000;
BA_REL_ "GenSigTimeoutTime" BU_SG_REL_ IC3 SG_ 2566874123 Trailer2TireInfoISO_TireId_ISig_ 6000;
BA_REL_ "GenSigFirstTimeoutTime" BU_SG_REL_ IC3 SG_ 2566869259 Trailer1TireInfoISO_Warning_ISig 24000;
BA_REL_ "GenSigTimeoutTime" BU_SG_REL_ IC3 SG_ 2566869259 Trailer1TireInfoISO_Warning_ISig 6000;
BA_REL_ "GenSigFirstTimeoutTime" BU_SG_REL_ IC3 SG_ 2566869259 Trailer1TireInfoISO_PowerSupply_ 24000;
BA_REL_ "GenSigTimeoutTime" BU_SG_REL_ IC3 SG_ 2566869259 Trailer1TireInfoISO_PowerSupply_ 6000;
BA_REL_ "GenSigFirstTimeoutTime" BU_SG_REL_ IC3 SG_ 2566869259 Trailer1TireInfoISO_PresSuff_ISi 24000;
BA_REL_ "GenSigTimeoutTime" BU_SG_REL_ IC3 SG_ 2566869259 Trailer1TireInfoISO_PresSuff_ISi 6000;
BA_REL_ "GenSigFirstTimeoutTime" BU_SG_REL_ IC3 SG_ 2566869259 Trailer1TireInfoISO_Active_ISig_ 24000;
BA_REL_ "GenSigTimeoutTime" BU_SG_REL_ IC3 SG_ 2566869259 Trailer1TireInfoISO_Active_ISig_ 6000;
BA_REL_ "GenSigFirstTimeoutTime" BU_SG_REL_ IC3 SG_ 2566869259 Trailer1TireInfoISO_Leakage_ISig 24000;
BA_REL_ "GenSigTimeoutTime" BU_SG_REL_ IC3 SG_ 2566869259 Trailer1TireInfoISO_Leakage_ISig 6000;
BA_REL_ "GenSigFirstTimeoutTime" BU_SG_REL_ IC3 SG_ 2566869259 Trailer1TireInfoISO_Temperature_ 24000;
BA_REL_ "GenSigTimeoutTime" BU_SG_REL_ IC3 SG_ 2566869259 Trailer1TireInfoISO_Temperature_ 6000;
BA_REL_ "GenSigFirstTimeoutTime" BU_SG_REL_ IC3 SG_ 2566869259 Trailer1TireInfoISO_sg_UB_ISig_3 24000;
BA_REL_ "GenSigTimeoutTime" BU_SG_REL_ IC3 SG_ 2566869259 Trailer1TireInfoISO_sg_UB_ISig_3 6000;
BA_REL_ "GenSigFirstTimeoutTime" BU_SG_REL_ IC3 SG_ 2566869259 Trailer1TireInfoISO_Pressure_ISi 24000;
BA_REL_ "GenSigTimeoutTime" BU_SG_REL_ IC3 SG_ 2566869259 Trailer1TireInfoISO_Pressure_ISi 6000;
BA_REL_ "GenSigFirstTimeoutTime" BU_SG_REL_ IC3 SG_ 2566869259 Trailer1TireInfoISO_TireId_ISig_ 24000;
BA_REL_ "GenSigTimeoutTime" BU_SG_REL_ IC3 SG_ 2566869259 Trailer1TireInfoISO_TireId_ISig_ 6000;
BA_REL_ "GenSigFirstTimeoutTime" BU_SG_REL_ IC3 SG_ 2566864651 Trailer5BrakeTemp_Temp_ISig_3 3000;
BA_REL_ "GenSigTimeoutTime" BU_SG_REL_ IC3 SG_ 2566864651 Trailer5BrakeTemp_Temp_ISig_3 600;
BA_REL_ "GenSigFirstTimeoutTime" BU_SG_REL_ IC3 SG_ 2566864651 Trailer4BrakeTemp_TireId_ISig_3 3000;
BA_REL_ "GenSigTimeoutTime" BU_SG_REL_ IC3 SG_ 2566864651 Trailer4BrakeTemp_TireId_ISig_3 600;
BA_REL_ "GenSigFirstTimeoutTime" BU_SG_REL_ IC3 SG_ 2566864651 Trailer5BrakeTemp_Status_ISig_3 3000;
BA_REL_ "GenSigTimeoutTime" BU_SG_REL_ IC3 SG_ 2566864651 Trailer5BrakeTemp_Status_ISig_3 600;
BA_REL_ "GenSigFirstTimeoutTime" BU_SG_REL_ IC3 SG_ 2566864651 Trailer4BrakeTemp_Status_ISig_3 3000;
BA_REL_ "GenSigTimeoutTime" BU_SG_REL_ IC3 SG_ 2566864651 Trailer4BrakeTemp_Status_ISig_3 600;
BA_REL_ "GenSigFirstTimeoutTime" BU_SG_REL_ IC3 SG_ 2566864651 Trailer4BrakeTemp_Temp_ISig_3 3000;
BA_REL_ "GenSigTimeoutTime" BU_SG_REL_ IC3 SG_ 2566864651 Trailer4BrakeTemp_Temp_ISig_3 600;
BA_REL_ "GenSigFirstTimeoutTime" BU_SG_REL_ IC3 SG_ 2566864651 Trailer5BrakeTemp_TireId_ISig_3 3000;
BA_REL_ "GenSigTimeoutTime" BU_SG_REL_ IC3 SG_ 2566864651 Trailer5BrakeTemp_TireId_ISig_3 600;
BA_REL_ "GenSigFirstTimeoutTime" BU_SG_REL_ IC3 SG_ 2566860043 Trailer2BrakeTemp_TireId_ISig_3 3000;
BA_REL_ "GenSigTimeoutTime" BU_SG_REL_ IC3 SG_ 2566860043 Trailer2BrakeTemp_TireId_ISig_3 600;
BA_REL_ "GenSigFirstTimeoutTime" BU_SG_REL_ IC3 SG_ 2566860043 Trailer1BrakeTemp_Status_ISig_3 3000;
BA_REL_ "GenSigTimeoutTime" BU_SG_REL_ IC3 SG_ 2566860043 Trailer1BrakeTemp_Status_ISig_3 600;
BA_REL_ "GenSigFirstTimeoutTime" BU_SG_REL_ IC3 SG_ 2566860043 Trailer2BrakeTemp_Status_ISig_3 3000;
BA_REL_ "GenSigTimeoutTime" BU_SG_REL_ IC3 SG_ 2566860043 Trailer2BrakeTemp_Status_ISig_3 600;
BA_REL_ "GenSigFirstTimeoutTime" BU_SG_REL_ IC3 SG_ 2566860043 Trailer1BrakeTemp_TireId_ISig_3 3000;
BA_REL_ "GenSigTimeoutTime" BU_SG_REL_ IC3 SG_ 2566860043 Trailer1BrakeTemp_TireId_ISig_3 600;
BA_REL_ "GenSigFirstTimeoutTime" BU_SG_REL_ IC3 SG_ 2566860043 Trailer1BrakeTemp_Temp_ISig_3 3000;
BA_REL_ "GenSigTimeoutTime" BU_SG_REL_ IC3 SG_ 2566860043 Trailer1BrakeTemp_Temp_ISig_3 600;
BA_REL_ "GenSigFirstTimeoutTime" BU_SG_REL_ IC3 SG_ 2566860043 Trailer3BrakeTemp_Status_ISig_3 3000;
BA_REL_ "GenSigTimeoutTime" BU_SG_REL_ IC3 SG_ 2566860043 Trailer3BrakeTemp_Status_ISig_3 600;
BA_REL_ "GenSigFirstTimeoutTime" BU_SG_REL_ IC3 SG_ 2566860043 Trailer3BrakeTemp_Temp_ISig_3 3000;
BA_REL_ "GenSigTimeoutTime" BU_SG_REL_ IC3 SG_ 2566860043 Trailer3BrakeTemp_Temp_ISig_3 600;
BA_REL_ "GenSigFirstTimeoutTime" BU_SG_REL_ IC3 SG_ 2566860043 Trailer3BrakeTemp_TireId_ISig_3 3000;
BA_REL_ "GenSigTimeoutTime" BU_SG_REL_ IC3 SG_ 2566860043 Trailer3BrakeTemp_TireId_ISig_3 600;
BA_REL_ "GenSigFirstTimeoutTime" BU_SG_REL_ IC3 SG_ 2566860043 Trailer2BrakeTemp_Temp_ISig_3 3000;
BA_REL_ "GenSigTimeoutTime" BU_SG_REL_ IC3 SG_ 2566860043 Trailer2BrakeTemp_Temp_ISig_3 600;
BA_REL_ "GenSigFirstTimeoutTime" BU_SG_REL_ IC3 SG_ 2566855435 Trailer4ABSStatus_ISig_3 3000;
BA_REL_ "GenSigTimeoutTime" BU_SG_REL_ IC3 SG_ 2566855435 Trailer4ABSStatus_ISig_3 600;
BA_REL_ "GenSigFirstTimeoutTime" BU_SG_REL_ IC3 SG_ 2566855435 Trailer5ABSStatus_ISig_3 3000;
BA_REL_ "GenSigTimeoutTime" BU_SG_REL_ IC3 SG_ 2566855435 Trailer5ABSStatus_ISig_3 600;
BA_REL_ "GenSigFirstTimeoutTime" BU_SG_REL_ IC3 SG_ 2566855435 Trailer2ABSStatus_ISig_3 3000;
BA_REL_ "GenSigTimeoutTime" BU_SG_REL_ IC3 SG_ 2566855435 Trailer2ABSStatus_ISig_3 600;
BA_REL_ "GenSigFirstTimeoutTime" BU_SG_REL_ IC3 SG_ 2566855435 Trailer1ABSStatus_ISig_3 3000;
BA_REL_ "GenSigTimeoutTime" BU_SG_REL_ IC3 SG_ 2566855435 Trailer1ABSStatus_ISig_3 600;
BA_REL_ "GenSigFirstTimeoutTime" BU_SG_REL_ IC3 SG_ 2566855435 Trailer3ABSStatus_ISig_3 3000;
BA_REL_ "GenSigTimeoutTime" BU_SG_REL_ IC3 SG_ 2566855435 Trailer3ABSStatus_ISig_3 600;
BA_REL_ "GenSigFirstTimeoutTime" BU_SG_REL_ IC3 SG_ 2566855435 Trailer1WheelSpdDiffMainAxle_ISi 3000;
BA_REL_ "GenSigTimeoutTime" BU_SG_REL_ IC3 SG_ 2566855435 Trailer1WheelSpdDiffMainAxle_ISi 600;
BA_REL_ "GenSigFirstTimeoutTime" BU_SG_REL_ IC3 SG_ 2566855435 Trailer1LateralAcceleration_ISig 3000;
BA_REL_ "GenSigTimeoutTime" BU_SG_REL_ IC3 SG_ 2566855435 Trailer1LateralAcceleration_ISig 600;
BA_REL_ "GenSigFirstTimeoutTime" BU_SG_REL_ IC3 SG_ 2566850827 Trailer5NormalLevelStorStat_ISig 3000;
BA_REL_ "GenSigTimeoutTime" BU_SG_REL_ IC3 SG_ 2566850827 Trailer5NormalLevelStorStat_ISig 600;
BA_REL_ "GenSigFirstTimeoutTime" BU_SG_REL_ IC3 SG_ 2566850827 Trailer4TractionHelp_ISig_3 3000;
BA_REL_ "GenSigTimeoutTime" BU_SG_REL_ IC3 SG_ 2566850827 Trailer4TractionHelp_ISig_3 600;
BA_REL_ "GenSigFirstTimeoutTime" BU_SG_REL_ IC3 SG_ 2566850827 Trailer2TractionHelp_ISig_3 3000;
BA_REL_ "GenSigTimeoutTime" BU_SG_REL_ IC3 SG_ 2566850827 Trailer2TractionHelp_ISig_3 600;
BA_REL_ "GenSigFirstTimeoutTime" BU_SG_REL_ IC3 SG_ 2566850827 Trailer3StopLevelChangeAck_ISig_ 3000;
BA_REL_ "GenSigTimeoutTime" BU_SG_REL_ IC3 SG_ 2566850827 Trailer3StopLevelChangeAck_ISig_ 600;
BA_REL_ "GenSigFirstTimeoutTime" BU_SG_REL_ IC3 SG_ 2566850827 Trailer4LevelChangeFrontAxle_ISi 3000;
BA_REL_ "GenSigTimeoutTime" BU_SG_REL_ IC3 SG_ 2566850827 Trailer4LevelChangeFrontAxle_ISi 600;
BA_REL_ "GenSigFirstTimeoutTime" BU_SG_REL_ IC3 SG_ 2566850827 Trailer1NormalLevelStorStat_ISig 3000;
BA_REL_ "GenSigTimeoutTime" BU_SG_REL_ IC3 SG_ 2566850827 Trailer1NormalLevelStorStat_ISig 600;
BA_REL_ "GenSigFirstTimeoutTime" BU_SG_REL_ IC3 SG_ 2566850827 Trailer1StopLevelChangeAck_ISig_ 3000;
BA_REL_ "GenSigTimeoutTime" BU_SG_REL_ IC3 SG_ 2566850827 Trailer1StopLevelChangeAck_ISig_ 600;
BA_REL_ "GenSigFirstTimeoutTime" BU_SG_REL_ IC3 SG_ 2566850827 Trailer3LevelChangeFrontAxle_ISi 3000;
BA_REL_ "GenSigTimeoutTime" BU_SG_REL_ IC3 SG_ 2566850827 Trailer3LevelChangeFrontAxle_ISi 600;
BA_REL_ "GenSigFirstTimeoutTime" BU_SG_REL_ IC3 SG_ 2566850827 Trailer5RampLevelStorStat_ISig_3 3000;
BA_REL_ "GenSigTimeoutTime" BU_SG_REL_ IC3 SG_ 2566850827 Trailer5RampLevelStorStat_ISig_3 600;
BA_REL_ "GenSigFirstTimeoutTime" BU_SG_REL_ IC3 SG_ 2566850827 Trailer4LevelChangeRearAxle_ISig 3000;
BA_REL_ "GenSigTimeoutTime" BU_SG_REL_ IC3 SG_ 2566850827 Trailer4LevelChangeRearAxle_ISig 600;
BA_REL_ "GenSigFirstTimeoutTime" BU_SG_REL_ IC3 SG_ 2566850827 Trailer2LevelChangeFrontAxle_ISi 3000;
BA_REL_ "GenSigTimeoutTime" BU_SG_REL_ IC3 SG_ 2566850827 Trailer2LevelChangeFrontAxle_ISi 600;
BA_REL_ "GenSigFirstTimeoutTime" BU_SG_REL_ IC3 SG_ 2566850827 Trailer2RampLevelStorStat_ISig_3 3000;
BA_REL_ "GenSigTimeoutTime" BU_SG_REL_ IC3 SG_ 2566850827 Trailer2RampLevelStorStat_ISig_3 600;
BA_REL_ "GenSigFirstTimeoutTime" BU_SG_REL_ IC3 SG_ 2566850827 Trailer4StopLevelChangeAck_ISig_ 3000;
BA_REL_ "GenSigTimeoutTime" BU_SG_REL_ IC3 SG_ 2566850827 Trailer4StopLevelChangeAck_ISig_ 600;
BA_REL_ "GenSigFirstTimeoutTime" BU_SG_REL_ IC3 SG_ 2566850827 Trailer3NormalLevelStorStat_ISig 3000;
BA_REL_ "GenSigTimeoutTime" BU_SG_REL_ IC3 SG_ 2566850827 Trailer3NormalLevelStorStat_ISig 600;
BA_REL_ "GenSigFirstTimeoutTime" BU_SG_REL_ IC3 SG_ 2566850827 Trailer1TractionHelp_ISig_3 3000;
BA_REL_ "GenSigTimeoutTime" BU_SG_REL_ IC3 SG_ 2566850827 Trailer1TractionHelp_ISig_3 600;
BA_REL_ "GenSigFirstTimeoutTime" BU_SG_REL_ IC3 SG_ 2566850827 Trailer1LevelChangeRearAxle_ISig 3000;
BA_REL_ "GenSigTimeoutTime" BU_SG_REL_ IC3 SG_ 2566850827 Trailer1LevelChangeRearAxle_ISig 600;
BA_REL_ "GenSigFirstTimeoutTime" BU_SG_REL_ IC3 SG_ 2566850827 Trailer5LevelChangeFrontAxle_ISi 3000;
BA_REL_ "GenSigTimeoutTime" BU_SG_REL_ IC3 SG_ 2566850827 Trailer5LevelChangeFrontAxle_ISi 600;
BA_REL_ "GenSigFirstTimeoutTime" BU_SG_REL_ IC3 SG_ 2566850827 Trailer5StopLevelChangeAck_ISig_ 3000;
BA_REL_ "GenSigTimeoutTime" BU_SG_REL_ IC3 SG_ 2566850827 Trailer5StopLevelChangeAck_ISig_ 600;
BA_REL_ "GenSigFirstTimeoutTime" BU_SG_REL_ IC3 SG_ 2566850827 Trailer5TractionHelp_ISig_3 3000;
BA_REL_ "GenSigTimeoutTime" BU_SG_REL_ IC3 SG_ 2566850827 Trailer5TractionHelp_ISig_3 600;
BA_REL_ "GenSigFirstTimeoutTime" BU_SG_REL_ IC3 SG_ 2566850827 Trailer3RampLevelStorStat_ISig_3 3000;
BA_REL_ "GenSigTimeoutTime" BU_SG_REL_ IC3 SG_ 2566850827 Trailer3RampLevelStorStat_ISig_3 600;
BA_REL_ "GenSigFirstTimeoutTime" BU_SG_REL_ IC3 SG_ 2566850827 Trailer2LevelChangeRearAxle_ISig 3000;
BA_REL_ "GenSigTimeoutTime" BU_SG_REL_ IC3 SG_ 2566850827 Trailer2LevelChangeRearAxle_ISig 600;
BA_REL_ "GenSigFirstTimeoutTime" BU_SG_REL_ IC3 SG_ 2566850827 Trailer2StopLevelChangeAck_ISig_ 3000;
BA_REL_ "GenSigTimeoutTime" BU_SG_REL_ IC3 SG_ 2566850827 Trailer2StopLevelChangeAck_ISig_ 600;
BA_REL_ "GenSigFirstTimeoutTime" BU_SG_REL_ IC3 SG_ 2566850827 Trailer3TractionHelp_ISig_3 3000;
BA_REL_ "GenSigTimeoutTime" BU_SG_REL_ IC3 SG_ 2566850827 Trailer3TractionHelp_ISig_3 600;
BA_REL_ "GenSigFirstTimeoutTime" BU_SG_REL_ IC3 SG_ 2566850827 Trailer4RampLevelStorStat_ISig_3 3000;
BA_REL_ "GenSigTimeoutTime" BU_SG_REL_ IC3 SG_ 2566850827 Trailer4RampLevelStorStat_ISig_3 600;
BA_REL_ "GenSigFirstTimeoutTime" BU_SG_REL_ IC3 SG_ 2566850827 Trailer1RampLevelStorStat_ISig_3 3000;
BA_REL_ "GenSigTimeoutTime" BU_SG_REL_ IC3 SG_ 2566850827 Trailer1RampLevelStorStat_ISig_3 600;
BA_REL_ "GenSigFirstTimeoutTime" BU_SG_REL_ IC3 SG_ 2566850827 Trailer1LevelChangeFrontAxle_ISi 3000;
BA_REL_ "GenSigTimeoutTime" BU_SG_REL_ IC3 SG_ 2566850827 Trailer1LevelChangeFrontAxle_ISi 600;
BA_REL_ "GenSigFirstTimeoutTime" BU_SG_REL_ IC3 SG_ 2566850827 Trailer3LevelChangeRearAxle_ISig 3000;
BA_REL_ "GenSigTimeoutTime" BU_SG_REL_ IC3 SG_ 2566850827 Trailer3LevelChangeRearAxle_ISig 600;
BA_REL_ "GenSigFirstTimeoutTime" BU_SG_REL_ IC3 SG_ 2566850827 Trailer5LevelChangeRearAxle_ISig 3000;
BA_REL_ "GenSigTimeoutTime" BU_SG_REL_ IC3 SG_ 2566850827 Trailer5LevelChangeRearAxle_ISig 600;
BA_REL_ "GenSigFirstTimeoutTime" BU_SG_REL_ IC3 SG_ 2566850827 Trailer2NormalLevelStorStat_ISig 3000;
BA_REL_ "GenSigTimeoutTime" BU_SG_REL_ IC3 SG_ 2566850827 Trailer2NormalLevelStorStat_ISig 600;
BA_REL_ "GenSigFirstTimeoutTime" BU_SG_REL_ IC3 SG_ 2566850827 Trailer4NormalLevelStorStat_ISig 3000;
BA_REL_ "GenSigTimeoutTime" BU_SG_REL_ IC3 SG_ 2566850827 Trailer4NormalLevelStorStat_ISig 600;
BA_REL_ "GenSigFirstTimeoutTime" BU_SG_REL_ VMCU SG_ 2566899211 Trailer4TowedVehStat_DetectStat 24000;
BA_REL_ "GenSigTimeoutTime" BU_SG_REL_ VMCU SG_ 2566899211 Trailer4TowedVehStat_DetectStat 6000;
BA_REL_ "GenSigFirstTimeoutTime" BU_SG_REL_ VMCU SG_ 2566899211 Trailer5TowedVehStat_BrakeSystem 24000;
BA_REL_ "GenSigTimeoutTime" BU_SG_REL_ VMCU SG_ 2566899211 Trailer5TowedVehStat_BrakeSystem 6000;
BA_REL_ "GenSigFirstTimeoutTime" BU_SG_REL_ VMCU SG_ 2566899211 Trailer2TowedVehStat_DetectSupp 24000;
BA_REL_ "GenSigTimeoutTime" BU_SG_REL_ VMCU SG_ 2566899211 Trailer2TowedVehStat_DetectSupp 6000;
BA_REL_ "GenSigFirstTimeoutTime" BU_SG_REL_ VMCU SG_ 2566899211 Trailer1TowedVehStat_CANAvail 24000;
BA_REL_ "GenSigTimeoutTime" BU_SG_REL_ VMCU SG_ 2566899211 Trailer1TowedVehStat_CANAvail 6000;
BA_REL_ "GenSigFirstTimeoutTime" BU_SG_REL_ VMCU SG_ 2566899211 Trailer2TowedVehStat_DetectStat 24000;
BA_REL_ "GenSigTimeoutTime" BU_SG_REL_ VMCU SG_ 2566899211 Trailer2TowedVehStat_DetectStat 6000;
BA_REL_ "GenSigFirstTimeoutTime" BU_SG_REL_ VMCU SG_ 2566899211 Trailer2TowedVehStat_BrakeSystem 24000;
BA_REL_ "GenSigTimeoutTime" BU_SG_REL_ VMCU SG_ 2566899211 Trailer2TowedVehStat_BrakeSystem 6000;
BA_REL_ "GenSigFirstTimeoutTime" BU_SG_REL_ VMCU SG_ 2566899211 Trailer2TowedVehStat_CANAvail 24000;
BA_REL_ "GenSigTimeoutTime" BU_SG_REL_ VMCU SG_ 2566899211 Trailer2TowedVehStat_CANAvail 6000;
BA_REL_ "GenSigFirstTimeoutTime" BU_SG_REL_ VMCU SG_ 2566899211 Trailer3TowedVehStat_BrakeSystem 24000;
BA_REL_ "GenSigTimeoutTime" BU_SG_REL_ VMCU SG_ 2566899211 Trailer3TowedVehStat_BrakeSystem 6000;
BA_REL_ "GenSigFirstTimeoutTime" BU_SG_REL_ VMCU SG_ 2566899211 Trailer3TowedVehStat_DetectStat 24000;
BA_REL_ "GenSigTimeoutTime" BU_SG_REL_ VMCU SG_ 2566899211 Trailer3TowedVehStat_DetectStat 6000;
BA_REL_ "GenSigFirstTimeoutTime" BU_SG_REL_ VMCU SG_ 2566899211 Trailer5TowedVehStat_DetectSupp 24000;
BA_REL_ "GenSigTimeoutTime" BU_SG_REL_ VMCU SG_ 2566899211 Trailer5TowedVehStat_DetectSupp 6000;
BA_REL_ "GenSigFirstTimeoutTime" BU_SG_REL_ VMCU SG_ 2566899211 Trailer4TowedVehStat_DetectSupp 24000;
BA_REL_ "GenSigTimeoutTime" BU_SG_REL_ VMCU SG_ 2566899211 Trailer4TowedVehStat_DetectSupp 6000;
BA_REL_ "GenSigFirstTimeoutTime" BU_SG_REL_ VMCU SG_ 2566899211 Trailer5TowedVehStat_DetectStat 24000;
BA_REL_ "GenSigTimeoutTime" BU_SG_REL_ VMCU SG_ 2566899211 Trailer5TowedVehStat_DetectStat 6000;
BA_REL_ "GenSigFirstTimeoutTime" BU_SG_REL_ VMCU SG_ 2566899211 Trailer3TowedVehStat_DetectSupp 24000;
BA_REL_ "GenSigTimeoutTime" BU_SG_REL_ VMCU SG_ 2566899211 Trailer3TowedVehStat_DetectSupp 6000;
BA_REL_ "GenSigFirstTimeoutTime" BU_SG_REL_ VMCU SG_ 2566899211 Trailer1TowedVehStat_DetectSupp 24000;
BA_REL_ "GenSigTimeoutTime" BU_SG_REL_ VMCU SG_ 2566899211 Trailer1TowedVehStat_DetectSupp 6000;
BA_REL_ "GenSigFirstTimeoutTime" BU_SG_REL_ VMCU SG_ 2566899211 Trailer4TowedVehStat_CANAvail 24000;
BA_REL_ "GenSigTimeoutTime" BU_SG_REL_ VMCU SG_ 2566899211 Trailer4TowedVehStat_CANAvail 6000;
BA_REL_ "GenSigFirstTimeoutTime" BU_SG_REL_ VMCU SG_ 2566899211 Trailer1TowedVehStat_BrakeSystem 24000;
BA_REL_ "GenSigTimeoutTime" BU_SG_REL_ VMCU SG_ 2566899211 Trailer1TowedVehStat_BrakeSystem 6000;
BA_REL_ "GenSigFirstTimeoutTime" BU_SG_REL_ VMCU SG_ 2566899211 Trailer5TowedVehStat_CANAvail 24000;
BA_REL_ "GenSigTimeoutTime" BU_SG_REL_ VMCU SG_ 2566899211 Trailer5TowedVehStat_CANAvail 6000;
BA_REL_ "GenSigFirstTimeoutTime" BU_SG_REL_ VMCU SG_ 2566899211 Trailer4TowedVehStat_BrakeSystem 24000;
BA_REL_ "GenSigTimeoutTime" BU_SG_REL_ VMCU SG_ 2566899211 Trailer4TowedVehStat_BrakeSystem 6000;
BA_REL_ "GenSigFirstTimeoutTime" BU_SG_REL_ VMCU SG_ 2566899211 Trailer1TowedVehStat_DetectStat 24000;
BA_REL_ "GenSigTimeoutTime" BU_SG_REL_ VMCU SG_ 2566899211 Trailer1TowedVehStat_DetectStat 6000;
BA_REL_ "GenSigFirstTimeoutTime" BU_SG_REL_ VMCU SG_ 2566899211 Trailer3TowedVehStat_CANAvail 24000;
BA_REL_ "GenSigTimeoutTime" BU_SG_REL_ VMCU SG_ 2566899211 Trailer3TowedVehStat_CANAvail 6000;
BA_REL_ "GenSigFirstTimeoutTime" BU_SG_REL_ IC3 SG_ 2566898955 Trailer5CalibInfo_ScaleLoad_ISig 24000;
BA_REL_ "GenSigTimeoutTime" BU_SG_REL_ IC3 SG_ 2566898955 Trailer5CalibInfo_ScaleLoad_ISig 6000;
BA_REL_ "GenSigFirstTimeoutTime" BU_SG_REL_ VMCU SG_ 2566898955 Trailer5CalibInfo_ScaleLoad_ISig 24000;
BA_REL_ "GenSigTimeoutTime" BU_SG_REL_ VMCU SG_ 2566898955 Trailer5CalibInfo_ScaleLoad_ISig 6000;
BA_REL_ "GenSigFirstTimeoutTime" BU_SG_REL_ VMCU SG_ 2566898955 Trailer5CalibInfo_DataStorage_IS 24000;
BA_REL_ "GenSigTimeoutTime" BU_SG_REL_ VMCU SG_ 2566898955 Trailer5CalibInfo_DataStorage_IS 6000;
BA_REL_ "GenSigFirstTimeoutTime" BU_SG_REL_ IC3 SG_ 2566898955 Trailer5CalibInfo_DataStorage_IS 24000;
BA_REL_ "GenSigTimeoutTime" BU_SG_REL_ IC3 SG_ 2566898955 Trailer5CalibInfo_DataStorage_IS 6000;
BA_REL_ "GenSigFirstTimeoutTime" BU_SG_REL_ IC3 SG_ 2566898955 Trailer5CalibInfo_Year_ISig_3 24000;
BA_REL_ "GenSigTimeoutTime" BU_SG_REL_ IC3 SG_ 2566898955 Trailer5CalibInfo_Year_ISig_3 6000;
BA_REL_ "GenSigFirstTimeoutTime" BU_SG_REL_ VMCU SG_ 2566898955 Trailer5CalibInfo_Year_ISig_3 24000;
BA_REL_ "GenSigTimeoutTime" BU_SG_REL_ VMCU SG_ 2566898955 Trailer5CalibInfo_Year_ISig_3 6000;
BA_REL_ "GenSigFirstTimeoutTime" BU_SG_REL_ VMCU SG_ 2566898955 Trailer5CalibInfo_Month_ISig_3 24000;
BA_REL_ "GenSigTimeoutTime" BU_SG_REL_ VMCU SG_ 2566898955 Trailer5CalibInfo_Month_ISig_3 6000;
BA_REL_ "GenSigFirstTimeoutTime" BU_SG_REL_ IC3 SG_ 2566898955 Trailer5CalibInfo_Month_ISig_3 24000;
BA_REL_ "GenSigTimeoutTime" BU_SG_REL_ IC3 SG_ 2566898955 Trailer5CalibInfo_Month_ISig_3 6000;
BA_REL_ "GenSigFirstTimeoutTime" BU_SG_REL_ IC3 SG_ 2566898955 Trailer5CalibInfo_UncalibLoad_IS 24000;
BA_REL_ "GenSigTimeoutTime" BU_SG_REL_ IC3 SG_ 2566898955 Trailer5CalibInfo_UncalibLoad_IS 6000;
BA_REL_ "GenSigFirstTimeoutTime" BU_SG_REL_ VMCU SG_ 2566898955 Trailer5CalibInfo_UncalibLoad_IS 24000;
BA_REL_ "GenSigTimeoutTime" BU_SG_REL_ VMCU SG_ 2566898955 Trailer5CalibInfo_UncalibLoad_IS 6000;
BA_REL_ "GenSigFirstTimeoutTime" BU_SG_REL_ VMCU SG_ 2566898955 Trailer5CalibInfo_CalibUsage_ISi 24000;
BA_REL_ "GenSigTimeoutTime" BU_SG_REL_ VMCU SG_ 2566898955 Trailer5CalibInfo_CalibUsage_ISi 6000;
BA_REL_ "GenSigFirstTimeoutTime" BU_SG_REL_ IC3 SG_ 2566898955 Trailer5CalibInfo_CalibUsage_ISi 24000;
BA_REL_ "GenSigTimeoutTime" BU_SG_REL_ IC3 SG_ 2566898955 Trailer5CalibInfo_CalibUsage_ISi 6000;
BA_REL_ "GenSigFirstTimeoutTime" BU_SG_REL_ VMCU SG_ 2566898955 Trailer5CalibInfo_AxleId_ISig_3 24000;
BA_REL_ "GenSigTimeoutTime" BU_SG_REL_ VMCU SG_ 2566898955 Trailer5CalibInfo_AxleId_ISig_3 6000;
BA_REL_ "GenSigFirstTimeoutTime" BU_SG_REL_ IC3 SG_ 2566898955 Trailer5CalibInfo_AxleId_ISig_3 24000;
BA_REL_ "GenSigTimeoutTime" BU_SG_REL_ IC3 SG_ 2566898955 Trailer5CalibInfo_AxleId_ISig_3 6000;
BA_REL_ "GenSigFirstTimeoutTime" BU_SG_REL_ IC3 SG_ 2566898955 Trailer5CalibInfo_LoadRange_ISig 24000;
BA_REL_ "GenSigTimeoutTime" BU_SG_REL_ IC3 SG_ 2566898955 Trailer5CalibInfo_LoadRange_ISig 6000;
BA_REL_ "GenSigFirstTimeoutTime" BU_SG_REL_ VMCU SG_ 2566898955 Trailer5CalibInfo_LoadRange_ISig 24000;
BA_REL_ "GenSigTimeoutTime" BU_SG_REL_ VMCU SG_ 2566898955 Trailer5CalibInfo_LoadRange_ISig 6000;
BA_REL_ "GenSigFirstTimeoutTime" BU_SG_REL_ IC3 SG_ 2566898699 Trailer4CalibInfo_Month_ISig_3 24000;
BA_REL_ "GenSigTimeoutTime" BU_SG_REL_ IC3 SG_ 2566898699 Trailer4CalibInfo_Month_ISig_3 6000;
BA_REL_ "GenSigFirstTimeoutTime" BU_SG_REL_ VMCU SG_ 2566898699 Trailer4CalibInfo_Month_ISig_3 24000;
BA_REL_ "GenSigTimeoutTime" BU_SG_REL_ VMCU SG_ 2566898699 Trailer4CalibInfo_Month_ISig_3 6000;
BA_REL_ "GenSigFirstTimeoutTime" BU_SG_REL_ IC3 SG_ 2566898699 Trailer4CalibInfo_DataStorage_IS 24000;
BA_REL_ "GenSigTimeoutTime" BU_SG_REL_ IC3 SG_ 2566898699 Trailer4CalibInfo_DataStorage_IS 6000;
BA_REL_ "GenSigFirstTimeoutTime" BU_SG_REL_ VMCU SG_ 2566898699 Trailer4CalibInfo_DataStorage_IS 24000;
BA_REL_ "GenSigTimeoutTime" BU_SG_REL_ VMCU SG_ 2566898699 Trailer4CalibInfo_DataStorage_IS 6000;
BA_REL_ "GenSigFirstTimeoutTime" BU_SG_REL_ IC3 SG_ 2566898699 Trailer4CalibInfo_CalibUsage_ISi 24000;
BA_REL_ "GenSigTimeoutTime" BU_SG_REL_ IC3 SG_ 2566898699 Trailer4CalibInfo_CalibUsage_ISi 6000;
BA_REL_ "GenSigFirstTimeoutTime" BU_SG_REL_ VMCU SG_ 2566898699 Trailer4CalibInfo_CalibUsage_ISi 24000;
BA_REL_ "GenSigTimeoutTime" BU_SG_REL_ VMCU SG_ 2566898699 Trailer4CalibInfo_CalibUsage_ISi 6000;
BA_REL_ "GenSigFirstTimeoutTime" BU_SG_REL_ VMCU SG_ 2566898699 Trailer4CalibInfo_ScaleLoad_ISig 24000;
BA_REL_ "GenSigTimeoutTime" BU_SG_REL_ VMCU SG_ 2566898699 Trailer4CalibInfo_ScaleLoad_ISig 6000;
BA_REL_ "GenSigFirstTimeoutTime" BU_SG_REL_ IC3 SG_ 2566898699 Trailer4CalibInfo_ScaleLoad_ISig 24000;
BA_REL_ "GenSigTimeoutTime" BU_SG_REL_ IC3 SG_ 2566898699 Trailer4CalibInfo_ScaleLoad_ISig 6000;
BA_REL_ "GenSigFirstTimeoutTime" BU_SG_REL_ VMCU SG_ 2566898699 Trailer4CalibInfo_LoadRange_ISig 24000;
BA_REL_ "GenSigTimeoutTime" BU_SG_REL_ VMCU SG_ 2566898699 Trailer4CalibInfo_LoadRange_ISig 6000;
BA_REL_ "GenSigFirstTimeoutTime" BU_SG_REL_ IC3 SG_ 2566898699 Trailer4CalibInfo_LoadRange_ISig 24000;
BA_REL_ "GenSigTimeoutTime" BU_SG_REL_ IC3 SG_ 2566898699 Trailer4CalibInfo_LoadRange_ISig 6000;
BA_REL_ "GenSigFirstTimeoutTime" BU_SG_REL_ IC3 SG_ 2566898699 Trailer4CalibInfo_Year_ISig_3 24000;
BA_REL_ "GenSigTimeoutTime" BU_SG_REL_ IC3 SG_ 2566898699 Trailer4CalibInfo_Year_ISig_3 6000;
BA_REL_ "GenSigFirstTimeoutTime" BU_SG_REL_ VMCU SG_ 2566898699 Trailer4CalibInfo_Year_ISig_3 24000;
BA_REL_ "GenSigTimeoutTime" BU_SG_REL_ VMCU SG_ 2566898699 Trailer4CalibInfo_Year_ISig_3 6000;
BA_REL_ "GenSigFirstTimeoutTime" BU_SG_REL_ VMCU SG_ 2566898699 Trailer4CalibInfo_AxleId_ISig_3 24000;
BA_REL_ "GenSigTimeoutTime" BU_SG_REL_ VMCU SG_ 2566898699 Trailer4CalibInfo_AxleId_ISig_3 6000;
BA_REL_ "GenSigFirstTimeoutTime" BU_SG_REL_ IC3 SG_ 2566898699 Trailer4CalibInfo_AxleId_ISig_3 24000;
BA_REL_ "GenSigTimeoutTime" BU_SG_REL_ IC3 SG_ 2566898699 Trailer4CalibInfo_AxleId_ISig_3 6000;
BA_REL_ "GenSigFirstTimeoutTime" BU_SG_REL_ IC3 SG_ 2566898699 Trailer4CalibInfo_UncalibLoad_IS 24000;
BA_REL_ "GenSigTimeoutTime" BU_SG_REL_ IC3 SG_ 2566898699 Trailer4CalibInfo_UncalibLoad_IS 6000;
BA_REL_ "GenSigFirstTimeoutTime" BU_SG_REL_ VMCU SG_ 2566898699 Trailer4CalibInfo_UncalibLoad_IS 24000;
BA_REL_ "GenSigTimeoutTime" BU_SG_REL_ VMCU SG_ 2566898699 Trailer4CalibInfo_UncalibLoad_IS 6000;
BA_REL_ "GenSigFirstTimeoutTime" BU_SG_REL_ IC3 SG_ 2566898443 Trailer3CalibInfo_ScaleLoad_ISig 24000;
BA_REL_ "GenSigTimeoutTime" BU_SG_REL_ IC3 SG_ 2566898443 Trailer3CalibInfo_ScaleLoad_ISig 6000;
BA_REL_ "GenSigFirstTimeoutTime" BU_SG_REL_ VMCU SG_ 2566898443 Trailer3CalibInfo_ScaleLoad_ISig 24000;
BA_REL_ "GenSigTimeoutTime" BU_SG_REL_ VMCU SG_ 2566898443 Trailer3CalibInfo_ScaleLoad_ISig 6000;
BA_REL_ "GenSigFirstTimeoutTime" BU_SG_REL_ VMCU SG_ 2566898443 Trailer3CalibInfo_Month_ISig_3 24000;
BA_REL_ "GenSigTimeoutTime" BU_SG_REL_ VMCU SG_ 2566898443 Trailer3CalibInfo_Month_ISig_3 6000;
BA_REL_ "GenSigFirstTimeoutTime" BU_SG_REL_ IC3 SG_ 2566898443 Trailer3CalibInfo_Month_ISig_3 24000;
BA_REL_ "GenSigTimeoutTime" BU_SG_REL_ IC3 SG_ 2566898443 Trailer3CalibInfo_Month_ISig_3 6000;
BA_REL_ "GenSigFirstTimeoutTime" BU_SG_REL_ VMCU SG_ 2566898443 Trailer3CalibInfo_AxleId_ISig_3 24000;
BA_REL_ "GenSigTimeoutTime" BU_SG_REL_ VMCU SG_ 2566898443 Trailer3CalibInfo_AxleId_ISig_3 6000;
BA_REL_ "GenSigFirstTimeoutTime" BU_SG_REL_ IC3 SG_ 2566898443 Trailer3CalibInfo_AxleId_ISig_3 24000;
BA_REL_ "GenSigTimeoutTime" BU_SG_REL_ IC3 SG_ 2566898443 Trailer3CalibInfo_AxleId_ISig_3 6000;
BA_REL_ "GenSigFirstTimeoutTime" BU_SG_REL_ IC3 SG_ 2566898443 Trailer3CalibInfo_UncalibLoad_IS 24000;
BA_REL_ "GenSigTimeoutTime" BU_SG_REL_ IC3 SG_ 2566898443 Trailer3CalibInfo_UncalibLoad_IS 6000;
BA_REL_ "GenSigFirstTimeoutTime" BU_SG_REL_ VMCU SG_ 2566898443 Trailer3CalibInfo_UncalibLoad_IS 24000;
BA_REL_ "GenSigTimeoutTime" BU_SG_REL_ VMCU SG_ 2566898443 Trailer3CalibInfo_UncalibLoad_IS 6000;
BA_REL_ "GenSigFirstTimeoutTime" BU_SG_REL_ IC3 SG_ 2566898443 Trailer3CalibInfo_CalibUsage_ISi 24000;
BA_REL_ "GenSigTimeoutTime" BU_SG_REL_ IC3 SG_ 2566898443 Trailer3CalibInfo_CalibUsage_ISi 6000;
BA_REL_ "GenSigFirstTimeoutTime" BU_SG_REL_ VMCU SG_ 2566898443 Trailer3CalibInfo_CalibUsage_ISi 24000;
BA_REL_ "GenSigTimeoutTime" BU_SG_REL_ VMCU SG_ 2566898443 Trailer3CalibInfo_CalibUsage_ISi 6000;
BA_REL_ "GenSigFirstTimeoutTime" BU_SG_REL_ IC3 SG_ 2566898443 Trailer3CalibInfo_LoadRange_ISig 24000;
BA_REL_ "GenSigTimeoutTime" BU_SG_REL_ IC3 SG_ 2566898443 Trailer3CalibInfo_LoadRange_ISig 6000;
BA_REL_ "GenSigFirstTimeoutTime" BU_SG_REL_ VMCU SG_ 2566898443 Trailer3CalibInfo_LoadRange_ISig 24000;
BA_REL_ "GenSigTimeoutTime" BU_SG_REL_ VMCU SG_ 2566898443 Trailer3CalibInfo_LoadRange_ISig 6000;
BA_REL_ "GenSigFirstTimeoutTime" BU_SG_REL_ IC3 SG_ 2566898443 Trailer3CalibInfo_DataStorage_IS 24000;
BA_REL_ "GenSigTimeoutTime" BU_SG_REL_ IC3 SG_ 2566898443 Trailer3CalibInfo_DataStorage_IS 6000;
BA_REL_ "GenSigFirstTimeoutTime" BU_SG_REL_ VMCU SG_ 2566898443 Trailer3CalibInfo_DataStorage_IS 24000;
BA_REL_ "GenSigTimeoutTime" BU_SG_REL_ VMCU SG_ 2566898443 Trailer3CalibInfo_DataStorage_IS 6000;
BA_REL_ "GenSigFirstTimeoutTime" BU_SG_REL_ VMCU SG_ 2566898443 Trailer3CalibInfo_Year_ISig_3 24000;
BA_REL_ "GenSigTimeoutTime" BU_SG_REL_ VMCU SG_ 2566898443 Trailer3CalibInfo_Year_ISig_3 6000;
BA_REL_ "GenSigFirstTimeoutTime" BU_SG_REL_ IC3 SG_ 2566898443 Trailer3CalibInfo_Year_ISig_3 24000;
BA_REL_ "GenSigTimeoutTime" BU_SG_REL_ IC3 SG_ 2566898443 Trailer3CalibInfo_Year_ISig_3 6000;
VAL_ 2566906891 Trailer4VehicleType_ISig_3 3 "TrailerVehicleType_NotAvailable" 2 "TrailerVehicleType_Error" 1 "TrailerVehicleType_ConverterDollyAxle" 0 "TrailerVehicleType_TowingOrTowedVehicle" ;
VAL_ 2566906891 Trailer4YCSystemStatus_ISig_3 3 "DisableEnable_NotAvailable" 2 "DisableEnable_Error" 1 "DisableEnable_Enable" 0 "DisableEnable_Disable" ;
VAL_ 2566906891 Trailer4EBSAmberWarning_ISig_3 3 "WarningIndicator_NotAvailable" 2 "WarningIndicator_Flashing" 1 "WarningIndicator_OnContinuously" 0 "WarningIndicator_Off" ;
VAL_ 2566906891 Trailer4LevelControlStatus_ISig_ 3 "DisableEnable_NotAvailable" 2 "DisableEnable_Error" 1 "DisableEnable_Enable" 0 "DisableEnable_Disable" ;
VAL_ 2566906891 Trailer4ROPSystemStatus_ISig_3 3 "DisableEnable_NotAvailable" 2 "DisableEnable_Error" 1 "DisableEnable_Enable" 0 "DisableEnable_Disable" ;
VAL_ 2566906891 Trailer4LoadRampApprAssistStat_I 3 "ActiveStatus_NotAvailable" 2 "ActiveStatus_Error" 1 "ActiveStatus_Active" 0 "ActiveStatus_NotActive" ;
VAL_ 2566906891 Trailer4ExtLvlStorageSupport_ISi 3 "TrailerExtLvlStorageSupport_NotSupported" 2 "TrailerExtLvlStorageSupport_Error" 1 "TrailerExtLvlStorageSupport_SupportedIn2ExtendedSets" 0 "TrailerExtLvlStorageSupport_SupportedInAll3Sets" ;
VAL_ 2566906891 Trailer4PneumSupply_Status_ISig_ 3 "InsufficientSufficient_NotAvailable" 2 "InsufficientSufficient_Error" 1 "InsufficientSufficient_Sufficient" 0 "InsufficientSufficient_Insufficient" ;
VAL_ 2566906891 Trailer4EBSRedWarning_ISig_3 3 "OffOn_NotAvailable" 2 "OffOn_Error" 1 "OffOn_On" 0 "OffOn_Off" ;
VAL_ 2566906891 Trailer4ElectricalSupplyStat_ISi 3 "InsufficientSufficient_NotAvailable" 2 "InsufficientSufficient_Error" 1 "InsufficientSufficient_Sufficient" 0 "InsufficientSufficient_Insufficient" ;
VAL_ 2566902283 Trailer3YCSystemStatus_ISig_3 3 "DisableEnable_NotAvailable" 2 "DisableEnable_Error" 1 "DisableEnable_Enable" 0 "DisableEnable_Disable" ;
VAL_ 2566902283 Trailer3EBSAmberWarning_ISig_3 3 "WarningIndicator_NotAvailable" 2 "WarningIndicator_Flashing" 1 "WarningIndicator_OnContinuously" 0 "WarningIndicator_Off" ;
VAL_ 2566902283 Trailer3EBSRedWarning_ISig_3 3 "OffOn_NotAvailable" 2 "OffOn_Error" 1 "OffOn_On" 0 "OffOn_Off" ;
VAL_ 2566902283 Trailer3PneumSupply_Status_ISig_ 3 "InsufficientSufficient_NotAvailable" 2 "InsufficientSufficient_Error" 1 "InsufficientSufficient_Sufficient" 0 "InsufficientSufficient_Insufficient" ;
VAL_ 2566902283 Trailer3LoadRampApprAssistStat_I 3 "ActiveStatus_NotAvailable" 2 "ActiveStatus_Error" 1 "ActiveStatus_Active" 0 "ActiveStatus_NotActive" ;
VAL_ 2566902283 Trailer3ROPSystemStatus_ISig_3 3 "DisableEnable_NotAvailable" 2 "DisableEnable_Error" 1 "DisableEnable_Enable" 0 "DisableEnable_Disable" ;
VAL_ 2566902283 Trailer3ElectricalSupplyStat_ISi 3 "InsufficientSufficient_NotAvailable" 2 "InsufficientSufficient_Error" 1 "InsufficientSufficient_Sufficient" 0 "InsufficientSufficient_Insufficient" ;
VAL_ 2566902283 Trailer3LevelControlStatus_ISig_ 3 "DisableEnable_NotAvailable" 2 "DisableEnable_Error" 1 "DisableEnable_Enable" 0 "DisableEnable_Disable" ;
VAL_ 2566902283 Trailer3VehicleType_ISig_3 3 "TrailerVehicleType_NotAvailable" 2 "TrailerVehicleType_Error" 1 "TrailerVehicleType_ConverterDollyAxle" 0 "TrailerVehicleType_TowingOrTowedVehicle" ;
VAL_ 2566902283 Trailer3ExtLvlStorageSupport_ISi 3 "TrailerExtLvlStorageSupport_NotSupported" 2 "TrailerExtLvlStorageSupport_Error" 1 "TrailerExtLvlStorageSupport_SupportedIn2ExtendedSets" 0 "TrailerExtLvlStorageSupport_SupportedInAll3Sets" ;
VAL_ 2566897419 Trailer2VehicleType_ISig_3 3 "TrailerVehicleType_NotAvailable" 2 "TrailerVehicleType_Error" 1 "TrailerVehicleType_ConverterDollyAxle" 0 "TrailerVehicleType_TowingOrTowedVehicle" ;
VAL_ 2566897419 Trailer2EBSAmberWarning_ISig_3 3 "WarningIndicator_NotAvailable" 2 "WarningIndicator_Flashing" 1 "WarningIndicator_OnContinuously" 0 "WarningIndicator_Off" ;
VAL_ 2566897419 Trailer2YCSystemStatus_ISig_3 3 "DisableEnable_NotAvailable" 2 "DisableEnable_Error" 1 "DisableEnable_Enable" 0 "DisableEnable_Disable" ;
VAL_ 2566897419 Trailer2ExtLvlStorageSupport_ISi 3 "TrailerExtLvlStorageSupport_NotSupported" 2 "TrailerExtLvlStorageSupport_Error" 1 "TrailerExtLvlStorageSupport_SupportedIn2ExtendedSets" 0 "TrailerExtLvlStorageSupport_SupportedInAll3Sets" ;
VAL_ 2566897419 Trailer2ROPSystemStatus_ISig_3 3 "DisableEnable_NotAvailable" 2 "DisableEnable_Error" 1 "DisableEnable_Enable" 0 "DisableEnable_Disable" ;
VAL_ 2566897419 Trailer2PneumSupply_Status_ISig_ 3 "InsufficientSufficient_NotAvailable" 2 "InsufficientSufficient_Error" 1 "InsufficientSufficient_Sufficient" 0 "InsufficientSufficient_Insufficient" ;
VAL_ 2566897419 Trailer2ElectricalSupplyStat_ISi 3 "InsufficientSufficient_NotAvailable" 2 "InsufficientSufficient_Error" 1 "InsufficientSufficient_Sufficient" 0 "InsufficientSufficient_Insufficient" ;
VAL_ 2566897419 Trailer2LevelControlStatus_ISig_ 3 "DisableEnable_NotAvailable" 2 "DisableEnable_Error" 1 "DisableEnable_Enable" 0 "DisableEnable_Disable" ;
VAL_ 2566897419 Trailer2LoadRampApprAssistStat_I 3 "ActiveStatus_NotAvailable" 2 "ActiveStatus_Error" 1 "ActiveStatus_Active" 0 "ActiveStatus_NotActive" ;
VAL_ 2566897419 Trailer2EBSRedWarning_ISig_3 3 "OffOn_NotAvailable" 2 "OffOn_Error" 1 "OffOn_On" 0 "OffOn_Off" ;
VAL_ 2566892811 Trailer1LoadRampApprAssistStat_I 3 "ActiveStatus_NotAvailable" 2 "ActiveStatus_Error" 1 "ActiveStatus_Active" 0 "ActiveStatus_NotActive" ;
VAL_ 2566892811 Trailer1VehicleType_ISig_3 3 "TrailerVehicleType_NotAvailable" 2 "TrailerVehicleType_Error" 1 "TrailerVehicleType_ConverterDollyAxle" 0 "TrailerVehicleType_TowingOrTowedVehicle" ;
VAL_ 2566892811 Trailer1EBSRedWarning_ISig_3 3 "OffOn_NotAvailable" 2 "OffOn_Error" 1 "OffOn_On" 0 "OffOn_Off" ;
VAL_ 2566892811 Trailer1LevelControlStatus_ISig_ 3 "DisableEnable_NotAvailable" 2 "DisableEnable_Error" 1 "DisableEnable_Enable" 0 "DisableEnable_Disable" ;
VAL_ 2566892811 Trailer1ElectricalSupplyStat_ISi 3 "InsufficientSufficient_NotAvailable" 2 "InsufficientSufficient_Error" 1 "InsufficientSufficient_Sufficient" 0 "InsufficientSufficient_Insufficient" ;
VAL_ 2566892811 Trailer1PneumSupply_Status_ISig_ 3 "InsufficientSufficient_NotAvailable" 2 "InsufficientSufficient_Error" 1 "InsufficientSufficient_Sufficient" 0 "InsufficientSufficient_Insufficient" ;
VAL_ 2566892811 Trailer1ROPSystemStatus_ISig_3 3 "DisableEnable_NotAvailable" 2 "DisableEnable_Error" 1 "DisableEnable_Enable" 0 "DisableEnable_Disable" ;
VAL_ 2566892811 Trailer1YCSystemStatus_ISig_3 3 "DisableEnable_NotAvailable" 2 "DisableEnable_Error" 1 "DisableEnable_Enable" 0 "DisableEnable_Disable" ;
VAL_ 2566892811 Trailer1ExtLvlStorageSupport_ISi 3 "TrailerExtLvlStorageSupport_NotSupported" 2 "TrailerExtLvlStorageSupport_Error" 1 "TrailerExtLvlStorageSupport_SupportedIn2ExtendedSets" 0 "TrailerExtLvlStorageSupport_SupportedInAll3Sets" ;
VAL_ 2566892811 Trailer1EBSAmberWarning_ISig_3 3 "WarningIndicator_NotAvailable" 2 "WarningIndicator_Flashing" 1 "WarningIndicator_OnContinuously" 0 "WarningIndicator_Off" ;
VAL_ 2566887947 Trailer5TireInfoISO_Active_ISig_ 3 "TPMTireActive_NotAvailable" 2 "TPMTireActive_Error" 1 "TPMTireActive_TireActivePositioned" 0 "TPMTireActive_TireNotActive" ;
VAL_ 2566887947 Trailer5TireInfoISO_PowerSupply_ 3 "TPMISOPowerSupply_NotAvailable" 2 "TPMISOPowerSupply_Error" 1 "TPMISOPowerSupply_SufficientPowerSupply" 0 "TPMISOPowerSupply_InsufficientPowerSupply" ;
VAL_ 2566887947 Trailer5TireInfoISO_Warning_ISig 7 "TPMPressureWarning_NotAvailable" 6 "TPMPressureWarning_Error" 5 "TPMPressureWarning_Spare" 4 "TPMPressureWarning_ExtremeUnderPressure" 3 "TPMPressureWarning_UnderPressure" 2 "TPMPressureWarning_NoWarningPressure" 1 "TPMPressureWarning_OverPressure" 0 "TPMPressureWarning_ExtremeOverPressure" ;
VAL_ 2566887947 Trailer5TireInfoISO_PresSuff_ISi 3 "TPMISOPresSuff_NotAvailable" 2 "TPMISOPresSuff_Error" 1 "TPMISOPresSuff_TirePressureSufficient" 0 "TPMISOPresSuff_TirePressureInsufficient" ;
VAL_ 2566883339 Trailer4TireInfoISO_PresSuff_ISi 3 "TPMISOPresSuff_NotAvailable" 2 "TPMISOPresSuff_Error" 1 "TPMISOPresSuff_TirePressureSufficient" 0 "TPMISOPresSuff_TirePressureInsufficient" ;
VAL_ 2566883339 Trailer4TireInfoISO_Active_ISig_ 3 "TPMTireActive_NotAvailable" 2 "TPMTireActive_Error" 1 "TPMTireActive_TireActivePositioned" 0 "TPMTireActive_TireNotActive" ;
VAL_ 2566883339 Trailer4TireInfoISO_PowerSupply_ 3 "TPMISOPowerSupply_NotAvailable" 2 "TPMISOPowerSupply_Error" 1 "TPMISOPowerSupply_SufficientPowerSupply" 0 "TPMISOPowerSupply_InsufficientPowerSupply" ;
VAL_ 2566883339 Trailer4TireInfoISO_Warning_ISig 7 "TPMPressureWarning_NotAvailable" 6 "TPMPressureWarning_Error" 5 "TPMPressureWarning_Spare" 4 "TPMPressureWarning_ExtremeUnderPressure" 3 "TPMPressureWarning_UnderPressure" 2 "TPMPressureWarning_NoWarningPressure" 1 "TPMPressureWarning_OverPressure" 0 "TPMPressureWarning_ExtremeOverPressure" ;
VAL_ 2566878731 Trailer3TireInfoISO_Warning_ISig 7 "TPMPressureWarning_NotAvailable" 6 "TPMPressureWarning_Error" 5 "TPMPressureWarning_Spare" 4 "TPMPressureWarning_ExtremeUnderPressure" 3 "TPMPressureWarning_UnderPressure" 2 "TPMPressureWarning_NoWarningPressure" 1 "TPMPressureWarning_OverPressure" 0 "TPMPressureWarning_ExtremeOverPressure" ;
VAL_ 2566878731 Trailer3TireInfoISO_Active_ISig_ 3 "TPMTireActive_NotAvailable" 2 "TPMTireActive_Error" 1 "TPMTireActive_TireActivePositioned" 0 "TPMTireActive_TireNotActive" ;
VAL_ 2566878731 Trailer3TireInfoISO_PowerSupply_ 3 "TPMISOPowerSupply_NotAvailable" 2 "TPMISOPowerSupply_Error" 1 "TPMISOPowerSupply_SufficientPowerSupply" 0 "TPMISOPowerSupply_InsufficientPowerSupply" ;
VAL_ 2566878731 Trailer3TireInfoISO_PresSuff_ISi 3 "TPMISOPresSuff_NotAvailable" 2 "TPMISOPresSuff_Error" 1 "TPMISOPresSuff_TirePressureSufficient" 0 "TPMISOPresSuff_TirePressureInsufficient" ;
VAL_ 2566874123 Trailer2TireInfoISO_PowerSupply_ 3 "TPMISOPowerSupply_NotAvailable" 2 "TPMISOPowerSupply_Error" 1 "TPMISOPowerSupply_SufficientPowerSupply" 0 "TPMISOPowerSupply_InsufficientPowerSupply" ;
VAL_ 2566874123 Trailer2TireInfoISO_Active_ISig_ 3 "TPMTireActive_NotAvailable" 2 "TPMTireActive_Error" 1 "TPMTireActive_TireActivePositioned" 0 "TPMTireActive_TireNotActive" ;
VAL_ 2566874123 Trailer2TireInfoISO_PresSuff_ISi 3 "TPMISOPresSuff_NotAvailable" 2 "TPMISOPresSuff_Error" 1 "TPMISOPresSuff_TirePressureSufficient" 0 "TPMISOPresSuff_TirePressureInsufficient" ;
VAL_ 2566874123 Trailer2TireInfoISO_Warning_ISig 7 "TPMPressureWarning_NotAvailable" 6 "TPMPressureWarning_Error" 5 "TPMPressureWarning_Spare" 4 "TPMPressureWarning_ExtremeUnderPressure" 3 "TPMPressureWarning_UnderPressure" 2 "TPMPressureWarning_NoWarningPressure" 1 "TPMPressureWarning_OverPressure" 0 "TPMPressureWarning_ExtremeOverPressure" ;
VAL_ 2566869259 Trailer1TireInfoISO_Warning_ISig 7 "TPMPressureWarning_NotAvailable" 6 "TPMPressureWarning_Error" 5 "TPMPressureWarning_Spare" 4 "TPMPressureWarning_ExtremeUnderPressure" 3 "TPMPressureWarning_UnderPressure" 2 "TPMPressureWarning_NoWarningPressure" 1 "TPMPressureWarning_OverPressure" 0 "TPMPressureWarning_ExtremeOverPressure" ;
VAL_ 2566869259 Trailer1TireInfoISO_PowerSupply_ 3 "TPMISOPowerSupply_NotAvailable" 2 "TPMISOPowerSupply_Error" 1 "TPMISOPowerSupply_SufficientPowerSupply" 0 "TPMISOPowerSupply_InsufficientPowerSupply" ;
VAL_ 2566869259 Trailer1TireInfoISO_PresSuff_ISi 3 "TPMISOPresSuff_NotAvailable" 2 "TPMISOPresSuff_Error" 1 "TPMISOPresSuff_TirePressureSufficient" 0 "TPMISOPresSuff_TirePressureInsufficient" ;
VAL_ 2566869259 Trailer1TireInfoISO_Active_ISig_ 3 "TPMTireActive_NotAvailable" 2 "TPMTireActive_Error" 1 "TPMTireActive_TireActivePositioned" 0 "TPMTireActive_TireNotActive" ;
VAL_ 2566864651 Trailer5BrakeTemp_Status_ISig_3 3 "BrakeTempStatus_NotAvailable" 2 "BrakeTempStatus_Error" 1 "BrakeTempStatus_BrakeTempInsideNormalRange" 0 "BrakeTempStatus_BrakeTempOutOfRange" ;
VAL_ 2566864651 Trailer4BrakeTemp_Status_ISig_3 3 "BrakeTempStatus_NotAvailable" 2 "BrakeTempStatus_Error" 1 "BrakeTempStatus_BrakeTempInsideNormalRange" 0 "BrakeTempStatus_BrakeTempOutOfRange" ;
VAL_ 2566860043 Trailer1BrakeTemp_Status_ISig_3 3 "BrakeTempStatus_NotAvailable" 2 "BrakeTempStatus_Error" 1 "BrakeTempStatus_BrakeTempInsideNormalRange" 0 "BrakeTempStatus_BrakeTempOutOfRange" ;
VAL_ 2566860043 Trailer2BrakeTemp_Status_ISig_3 3 "BrakeTempStatus_NotAvailable" 2 "BrakeTempStatus_Error" 1 "BrakeTempStatus_BrakeTempInsideNormalRange" 0 "BrakeTempStatus_BrakeTempOutOfRange" ;
VAL_ 2566860043 Trailer3BrakeTemp_Status_ISig_3 3 "BrakeTempStatus_NotAvailable" 2 "BrakeTempStatus_Error" 1 "BrakeTempStatus_BrakeTempInsideNormalRange" 0 "BrakeTempStatus_BrakeTempOutOfRange" ;
VAL_ 2566855435 Trailer4ABSStatus_ISig_3 3 "PassiveActive_NotAvailable" 2 "PassiveActive_Error" 1 "PassiveActive_Active" 0 "PassiveActive_Passive" ;
VAL_ 2566855435 Trailer5ABSStatus_ISig_3 3 "PassiveActive_NotAvailable" 2 "PassiveActive_Error" 1 "PassiveActive_Active" 0 "PassiveActive_Passive" ;
VAL_ 2566855435 Trailer2ABSStatus_ISig_3 3 "PassiveActive_NotAvailable" 2 "PassiveActive_Error" 1 "PassiveActive_Active" 0 "PassiveActive_Passive" ;
VAL_ 2566855435 Trailer1ABSStatus_ISig_3 3 "PassiveActive_NotAvailable" 2 "PassiveActive_Error" 1 "PassiveActive_Active" 0 "PassiveActive_Passive" ;
VAL_ 2566855435 Trailer3ABSStatus_ISig_3 3 "PassiveActive_NotAvailable" 2 "PassiveActive_Error" 1 "PassiveActive_Active" 0 "PassiveActive_Passive" ;
VAL_ 2566850827 Trailer5NormalLevelStorStat_ISig 3 "TrailerNormalLevelStorStat_NotAvailable" 2 "TrailerNormalLevelStorStat_RideHeightNotStoredInReqSet" 1 "TrailerNormalLevelStorStat_NewRideHeightStored" 0 "TrailerNormalLevelStorStat_NoNewRideHeightStorageRequest" ;
VAL_ 2566850827 Trailer4TractionHelp_ISig_3 3 "InactiveActive_NotAvailable" 2 "InactiveActive_Error" 1 "InactiveActive_Active" 0 "InactiveActive_Inactive" ;
VAL_ 2566850827 Trailer2TractionHelp_ISig_3 3 "InactiveActive_NotAvailable" 2 "InactiveActive_Error" 1 "InactiveActive_Active" 0 "InactiveActive_Inactive" ;
VAL_ 2566850827 Trailer3StopLevelChangeAck_ISig_ 3 "StopLevelChangeStatus_NotAvailable" 2 "StopLevelChangeStatus_ErrorIndicator" 1 "StopLevelChangeStatus_LevelChangedStopped" 0 "StopLevelChangeStatus_NoStopRequest" ;
VAL_ 2566850827 Trailer4LevelChangeFrontAxle_ISi 3 "ActiveStatus_NotAvailable" 2 "ActiveStatus_Error" 1 "ActiveStatus_Active" 0 "ActiveStatus_NotActive" ;
VAL_ 2566850827 Trailer1NormalLevelStorStat_ISig 3 "TrailerNormalLevelStorStat_NotAvailable" 2 "TrailerNormalLevelStorStat_RideHeightNotStoredInReqSet" 1 "TrailerNormalLevelStorStat_NewRideHeightStored" 0 "TrailerNormalLevelStorStat_NoNewRideHeightStorageRequest" ;
VAL_ 2566850827 Trailer1StopLevelChangeAck_ISig_ 3 "StopLevelChangeStatus_NotAvailable" 2 "StopLevelChangeStatus_ErrorIndicator" 1 "StopLevelChangeStatus_LevelChangedStopped" 0 "StopLevelChangeStatus_NoStopRequest" ;
VAL_ 2566850827 Trailer3LevelChangeFrontAxle_ISi 3 "ActiveStatus_NotAvailable" 2 "ActiveStatus_Error" 1 "ActiveStatus_Active" 0 "ActiveStatus_NotActive" ;
VAL_ 2566850827 Trailer5RampLevelStorStat_ISig_3 3 "TrailerRampLevelStorStat_NotAvailable" 2 "TrailerRampLevelStorStat_Error" 1 "TrailerRampLevelStorStat_NewRampLevelStored" 0 "TrailerRampLevelStorStat_NoNewRampLevelStored" ;
VAL_ 2566850827 Trailer4LevelChangeRearAxle_ISig 3 "ActiveStatus_NotAvailable" 2 "ActiveStatus_Error" 1 "ActiveStatus_Active" 0 "ActiveStatus_NotActive" ;
VAL_ 2566850827 Trailer2LevelChangeFrontAxle_ISi 3 "ActiveStatus_NotAvailable" 2 "ActiveStatus_Error" 1 "ActiveStatus_Active" 0 "ActiveStatus_NotActive" ;
VAL_ 2566850827 Trailer2RampLevelStorStat_ISig_3 3 "TrailerRampLevelStorStat_NotAvailable" 2 "TrailerRampLevelStorStat_Error" 1 "TrailerRampLevelStorStat_NewRampLevelStored" 0 "TrailerRampLevelStorStat_NoNewRampLevelStored" ;
VAL_ 2566850827 Trailer4StopLevelChangeAck_ISig_ 3 "StopLevelChangeStatus_NotAvailable" 2 "StopLevelChangeStatus_ErrorIndicator" 1 "StopLevelChangeStatus_LevelChangedStopped" 0 "StopLevelChangeStatus_NoStopRequest" ;
VAL_ 2566850827 Trailer3NormalLevelStorStat_ISig 3 "TrailerNormalLevelStorStat_NotAvailable" 2 "TrailerNormalLevelStorStat_RideHeightNotStoredInReqSet" 1 "TrailerNormalLevelStorStat_NewRideHeightStored" 0 "TrailerNormalLevelStorStat_NoNewRideHeightStorageRequest" ;
VAL_ 2566850827 Trailer1TractionHelp_ISig_3 3 "InactiveActive_NotAvailable" 2 "InactiveActive_Error" 1 "InactiveActive_Active" 0 "InactiveActive_Inactive" ;
VAL_ 2566850827 Trailer1LevelChangeRearAxle_ISig 3 "ActiveStatus_NotAvailable" 2 "ActiveStatus_Error" 1 "ActiveStatus_Active" 0 "ActiveStatus_NotActive" ;
VAL_ 2566850827 Trailer5LevelChangeFrontAxle_ISi 3 "ActiveStatus_NotAvailable" 2 "ActiveStatus_Error" 1 "ActiveStatus_Active" 0 "ActiveStatus_NotActive" ;
VAL_ 2566850827 Trailer5StopLevelChangeAck_ISig_ 3 "StopLevelChangeStatus_NotAvailable" 2 "StopLevelChangeStatus_ErrorIndicator" 1 "StopLevelChangeStatus_LevelChangedStopped" 0 "StopLevelChangeStatus_NoStopRequest" ;
VAL_ 2566850827 Trailer5TractionHelp_ISig_3 3 "InactiveActive_NotAvailable" 2 "InactiveActive_Error" 1 "InactiveActive_Active" 0 "InactiveActive_Inactive" ;
VAL_ 2566850827 Trailer3RampLevelStorStat_ISig_3 3 "TrailerRampLevelStorStat_NotAvailable" 2 "TrailerRampLevelStorStat_Error" 1 "TrailerRampLevelStorStat_NewRampLevelStored" 0 "TrailerRampLevelStorStat_NoNewRampLevelStored" ;
VAL_ 2566850827 Trailer2LevelChangeRearAxle_ISig 3 "ActiveStatus_NotAvailable" 2 "ActiveStatus_Error" 1 "ActiveStatus_Active" 0 "ActiveStatus_NotActive" ;
VAL_ 2566850827 Trailer2StopLevelChangeAck_ISig_ 3 "StopLevelChangeStatus_NotAvailable" 2 "StopLevelChangeStatus_ErrorIndicator" 1 "StopLevelChangeStatus_LevelChangedStopped" 0 "StopLevelChangeStatus_NoStopRequest" ;
VAL_ 2566850827 Trailer3TractionHelp_ISig_3 3 "InactiveActive_NotAvailable" 2 "InactiveActive_Error" 1 "InactiveActive_Active" 0 "InactiveActive_Inactive" ;
VAL_ 2566850827 Trailer4RampLevelStorStat_ISig_3 3 "TrailerRampLevelStorStat_NotAvailable" 2 "TrailerRampLevelStorStat_Error" 1 "TrailerRampLevelStorStat_NewRampLevelStored" 0 "TrailerRampLevelStorStat_NoNewRampLevelStored" ;
VAL_ 2566850827 Trailer1RampLevelStorStat_ISig_3 3 "TrailerRampLevelStorStat_NotAvailable" 2 "TrailerRampLevelStorStat_Error" 1 "TrailerRampLevelStorStat_NewRampLevelStored" 0 "TrailerRampLevelStorStat_NoNewRampLevelStored" ;
VAL_ 2566850827 Trailer1LevelChangeFrontAxle_ISi 3 "ActiveStatus_NotAvailable" 2 "ActiveStatus_Error" 1 "ActiveStatus_Active" 0 "ActiveStatus_NotActive" ;
VAL_ 2566850827 Trailer3LevelChangeRearAxle_ISig 3 "ActiveStatus_NotAvailable" 2 "ActiveStatus_Error" 1 "ActiveStatus_Active" 0 "ActiveStatus_NotActive" ;
VAL_ 2566850827 Trailer5LevelChangeRearAxle_ISig 3 "ActiveStatus_NotAvailable" 2 "ActiveStatus_Error" 1 "ActiveStatus_Active" 0 "ActiveStatus_NotActive" ;
VAL_ 2566850827 Trailer2NormalLevelStorStat_ISig 3 "TrailerNormalLevelStorStat_NotAvailable" 2 "TrailerNormalLevelStorStat_RideHeightNotStoredInReqSet" 1 "TrailerNormalLevelStorStat_NewRideHeightStored" 0 "TrailerNormalLevelStorStat_NoNewRideHeightStorageRequest" ;
VAL_ 2566850827 Trailer4NormalLevelStorStat_ISig 3 "TrailerNormalLevelStorStat_NotAvailable" 2 "TrailerNormalLevelStorStat_RideHeightNotStoredInReqSet" 1 "TrailerNormalLevelStorStat_NewRideHeightStored" 0 "TrailerNormalLevelStorStat_NoNewRideHeightStorageRequest" ;
VAL_ 2566899211 Trailer4TowedVehStat_DetectStat 3 "TrailerDetectStat_NotAvailable" 2 "TrailerDetectStat_ErrorTrailerDetectionNotPossible" 1 "TrailerDetectStat_NoTowedVehicleDetected" 0 "TrailerDetectStat_TowedVehicleDeteted" ;
VAL_ 2566899211 Trailer5TowedVehStat_BrakeSystem 3 "BrakeSystem_NotAvailable" 2 "BrakeSystem_EBS" 1 "BrakeSystem_ABS" 0 "BrakeSystem_None" ;
VAL_ 2566899211 Trailer2TowedVehStat_DetectSupp 3 "TrailerDetectSupp_NotAvailable" 2 "TrailerDetectSupp_Error" 1 "TrailerDetectSupp_TrailerDetectionSupport" 0 "TrailerDetectSupp_NoTrailerDetectionSupport" ;
VAL_ 2566899211 Trailer1TowedVehStat_CANAvail 3 "CANAvail_NotAvailable" 2 "CANAvail_Error" 1 "CANAvail_CANInterfaceAvailable" 0 "CANAvail_NoCANInterfaceAvailable" ;
VAL_ 2566899211 Trailer2TowedVehStat_DetectStat 3 "TrailerDetectStat_NotAvailable" 2 "TrailerDetectStat_ErrorTrailerDetectionNotPossible" 1 "TrailerDetectStat_NoTowedVehicleDetected" 0 "TrailerDetectStat_TowedVehicleDeteted" ;
VAL_ 2566899211 Trailer2TowedVehStat_BrakeSystem 3 "BrakeSystem_NotAvailable" 2 "BrakeSystem_EBS" 1 "BrakeSystem_ABS" 0 "BrakeSystem_None" ;
VAL_ 2566899211 Trailer2TowedVehStat_CANAvail 3 "CANAvail_NotAvailable" 2 "CANAvail_Error" 1 "CANAvail_CANInterfaceAvailable" 0 "CANAvail_NoCANInterfaceAvailable" ;
VAL_ 2566899211 Trailer3TowedVehStat_BrakeSystem 3 "BrakeSystem_NotAvailable" 2 "BrakeSystem_EBS" 1 "BrakeSystem_ABS" 0 "BrakeSystem_None" ;
VAL_ 2566899211 Trailer3TowedVehStat_DetectStat 3 "TrailerDetectStat_NotAvailable" 2 "TrailerDetectStat_ErrorTrailerDetectionNotPossible" 1 "TrailerDetectStat_NoTowedVehicleDetected" 0 "TrailerDetectStat_TowedVehicleDeteted" ;
VAL_ 2566899211 Trailer5TowedVehStat_DetectSupp 3 "TrailerDetectSupp_NotAvailable" 2 "TrailerDetectSupp_Error" 1 "TrailerDetectSupp_TrailerDetectionSupport" 0 "TrailerDetectSupp_NoTrailerDetectionSupport" ;
VAL_ 2566899211 Trailer4TowedVehStat_DetectSupp 3 "TrailerDetectSupp_NotAvailable" 2 "TrailerDetectSupp_Error" 1 "TrailerDetectSupp_TrailerDetectionSupport" 0 "TrailerDetectSupp_NoTrailerDetectionSupport" ;
VAL_ 2566899211 Trailer5TowedVehStat_DetectStat 3 "TrailerDetectStat_NotAvailable" 2 "TrailerDetectStat_ErrorTrailerDetectionNotPossible" 1 "TrailerDetectStat_NoTowedVehicleDetected" 0 "TrailerDetectStat_TowedVehicleDeteted" ;
VAL_ 2566899211 Trailer3TowedVehStat_DetectSupp 3 "TrailerDetectSupp_NotAvailable" 2 "TrailerDetectSupp_Error" 1 "TrailerDetectSupp_TrailerDetectionSupport" 0 "TrailerDetectSupp_NoTrailerDetectionSupport" ;
VAL_ 2566899211 Trailer1TowedVehStat_DetectSupp 3 "TrailerDetectSupp_NotAvailable" 2 "TrailerDetectSupp_Error" 1 "TrailerDetectSupp_TrailerDetectionSupport" 0 "TrailerDetectSupp_NoTrailerDetectionSupport" ;
VAL_ 2566899211 Trailer4TowedVehStat_CANAvail 3 "CANAvail_NotAvailable" 2 "CANAvail_Error" 1 "CANAvail_CANInterfaceAvailable" 0 "CANAvail_NoCANInterfaceAvailable" ;
VAL_ 2566899211 Trailer1TowedVehStat_BrakeSystem 3 "BrakeSystem_NotAvailable" 2 "BrakeSystem_EBS" 1 "BrakeSystem_ABS" 0 "BrakeSystem_None" ;
VAL_ 2566899211 Trailer5TowedVehStat_CANAvail 3 "CANAvail_NotAvailable" 2 "CANAvail_Error" 1 "CANAvail_CANInterfaceAvailable" 0 "CANAvail_NoCANInterfaceAvailable" ;
VAL_ 2566899211 Trailer4TowedVehStat_BrakeSystem 3 "BrakeSystem_NotAvailable" 2 "BrakeSystem_EBS" 1 "BrakeSystem_ABS" 0 "BrakeSystem_None" ;
VAL_ 2566899211 Trailer1TowedVehStat_DetectStat 3 "TrailerDetectStat_NotAvailable" 2 "TrailerDetectStat_ErrorTrailerDetectionNotPossible" 1 "TrailerDetectStat_NoTowedVehicleDetected" 0 "TrailerDetectStat_TowedVehicleDeteted" ;
VAL_ 2566899211 Trailer3TowedVehStat_CANAvail 3 "CANAvail_NotAvailable" 2 "CANAvail_Error" 1 "CANAvail_CANInterfaceAvailable" 0 "CANAvail_NoCANInterfaceAvailable" ;
VAL_ 2566898955 Trailer5CalibInfo_DataStorage_IS 3 "TrailerCalibDataStore_AxleLoadCalibrationNotSupported" 2 "TrailerCalibDataStore_CalibrationAbortedTimeoutOrError" 1 "TrailerCalibDataStore_NewAxleLoadCalibDataStored" 0 "TrailerCalibDataStore_NoAxleLoadCalibrationDataStorageReq" ;
VAL_ 2566898955 Trailer5CalibInfo_CalibUsage_ISi 3 "CalibUsage_StoredCalibrationData_NOT_UsedForAxleLoadOutput" 2 "CalibUsage_spare2" 1 "CalibUsage_spare1" 0 "CalibUsage_StoredCalibrationDataUsedForAxleLoadOutput" ;
VAL_ 2566898955 Trailer5CalibInfo_LoadRange_ISig 3 "LoadRange_AxleLoadCalibrationNotSupported" 2 "LoadRange_AxleLoadCalibrationDataForMediumLoad" 1 "LoadRange_AxleLoadCalibrationDataForHeavyLoad" 0 "LoadRange_AxleLoadCalibrationDataForLowLoad" ;
VAL_ 2566898699 Trailer4CalibInfo_DataStorage_IS 3 "TrailerCalibDataStore_AxleLoadCalibrationNotSupported" 2 "TrailerCalibDataStore_CalibrationAbortedTimeoutOrError" 1 "TrailerCalibDataStore_NewAxleLoadCalibDataStored" 0 "TrailerCalibDataStore_NoAxleLoadCalibrationDataStorageReq" ;
VAL_ 2566898699 Trailer4CalibInfo_CalibUsage_ISi 3 "CalibUsage_StoredCalibrationData_NOT_UsedForAxleLoadOutput" 2 "CalibUsage_spare2" 1 "CalibUsage_spare1" 0 "CalibUsage_StoredCalibrationDataUsedForAxleLoadOutput" ;
VAL_ 2566898699 Trailer4CalibInfo_LoadRange_ISig 3 "LoadRange_AxleLoadCalibrationNotSupported" 2 "LoadRange_AxleLoadCalibrationDataForMediumLoad" 1 "LoadRange_AxleLoadCalibrationDataForHeavyLoad" 0 "LoadRange_AxleLoadCalibrationDataForLowLoad" ;
VAL_ 2566898443 Trailer3CalibInfo_CalibUsage_ISi 3 "CalibUsage_StoredCalibrationData_NOT_UsedForAxleLoadOutput" 2 "CalibUsage_spare2" 1 "CalibUsage_spare1" 0 "CalibUsage_StoredCalibrationDataUsedForAxleLoadOutput" ;
VAL_ 2566898443 Trailer3CalibInfo_LoadRange_ISig 3 "LoadRange_AxleLoadCalibrationNotSupported" 2 "LoadRange_AxleLoadCalibrationDataForMediumLoad" 1 "LoadRange_AxleLoadCalibrationDataForHeavyLoad" 0 "LoadRange_AxleLoadCalibrationDataForLowLoad" ;
VAL_ 2566898443 Trailer3CalibInfo_DataStorage_IS 3 "TrailerCalibDataStore_AxleLoadCalibrationNotSupported" 2 "TrailerCalibDataStore_CalibrationAbortedTimeoutOrError" 1 "TrailerCalibDataStore_NewAxleLoadCalibDataStored" 0 "TrailerCalibDataStore_NoAxleLoadCalibrationDataStorageReq" ;
SIG_GROUP_ 2566906891 Trailer4NomBodyLevel_sg_ISig_3 1 : Trailer4NomBodyLevel_FrontLevel_ Trailer4NomBodyLevel_RearLevel_I;
SIG_GROUP_ 2566906891 Trailer4PneumSupply_sg_ISig_3 1 : Trailer4PneumSupply_Pressure_ISi Trailer4PneumSupply_Status_ISig_;
SIG_GROUP_ 2566902283 Trailer3PneumSupply_sg_ISig_3 1 : Trailer3PneumSupply_Status_ISig_ Trailer3PneumSupply_Pressure_ISi;
SIG_GROUP_ 2566902283 Trailer3NomBodyLevel_sg_ISig_3 1 : Trailer3NomBodyLevel_RearLevel_I Trailer3NomBodyLevel_FrontLevel_;
SIG_GROUP_ 2566897419 Trailer2NomBodyLevel_sg_ISig_3 1 : Trailer2NomBodyLevel_RearLevel_I Trailer2NomBodyLevel_FrontLevel_;
SIG_GROUP_ 2566897419 Trailer2PneumSupply_sg_ISig_3 1 : Trailer2PneumSupply_Status_ISig_ Trailer2PneumSupply_Pressure_ISi;
SIG_GROUP_ 2566892811 Trailer1PneumSupply_sg_ISig_3 1 : Trailer1PneumSupply_Pressure_ISi Trailer1PneumSupply_Status_ISig_;
SIG_GROUP_ 2566892811 Trailer1NomBodyLevel_sg_ISig_3 1 : Trailer1NomBodyLevel_RearLevel_I Trailer1NomBodyLevel_FrontLevel_;
SIG_GROUP_ 2566887947 Trailer5TireInfoISO_sg_ISig_3 1 : Trailer5TireInfoISO_Pressure_ISi Trailer5TireInfoISO_Active_ISig_ Trailer5TireInfoISO_PowerSupply_ Trailer5TireInfoISO_Leakage_ISig Trailer5TireInfoISO_TireId_ISig_ Trailer5TireInfoISO_Temperature_ Trailer5TireInfoISO_Warning_ISig Trailer5TireInfoISO_PresSuff_ISi;
SIG_GROUP_ 2566883339 Trailer4TireInfoISO_sg_ISig_3 1 : Trailer4TireInfoISO_PresSuff_ISi Trailer4TireInfoISO_Pressure_ISi Trailer4TireInfoISO_Leakage_ISig Trailer4TireInfoISO_TireId_ISig_ Trailer4TireInfoISO_Active_ISig_ Trailer4TireInfoISO_PowerSupply_ Trailer4TireInfoISO_Temperature_ Trailer4TireInfoISO_Warning_ISig;
SIG_GROUP_ 2566878731 Trailer3TireInfoISO_sg_ISig_3 1 : Trailer3TireInfoISO_Warning_ISig Trailer3TireInfoISO_TireId_ISig_ Trailer3TireInfoISO_Active_ISig_ Trailer3TireInfoISO_Leakage_ISig Trailer3TireInfoISO_Pressure_ISi Trailer3TireInfoISO_PowerSupply_ Trailer3TireInfoISO_PresSuff_ISi Trailer3TireInfoISO_Temperature_;
SIG_GROUP_ 2566874123 Trailer2TireInfoISO_sg_ISig_3 1 : Trailer2TireInfoISO_PowerSupply_ Trailer2TireInfoISO_Leakage_ISig Trailer2TireInfoISO_Active_ISig_ Trailer2TireInfoISO_PresSuff_ISi Trailer2TireInfoISO_Temperature_ Trailer2TireInfoISO_Pressure_ISi Trailer2TireInfoISO_Warning_ISig Trailer2TireInfoISO_TireId_ISig_;
SIG_GROUP_ 2566869259 Trailer1TireInfoISO_sg_ISig_3 1 : Trailer1TireInfoISO_Warning_ISig Trailer1TireInfoISO_PowerSupply_ Trailer1TireInfoISO_PresSuff_ISi Trailer1TireInfoISO_Active_ISig_ Trailer1TireInfoISO_Leakage_ISig Trailer1TireInfoISO_Temperature_ Trailer1TireInfoISO_Pressure_ISi Trailer1TireInfoISO_TireId_ISig_;
SIG_GROUP_ 2566864651 Trailer4BrakeTemp_sg_ISig_3 1 : Trailer4BrakeTemp_TireId_ISig_3 Trailer4BrakeTemp_Status_ISig_3 Trailer4BrakeTemp_Temp_ISig_3;
SIG_GROUP_ 2566864651 Trailer5BrakeTemp_sg_ISig_3 1 : Trailer5BrakeTemp_Temp_ISig_3 Trailer5BrakeTemp_Status_ISig_3 Trailer5BrakeTemp_TireId_ISig_3;
SIG_GROUP_ 2566860043 Trailer2BrakeTemp_sg_ISig_3 1 : Trailer2BrakeTemp_TireId_ISig_3 Trailer2BrakeTemp_Status_ISig_3 Trailer2BrakeTemp_Temp_ISig_3;
SIG_GROUP_ 2566860043 Trailer1BrakeTemp_sg_ISig_3 1 : Trailer1BrakeTemp_Status_ISig_3 Trailer1BrakeTemp_TireId_ISig_3 Trailer1BrakeTemp_Temp_ISig_3;
SIG_GROUP_ 2566860043 Trailer3BrakeTemp_sg_ISig_3 1 : Trailer3BrakeTemp_Status_ISig_3 Trailer3BrakeTemp_Temp_ISig_3 Trailer3BrakeTemp_TireId_ISig_3;
SIG_GROUP_ 2566899211 Trailer4TowedVehStat_sg 1 : Trailer4TowedVehStat_DetectStat Trailer4TowedVehStat_DetectSupp Trailer4TowedVehStat_CANAvail Trailer4TowedVehStat_BrakeSystem;
SIG_GROUP_ 2566899211 Trailer1TowedVehStat_sg 1 : Trailer1TowedVehStat_CANAvail Trailer1TowedVehStat_DetectSupp Trailer1TowedVehStat_BrakeSystem Trailer1TowedVehStat_DetectStat;
SIG_GROUP_ 2566899211 Trailer3TowedVehStat_sg 1 : Trailer3TowedVehStat_BrakeSystem Trailer3TowedVehStat_DetectStat Trailer3TowedVehStat_DetectSupp Trailer3TowedVehStat_CANAvail;
SIG_GROUP_ 2566899211 Trailer2TowedVehStat_sg 1 : Trailer2TowedVehStat_DetectSupp Trailer2TowedVehStat_DetectStat Trailer2TowedVehStat_BrakeSystem Trailer2TowedVehStat_CANAvail;
SIG_GROUP_ 2566899211 Trailer5TowedVehStat_sg 1 : Trailer5TowedVehStat_BrakeSystem Trailer5TowedVehStat_DetectSupp Trailer5TowedVehStat_DetectStat Trailer5TowedVehStat_CANAvail;
SIG_GROUP_ 2566898955 Trailer5CalibInfo_sg_ISig_3 1 : Trailer5CalibInfo_ScaleLoad_ISig Trailer5CalibInfo_DataStorage_IS Trailer5CalibInfo_Year_ISig_3 Trailer5CalibInfo_Month_ISig_3 Trailer5CalibInfo_UncalibLoad_IS Trailer5CalibInfo_CalibUsage_ISi Trailer5CalibInfo_AxleId_ISig_3 Trailer5CalibInfo_LoadRange_ISig;
SIG_GROUP_ 2566898699 Trailer4CalibInfo_sg_ISig_3 1 : Trailer4CalibInfo_Month_ISig_3 Trailer4CalibInfo_DataStorage_IS Trailer4CalibInfo_CalibUsage_ISi Trailer4CalibInfo_ScaleLoad_ISig Trailer4CalibInfo_LoadRange_ISig Trailer4CalibInfo_Year_ISig_3 Trailer4CalibInfo_AxleId_ISig_3 Trailer4CalibInfo_UncalibLoad_IS;
SIG_GROUP_ 2566898443 Trailer3CalibInfo_sg_ISig_3 1 : Trailer3CalibInfo_ScaleLoad_ISig Trailer3CalibInfo_Month_ISig_3 Trailer3CalibInfo_AxleId_ISig_3 Trailer3CalibInfo_UncalibLoad_IS Trailer3CalibInfo_CalibUsage_ISi Trailer3CalibInfo_LoadRange_ISig Trailer3CalibInfo_DataStorage_IS Trailer3CalibInfo_Year_ISig_3;
